VERSION ""

NS_ :

BS_:

BU_: HPCBCM VCU ICU HPCGW IVI MCUM MCUS BMS EVCC DCDC OBC IBS GCU ECM TMS CCM PTC CLOUD GB

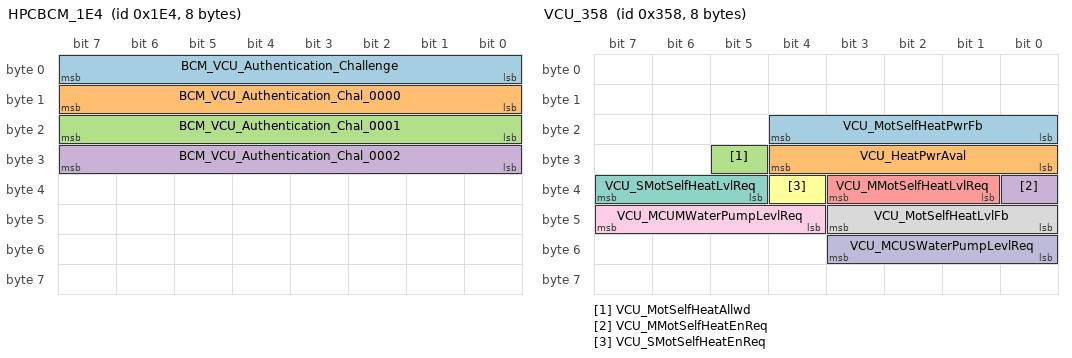
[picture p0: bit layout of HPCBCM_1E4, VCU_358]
BO_ 484 HPCBCM_1E4: 8 HPCBCM
 SG_ BCM_VCU_Authentication_Challenge : 0|8@1+ (1,0) [0|255] "-"  VCU
 SG_ BCM_VCU_Authentication_Chal_0000 : 8|8@1+ (1,0) [0|255] "-"  VCU
 SG_ BCM_VCU_Authentication_Chal_0001 : 16|8@1+ (1,0) [0|255] "-"  VCU
 SG_ BCM_VCU_Authentication_Chal_0002 : 24|8@1+ (1,0) [0|255] "-"  VCU

BO_ 485 VCU_1E5: 32 VCU
 SG_ VCU_BCM_Authentication_MAC_A0 : 0|8@1+ (1,0) [0|255] "-"  HPCBCM
 SG_ VCU_BCM_Authentication_MAC_A1 : 8|8@1+ (1,0) [0|255] "-"  HPCBCM
 SG_ VCU_BCM_Authentication_MAC_A2 : 16|8@1+ (1,0) [0|255] "-"  HPCBCM
 SG_ VCU_BCM_Authentication_MAC_A3 : 24|8@1+ (1,0) [0|255] "-"  HPCBCM
 SG_ VCU_BCM_Authentication_MAC_A4 : 32|8@1+ (1,0) [0|255] "-"  HPCBCM
 SG_ VCU_BCM_Authentication_MAC_A5 : 40|8@1+ (1,0) [0|255] "-"  HPCBCM
 SG_ VCU_BCM_Authentication_MAC_A6 : 48|8@1+ (1,0) [0|255] "-"  HPCBCM
 SG_ VCU_BCM_Authentication_MAC_A7 : 56|8@1+ (1,0) [0|255] "-"  HPCBCM
 SG_ VCU_BCM_Authentication_MAC_A8 : 64|8@1+ (1,0) [0|255] "-"  HPCBCM
 SG_ VCU_BCM_Authentication_MAC_A9 : 72|8@1+ (1,0) [0|255] "-"  HPCBCM
 SG_ VCU_BCM_Authentication_MAC_A10 : 80|8@1+ (1,0) [0|255] "-"  HPCBCM
 SG_ VCU_BCM_Authentication_MAC_A11 : 88|8@1+ (1,0) [0|255] "-"  HPCBCM
 SG_ VCU_BCM_Authentication_MAC_A12 : 96|8@1+ (1,0) [0|255] "-"  HPCBCM
 SG_ VCU_BCM_Authentication_MAC_A13 : 104|8@1+ (1,0) [0|255] "-"  HPCBCM
 SG_ VCU_BCM_Authentication_MAC_A14 : 112|8@1+ (1,0) [0|255] "-"  HPCBCM
 SG_ VCU_BCM_Authentication_MAC_A15 : 120|8@1+ (1,0) [0|255] "-"  HPCBCM
 SG_ VCU_BCM_Authentication_Challenge : 128|8@1+ (1,0) [0|255] "-"  HPCBCM
 SG_ VCU_BCM_Authentication_Chal_0000 : 136|8@1+ (1,0) [0|255] "-"  HPCBCM
 SG_ VCU_BCM_Authentication_Chal_0001 : 144|8@1+ (1,0) [0|255] "-"  HPCBCM
 SG_ VCU_BCM_Authentication_Chal_0002 : 152|8@1+ (1,0) [0|255] "-"  HPCBCM

BO_ 486 HPCBCM_1E6: 16 HPCBCM
 SG_ BCM_VCU_Authentication_MAC_B0 : 0|8@1+ (1,0) [0|255] "-"  VCU
 SG_ BCM_VCU_Authentication_MAC_B1 : 8|8@1+ (1,0) [0|255] "-"  VCU
 SG_ BCM_VCU_Authentication_MAC_B2 : 16|8@1+ (1,0) [0|255] "-"  VCU
 SG_ BCM_VCU_Authentication_MAC_B3 : 24|8@1+ (1,0) [0|255] "-"  VCU
 SG_ BCM_VCU_Authentication_MAC_B4 : 32|8@1+ (1,0) [0|255] "-"  VCU
 SG_ BCM_VCU_Authentication_MAC_B5 : 40|8@1+ (1,0) [0|255] "-"  VCU
 SG_ BCM_VCU_Authentication_MAC_B6 : 48|8@1+ (1,0) [0|255] "-"  VCU
 SG_ BCM_VCU_Authentication_MAC_B7 : 56|8@1+ (1,0) [0|255] "-"  VCU
 SG_ BCM_VCU_Authentication_MAC_B8 : 64|8@1+ (1,0) [0|255] "-"  VCU
 SG_ BCM_VCU_Authentication_MAC_B9 : 72|8@1+ (1,0) [0|255] "-"  VCU
 SG_ BCM_VCU_Authentication_MAC_B10 : 80|8@1+ (1,0) [0|255] "-"  VCU
 SG_ BCM_VCU_Authentication_MAC_B11 : 88|8@1+ (1,0) [0|255] "-"  VCU
 SG_ BCM_VCU_Authentication_MAC_B12 : 96|8@1+ (1,0) [0|255] "-"  VCU
 SG_ BCM_VCU_Authentication_MAC_B13 : 104|8@1+ (1,0) [0|255] "-"  VCU
 SG_ BCM_VCU_Authentication_MAC_B14 : 112|8@1+ (1,0) [0|255] "-"  VCU
 SG_ BCM_VCU_Authentication_MAC_B15 : 120|8@1+ (1,0) [0|255] "-"  VCU

BO_ 223 ICU_DF: 16 ICU
 SG_ ICU_CRC_DF : 0|8@1+ (1,0) [0|255] "-"  VCU
 SG_ ICU_RollingCounter_DF : 8|4@1+ (1,0) [0|15] "-"  VCU
 SG_ ICU_IMU_ACC_x : 16|16@1+ (0.00195313,-64) [-64|64] "m/s2"  VCU
 SG_ ICU_IMU_ACC_y : 32|16@1+ (0.00195313,-64) [-64|64] "m/s2"  VCU
 SG_ ICU_IMU_ACC_z : 48|16@1+ (0.00195313,-64) [-64|64] "m/s2"  VCU
 SG_ ICU_IMU_ACC_Roll_Rate : 64|16@1+ (0.01,-327.68) [-327.7|327.7] "deg/s"  VCU
 SG_ ICU_IMU_ACC_Pitch_Rate : 80|16@1+ (0.01,-327.68) [-327.7|327.7] "deg/s"  VCU
 SG_ ICU_IMU_ACC_Yaw_Rate : 96|16@1+ (0.01,-327.68) [-327.7|327.7] "deg/s"  VCU
 SG_ ICU_IMU_Calibrated : 112|2@1+ (1,0) [0|2] "-"  VCU
 SG_ ICU_IMU_Valid : 114|1@1+ (1,0) [0|1] "-"  VCU

BO_ 315 VCU_13B: 32 VCU
 SG_ VCU_CRC_13B : 0|8@1+ (1,0) [0|255] "-"  HPCGW,HPCBCM,MCUM,MCUS,BMS,DCDC,GCU,ECM,TMS,CCM,PTC
 SG_ VCU_RollingCounter_13B : 8|4@1+ (1,0) [0|15] "-"  HPCGW,HPCBCM,MCUM,MCUS,BMS,DCDC,GCU,ECM,TMS,CCM,PTC
 SG_ VCU_Vehicle_Warning : 16|2@1+ (1,0) [0|3] "-"  CLOUD,GB,HPCBCM,BMS
 SG_ VCU_VehicleSts : 18|1@1+ (1,0) [0|1] "-"  CLOUD,HPCGW,MCUM,MCUS,BMS,DCDC,GCU,ECM,TMS,PTC
 SG_ VCU_GearLevelPosSts : 19|2@1+ (1,0) [0|3] "-"  CLOUD,GB,HPCGW,MCUM,MCUS,ECM,TMS
 SG_ VCU_GearLeverValid : 21|1@1+ (1,0) [0|1] "-"  CLOUD,MCUM,MCUS,ECM
 SG_ VCU_AccPedalValid : 23|1@1+ (1,0) [0|1] "-"  CLOUD,HPCGW,MCUM,MCUS,ECM
 SG_ VCU_ThrottlePosition : 24|8@1+ (0.393,0) [0|100] "%"  CLOUD,GB,HPCGW,MCUM,MCUS,ECM
 SG_ VCU_BMSMainRelayR_Cmd : 32|1@1+ (1,0) [0|1] "-"  CLOUD,BMS
 SG_ VCU_BMSMainRelayF_Cmd : 33|1@1+ (1,0) [0|1] "-"  CLOUD,BMS
 SG_ VCU_BMSEmergencyCmd : 34|1@1+ (1,0) [0|1] "-"  CLOUD,BMS
 SG_ VCU_MCUMActiveReleaseCmd : 35|1@1+ (1,0) [0|1] "-"  CLOUD,MCUM
 SG_ VCU_MCUSActiveReleaseCmd : 36|1@1+ (1,0) [0|1] "-"  CLOUD,MCUS
 SG_ VCU_AlwACChargeInventerSts : 37|1@1+ (1,0) [0|1] "-"  CLOUD,BMS
 SG_ VCU_AlwDCChargeSts : 38|1@1+ (1,0) [0|1] "-"  CLOUD,BMS
 SG_ VCU_ChargePauseReq : 39|1@1+ (1,0) [0|1] "-"  CLOUD,BMS
 SG_ VCU_SuppressJitterMCUSRequest : 40|1@1+ (1,0) [0|1] "-"  CLOUD,MCUS
 SG_ VCU_DCDCEnableCmd : 41|1@1+ (1,0) [0|1] "-"  CLOUD,BMS,DCDC
 SG_ VCU_ACOffReq : 42|2@1+ (1,0) [0|3] "-"  CLOUD,TMS
 SG_ VCU_VehicleDirect : 44|1@1+ (1,0) [0|1] "-"  CLOUD,MCUM,MCUS
 SG_ VCU_BrakeSysFault : 45|1@1+ (1,0) [0|1] "-"  CLOUD,GB,HPCGW
 SG_ VCU_SuppressJitterMCUMRequest : 46|1@1+ (1,0) [0|1] "-"  CLOUD,MCUM
 SG_ VCU_MDrvControlMode : 47|1@1+ (1,0) [0|1] "-"  CLOUD,MCUM
 SG_ VCU_BrakePedalValue : 48|8@1+ (0.393,0) [0|100] "%"  CLOUD,MCUM,MCUS
 SG_ VCU_MCUMMaxDischargePower : 56|9@1+ (1,0) [0|510] "kw"  CLOUD,MCUM
 SG_ VCU_MCUMMaxChargePower : 71|9@1+ (1,0) [0|510] "kw"  CLOUD,MCUM
 SG_ VCU_MDrvRequestTorque : 80|16@1+ (0.1,-500) [-500|500] "N·m"  CLOUD,MCUM
 SG_ VCU_MDrvRequesSpeed : 96|16@1+ (1,-17000) [-17000|30000] "rpm"  CLOUD,MCUM
 SG_ VCU_SDrvRequestTorque : 112|16@1+ (0.1,-500) [-500|500] "N·m"  CLOUD,MCUM,MCUS
 SG_ VCU_SDrvRequesSpeed : 128|16@1+ (1,-17000) [-17000|30000] "rpm"  CLOUD,MCUM,MCUS
 SG_ VCU_SVehicleSts : 144|1@1+ (1,0) [0|1] "-"  CLOUD,MCUM,MCUS
 SG_ VCU_VehicleHighVoltModeF : 145|3@1+ (1,0) [0|7] "-"  CLOUD
 SG_ VCU_SDrvControlMode : 148|1@1+ (1,0) [0|1] "-"  CLOUD,MCUM,MCUS
 SG_ VCU_ON2BRelayReq : 149|2@1+ (1,0) [0|3] "-"  CLOUD,MCUM,MCUS
 SG_ VCU_VehPreHVPwrOffCmd : 151|1@1+ (1,0) [0|1] "-"  CLOUD,MCUM,MCUS,BMS,TMS,CCM,PTC
 SG_ VCU_FuelTankLockReq : 152|2@1+ (1,0) [0|3] "-"  CLOUD,HPCGW
 SG_ VCU_VehicleDirectS : 154|1@1+ (1,0) [0|1] "-"  CLOUD,MCUS
 SG_ VCU_VehicleDirectS_VD : 155|1@1+ (1,0) [0|1] "-"  CLOUD,MCUS
 SG_ VCU_ACPwrLimited : 160|8@1+ (0.1,0) [0|25.5] "kW"  CLOUD,TMS
 SG_ VCU_MCUSMaxDischargePower : 168|9@1+ (1,0) [0|510] "kw"  CLOUD,MCUS
 SG_ VCU_VehicleDirectVD : 177|1@1+ (1,0) [0|1] "-"  CLOUD,MCUM,MCUS
 SG_ VCU_MDrvControlModeVD : 178|1@1+ (1,0) [0|1] "-"  CLOUD,MCUM,MCUS
 SG_ VCU_MDrvRequestTorqueVD : 179|1@1+ (1,0) [0|1] "-"  CLOUD,MCUM,MCUS
 SG_ VCU_MDrvRequesSpeedVD : 180|1@1+ (1,0) [0|1] "-"  CLOUD,MCUM,MCUS
 SG_ VCU_SDrvRequestTorqueVD : 181|1@1+ (1,0) [0|1] "-"  CLOUD,MCUM,MCUS
 SG_ VCU_SDrvRequesSpeedVD : 182|1@1+ (1,0) [0|1] "-"  CLOUD,MCUM,MCUS
 SG_ VCU_SDrvControlModeVD : 183|1@1+ (1,0) [0|1] "-"  CLOUD,MCUM,MCUS
 SG_ VCU_MCUSMaxChargePower : 184|9@1+ (1,0) [0|510] "kw"  CLOUD,MCUS
 SG_ VCU_VehicleHighVoltMode : 193|3@1+ (1,0) [0|7] "-"  CLOUD,ICU
 SG_ VCU_PDUHVIL_Sts : 196|1@1+ (1,0) [0|1] "-"  CLOUD
 SG_ VCU_PDU220VRelay_Req : 197|1@1+ (1,0) [0|1] "-"  CLOUD,HPCGW
 SG_ VCU_Cab220VRelay_Req : 198|1@1+ (1,0) [0|1] "-"  CLOUD,HPCGW
 SG_ VCU_Cabin220VRelay_Req : 199|1@1+ (1,0) [0|1] "-"  CLOUD,HPCGW
 SG_ VCU_Alw_Cab220VInverter_Sts : 200|1@1+ (1,0) [0|1] "-"  CLOUD,BMS
 SG_ VCU_Alw_Cabin220VInverter_Sts : 201|1@1+ (1,0) [0|1] "-"  CLOUD,BMS
 SG_ VCU_MCUMDampgLmtFactor : 202|7@1+ (1,0) [0|100] "%"  CLOUD,MCUM
 SG_ VCU_MCUSDampgLmtFactor : 209|7@1+ (1,0) [0|100] "%"  CLOUD,MCUS
 SG_ VCU_BCM_Authentication_Sts : 216|2@1+ (1,0) [0|3] "-"  CLOUD
 SG_ VCU_AuthenticationKey_WSts : 218|1@1+ (1,0) [0|1] "-"  CLOUD
 SG_ VCU_BrakePedalSts_P : 219|1@1+ (1,0) [0|1] "-"  CLOUD
 SG_ VCU_BrakePedalStsValid_P : 220|1@1+ (1,0) [0|1] "-"  CLOUD
 SG_ VCU_BoostMode_Fail : 221|3@1+ (1,0) [0|7] "-"  CLOUD,MCUM,BMS,TMS
 SG_ VCU_BoostModeSts : 224|2@1+ (1,0) [0|3] "-"  CLOUD,MCUM,BMS,TMS
 SG_ VCU_MCUSMaxPosDampgTrq : 232|6@1+ (1,0) [0|50] "Nm"  CLOUD,MCUS
 SG_ VCU_MCUSMaxNegDampgTrq : 238|6@1+ (1,-50) [-50|0] "Nm"  CLOUD,MCUS
 SG_ VCU_MCUMMaxPosDampgTrq : 244|6@1+ (1,0) [0|50] "Nm"  CLOUD,MCUM
 SG_ VCU_MCUMMaxNegDampgTrq : 250|6@1+ (1,-50) [-50|0] "Nm"  CLOUD,MCUM

BO_ 188 VCU_BC: 16 VCU
 SG_ VCU_VehicleSpdDirect : 16|9@1+ (1,-255) [-255|255] "-"  CLOUD
 SG_ VCU_DeliveryModeSts : 25|1@1+ (1,0) [0|1] "-"  CLOUD,IVI,BMS
 SG_ VCU_VehSpdLimtRemind : 26|1@1+ (1,0) [0|1] "-"  CLOUD
 SG_ VCU_SinglePedalSts : 27|1@1+ (1,0) [0|1] "-"  CLOUD
 SG_ VCU_GearLvrChangeSts : 28|4@1+ (1,0) [0|15] "-"  CLOUD
 SG_ VCU_HighVoltSysSts : 32|4@1+ (1,0) [0|15] "-"  CLOUD
 SG_ VCU_ChrgDischrgFunSts : 36|4@1+ (1,0) [0|15] "-"  CLOUD
 SG_ VCU_CalibrationVersion : 40|4@1+ (1,0) [0|15] "-"  CLOUD
 SG_ VCU_CalibrationNumber : 44|3@1+ (1,0) [0|7] "-"  CLOUD
 SG_ VCU_VehicleNegTrqRspdSts : 47|1@1+ (1,0) [0|1] "-"  CLOUD
 SG_ VCU_SlopeEst : 48|10@1+ (0.5,-100) [-100|100] "%"  CLOUD
 SG_ VCU_SlopeEst_Valid : 58|1@1+ (1,0) [0|1] "-"  CLOUD
 SG_ VCU_WheelTrqType : 60|4@1+ (1,0) [0|15] "-"  CLOUD
 SG_ VCU_DriverAssistProhibitSts : 64|1@1+ (1,0) [0|1] "-"  CLOUD
 SG_ VCU_VacumRlySts : 65|1@1+ (1,0) [0|1] "-"  CLOUD
 SG_ VCU_DriveSHVILSts : 66|1@1+ (1,0) [0|1] "-"  CLOUD
 SG_ VCU_DriveMHVILSts : 67|1@1+ (1,0) [0|1] "-"  CLOUD
 SG_ VCU_DCChgHVILSts : 68|1@1+ (1,0) [0|1] "-"  CLOUD
 SG_ VCU_ACChgHVILSts : 69|1@1+ (1,0) [0|1] "-"  CLOUD
 SG_ VCU_CCMHVILSts : 70|1@1+ (1,0) [0|1] "-"  CLOUD
 SG_ VCU_SystemError : 71|1@1+ (1,0) [0|1] "-"  CLOUD
 SG_ VCU_AccPedalFaultLV : 72|3@1+ (1,0) [0|7] "-"  CLOUD
 SG_ VCU_HVILSysSts : 76|4@1+ (1,0) [0|15] "-"  CLOUD
 SG_ VCU_VacuumDegree : 80|8@1+ (0.393,0) [0|100] "%"  CLOUD
 SG_ VCU_LPedalModeSts : 88|2@1+ (1,0) [0|3] "-"  CLOUD
 SG_ VCU_LVSystemError : 90|1@1+ (1,0) [0|1] "-"  CLOUD
 SG_ VCU_HVSystemError : 91|1@1+ (1,0) [0|1] "-"  CLOUD
 SG_ VCU_OpeartingMode : 92|2@1+ (1,0) [0|3] "-"  CLOUD
 SG_ VCU_EnergyMode : 94|3@1+ (1,0) [0|7] "-"  CLOUD,GB,HPCGW
 SG_ VCU_GearLevelPosFault : 97|1@1+ (1,0) [0|1] "-"  CLOUD
 SG_ VCU_BrakeSwitchSts : 98|2@1+ (1,0) [0|3] "-"  CLOUD
 SG_ VCU_SpdLimModeSts : 100|2@1+ (1,0) [0|3] "-"  CLOUD,IVI
 SG_ VCU_TrqDstrbutnPrio : 102|3@1+ (1,0) [0|7] "-"  CLOUD
 SG_ VCU_TrqDstrbutnTransferSts : 105|3@1+ (1,0) [0|7] "-"  CLOUD
 SG_ VCU_MCUMDiffProtectSts : 108|1@1+ (1,0) [0|1] "-"  CLOUD
 SG_ VCU_MCUSDiffProtectSts : 109|1@1+ (1,0) [0|1] "-"  CLOUD
 SG_ VCU_ADM_MainMode : 110|2@1+ (1,0) [0|3] "-"  CLOUD
 SG_ VCU_ADM_ActualMode : 112|2@1+ (1,0) [0|3] "-"  CLOUD

BO_ 856 VCU_358: 8 VCU
 SG_ VCU_MotSelfHeatPwrFb : 16|5@1+ (1,0) [0|31] "kw"  CLOUD,TMS
 SG_ VCU_HeatPwrAval : 24|5@1+ (1,0) [0|31] "kw"  CLOUD,TMS
 SG_ VCU_MotSelfHeatAllwd : 29|1@1+ (1,0) [0|1] "-"  CLOUD,TMS
 SG_ VCU_MMotSelfHeatEnReq : 32|1@1+ (1,0) [0|1] "-"  CLOUD,MCUM
 SG_ VCU_MMotSelfHeatLvlReq : 33|3@1+ (1,0) [0|7] "-"  CLOUD,MCUM
 SG_ VCU_SMotSelfHeatEnReq : 36|1@1+ (1,0) [0|1] "-"  CLOUD,MCUS
 SG_ VCU_SMotSelfHeatLvlReq : 37|3@1+ (1,0) [0|7] "-"  CLOUD,MCUS
 SG_ VCU_MotSelfHeatLvlFb : 40|4@1+ (1,0) [0|15] "-"  CLOUD,TMS
 SG_ VCU_MCUMWaterPumpLevlReq : 44|4@1+ (10,0) [0|100] "%"  CLOUD,MCUM
 SG_ VCU_MCUSWaterPumpLevlReq : 48|4@1+ (10,0) [0|100] "%"  CLOUD,MCUS

BO_ 1300 VCU_514: 8 VCU
 SG_ VCU_FuelConsumption : 0|8@1+ (4,0) [0|1020] "ul/100ms"  CLOUD,IVI
 SG_ VCU_SVSLamp : 8|1@1+ (1,0) [0|1] "-"  CLOUD,IVI
 SG_ VCU_MilLamp : 9|1@1+ (1,0) [0|1] "-"  CLOUD,IVI,ICU
 SG_ VCU_SinglePedalSts : 10|1@1+ (1,0) [0|1] "-"  CLOUD,ICU
 SG_ VCU_GearLevelPosFault : 11|1@1+ (1,0) [0|1] "-"  CLOUD,ICU
 SG_ VCU_EngineStartFailure : 12|1@1+ (1,0) [0|1] "-"  CLOUD,IVI,ICU,ECM
 SG_ VCU_ParkBeforeFuelup : 13|1@1+ (1,0) [0|1] "-"  CLOUD,IVI,ICU
 SG_ VCU_REsystemFaultSts : 14|1@1+ (1,0) [0|1] "-"  CLOUD,IVI,ICU
 SG_ VCU_EngineRunAllowFlg : 15|1@1+ (1,0) [0|1] "-"  CLOUD,IVI
 SG_ VCU_InverterTip : 16|3@1+ (1,0) [0|7] "-"  CLOUD,IVI,ICU
 SG_ VCU_EMSRepairModeSts : 19|2@1+ (1,0) [0|3] "-"  CLOUD,IVI,ICU
 SG_ VCU_FuelTankFlapSts : 21|1@1+ (1,0) [0|1] "-"  CLOUD,IVI,ICU
 SG_ VCU_REsystemSts : 22|1@1+ (1,0) [0|1] "-"  CLOUD,IVI
 SG_ VCU_PowerModeAllow : 23|2@1+ (1,0) [0|3] "-"  CLOUD,IVI
 SG_ VCU_PowerModeSwitchMsg : 25|1@1+ (1,0) [0|1] "-"  CLOUD,IVI
 SG_ VCU_HighVoltFailed_M : 26|1@1+ (1,0) [0|1] "-"  CLOUD,IVI
 SG_ VCU_HighVoltFailed_S : 27|1@1+ (1,0) [0|1] "-"  CLOUD,IVI
 SG_ VCU_BrakeBeforeGear : 28|1@1+ (1,0) [0|1] "-"  CLOUD,IVI,ICU
 SG_ VCU_ParkBeforeGear : 29|1@1+ (1,0) [0|1] "-"  CLOUD,IVI,ICU
 SG_ VCU_GearBeforDriving : 30|1@1+ (1,0) [0|1] "-"  CLOUD,IVI,ICU
 SG_ VCU_UnlockBeforeDriving : 31|1@1+ (1,0) [0|1] "-"  CLOUD,IVI,ICU
 SG_ VCU_PreventSliding : 32|1@1+ (1,0) [0|1] "-"  CLOUD,IVI,ICU
 SG_ VCU_MMErrorSts : 33|1@1+ (1,0) [0|1] "-"  CLOUD,IVI
 SG_ VCU_ShowCarModeSts : 34|1@1+ (1,0) [0|1] "-"  CLOUD,IVI,ICU
 SG_ VCU_PGearFlashSts : 35|1@1+ (1,0) [0|1] "-"  CLOUD,IVI,ICU
 SG_ VCU_ACConnectSts : 36|1@1+ (1,0) [0|1] "-"  CLOUD,IVI,ICU
 SG_ VCU_DcChgPwrSts : 37|1@1+ (1,0) [0|1] "-"  CLOUD,IVI
 SG_ VCU_DriverAssistProhibitSts : 38|1@1+ (1,0) [0|1] "-"  CLOUD
 SG_ VCU_MilLampRequest : 39|1@1+ (1,0) [0|1] "-"  CLOUD
 SG_ VCU_CcmHvilInSigFreq_FB : 40|8@1+ (1,0) [0|200] "Hz"  CLOUD
 SG_ VCU_CcmHvilInSigDuty_FB : 48|8@1+ (1,0) [0|100] "pct"  CLOUD
 SG_ VCU_FuelDectionModeSts : 56|2@1+ (1,0) [0|3] "-"  CLOUD,IVI,ICU
 SG_ VCU_EnergyCtrlMode : 58|1@1+ (1,0) [0|1] "-"  CLOUD,IVI,ICU
 SG_ VCU_VehSpdLimtRemind : 59|1@1+ (1,0) [0|1] "-"  CLOUD,ICU
 SG_ VCU_TurtleLamp : 60|1@1+ (1,0) [0|1] "-"  CLOUD,ICU
 SG_ VCU_EngLongTimeStartReq : 61|1@1+ (1,0) [0|1] "-"  CLOUD,IVI

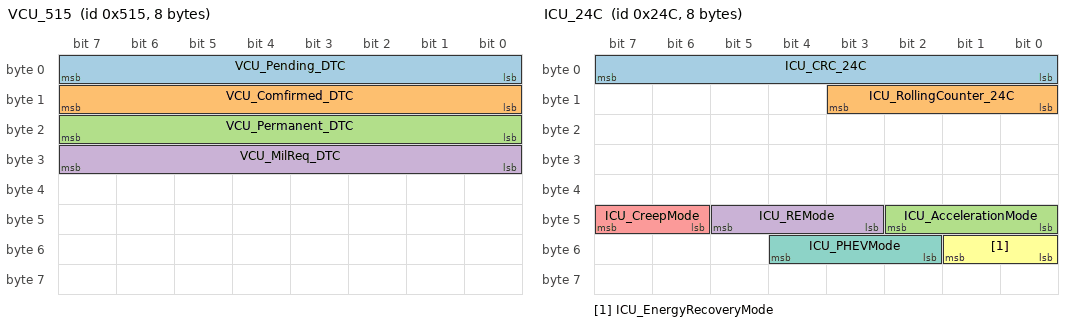
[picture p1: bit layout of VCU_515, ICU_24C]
BO_ 1301 VCU_515: 8 VCU
 SG_ VCU_Pending_DTC : 0|8@1+ (1,0) [0|254] "-"  CLOUD
 SG_ VCU_Comfirmed_DTC : 8|8@1+ (1,0) [0|254] "-"  CLOUD
 SG_ VCU_Permanent_DTC : 16|8@1+ (1,0) [0|254] "-"  CLOUD
 SG_ VCU_MilReq_DTC : 24|8@1+ (1,0) [0|254] "-"  CLOUD

BO_ 588 ICU_24C: 8 ICU
 SG_ ICU_CRC_24C : 0|8@1+ (1,0) [0|255] "-"  VCU,MCUM,MCUS,BMS,GCU,ECM,TMS
 SG_ ICU_RollingCounter_24C : 8|4@1+ (1,0) [0|15] "-"  VCU,MCUM,MCUS,BMS,GCU,ECM,TMS
 SG_ ICU_AccelerationMode : 40|3@1+ (1,0) [0|7] "-"  CLOUD,VCU,MCUM,MCUS,TMS
 SG_ ICU_REMode : 43|3@1+ (1,0) [0|7] "-"  CLOUD,IVI,VCU,BMS
 SG_ ICU_CreepMode : 46|2@1+ (1,0) [0|3] "-"  VCU
 SG_ ICU_EnergyRecoveryMode : 48|2@1+ (1,0) [0|3] "-"  VCU
 SG_ ICU_PHEVMode : 50|3@1+ (1,0) [0|7] "-"  IVI,VCU

BO_ 585 ICU_249: 64 ICU
 SG_ ICU_TotalOilmeterkm : 44|20@1+ (1,0) [0|999999] "km"  VCU
 SG_ ICU_CLTCoilMileage : 64|11@1+ (1,0) [0|2000] "km"  VCU
 SG_ ICU_WLTC_oilMileage : 75|11@1+ (1,0) [0|2000] "km"  VCU
 SG_ ICU_CLTC_ElectticityMileage : 86|11@1+ (1,0) [0|2000] "km"  VCU
 SG_ ICU_WLTC_ElectticityMileage : 97|11@1+ (1,0) [0|2000] "km"  VCU
 SG_ ICU_Switch_CLTCOrWLTC : 128|3@1+ (1,0) [0|7] "-"  VCU
 SG_ ICU_FuelPercent : 135|10@1+ (0.1,0) [0|100] "%"  VCU

BO_ 657 HPCBCM_291: 16 HPCBCM
 SG_ BCM_CRC_291 : 0|8@1+ (1,0) [0|255] "-"  VCU,MCUM,MCUS,BMS,GCU,ECM,IBS,TMS
 SG_ BCM_RollingCounter_291 : 8|4@1+ (1,0) [0|15] "-"  VCU,MCUM,MCUS,BMS,GCU,ECM,IBS,TMS
 SG_ BCM_ShutdownMode : 15|1@1+ (1,0) [0|1] " -"  VCU
 SG_ BCM_KeyPosition_ON2A : 18|1@1+ (1,0) [0|1] "-"  VCU,MCUM,MCUS,BMS,GCU,ECM
 SG_ BCM_CcmHvilSts : 22|1@1+ (1,0) [0|1] "-"  VCU
 SG_ BCM_ON2BRelaySts : 30|1@1+ (1,0) [0|1] "-"  VCU,MCUM,MCUS
 SG_ BCM_ON2CRelaySts : 31|1@1+ (1,0) [0|1] "-"  VCU,MCUM,MCUS
 SG_ BCM_ON2InitiativeSts : 35|1@1+ (1,0) [0|1] "-"  VCU
 SG_ BCM_VehicleRepairMode : 36|1@1+ (1,0) [0|1] "-"  VCU
 SG_ BCM_VehlockCtrl : 37|2@1+ (1,0) [0|3] "-"  VCU
 SG_ BCM_VehLockSts : 39|1@1+ (1,0) [0|1] "-"  VCU,TMS
 SG_ BCM_FuelTankLockReq : 40|2@1+ (1,0) [0|3] "-"  VCU
 SG_ BCM_ACChgLockCtrl : 42|2@1+ (1,0) [0|3] "-"  VCU
 SG_ BCM_ChargeLockCtrl : 44|2@1+ (1,0) [0|3] "-"  VCU
 SG_ BCM_DCChrgPwr_Sts : 46|1@1+ (1,0) [0|1] "-"  VCU
 SG_ BCM_ACChrgPwr_Sts : 47|1@1+ (1,0) [0|1] "-"  VCU
 SG_ BCM_DCChrgPwr_Volt : 48|8@1+ (0.2,0) [0|51] "-"  VCU
 SG_ BCM_ACChrgPwr_Volt : 56|8@1+ (0.2,0) [0|51] "-"  VCU
 SG_ BCM_KeyPosition_ON2B : 64|1@1+ (1,0) [0|1] "-"  VCU,MCUM,MCUS,GCU,TMS
 SG_ BCM_NM_PNC_ON_1ADr_Sts : 67|1@1+ (1,0) [0|1] "-"  VCU,TMS
 SG_ BCM_NM_PNC_ON_3Ch_Sts : 73|1@1+ (1,0) [0|1] "-"  VCU,BMS,TMS
 SG_ BCM_HighVoltageReq : 114|2@1+ (1,0) [0|3] " -"  CLOUD,VCU

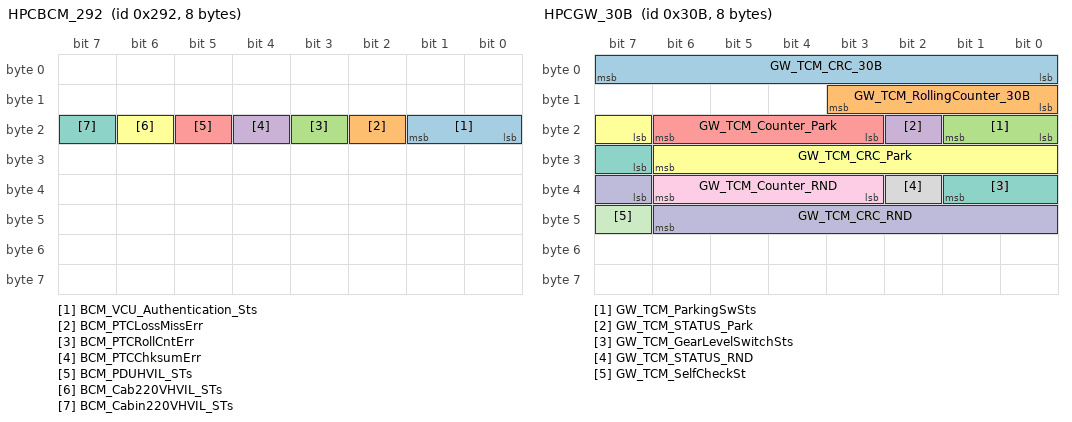
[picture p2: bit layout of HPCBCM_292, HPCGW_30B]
BO_ 658 HPCBCM_292: 8 HPCBCM
 SG_ BCM_VCU_Authentication_Sts : 16|2@1+ (1,0) [0|3] "-"  CLOUD,VCU
 SG_ BCM_PTCLossMissErr : 18|1@1+ (1,0) [0|1] "-"  CLOUD,VCU
 SG_ BCM_PTCRollCntErr : 19|1@1+ (1,0) [0|1] "-"  CLOUD,VCU
 SG_ BCM_PTCChksumErr : 20|1@1+ (1,0) [0|1] "-"  CLOUD,VCU
 SG_ BCM_PDUHVIL_STs : 21|1@1+ (1,0) [0|1] "-"  CLOUD,VCU
 SG_ BCM_Cab220VHVIL_STs : 22|1@1+ (1,0) [0|1] "-"  CLOUD,VCU
 SG_ BCM_Cabin220VHVIL_STs : 23|1@1+ (1,0) [0|1] "-"  CLOUD,VCU

BO_ 945 HPCGW_3B1: 32 HPCGW
 SG_ GW_CRC_3B1 : 0|8@1+ (1,0) [0|255] "-"  VCU,MCUM,MCUS,BMS,ECM
 SG_ GW_RollingCounter_3B1 : 8|4@1+ (1,0) [0|15] "-"  VCU,MCUM,MCUS,BMS,ECM
 SG_ GW_ZCUB_DCChgExitTemp_Pos : 56|8@1+ (1,-40) [-40|210] "℃"  VCU,BMS
 SG_ GW_ZCUB_DCChgExitTemp_Neg : 64|8@1+ (1,-40) [-40|210] "℃"  VCU,BMS
 SG_ GW_ZCUB_ACChgExitTemp_Pos : 72|8@1+ (1,-40) [-40|210] "℃"  VCU,BMS
 SG_ GW_ZCUB_FuelTankSts : 94|1@1+ (1,0) [0|1] "-"  VCU,ECM
 SG_ GW_ZCUB_ACChgExitTemp_Neg : 152|8@1+ (1,-40) [-40|210] "℃"  VCU,BMS
 SG_ GW_ZCUB_FuelTankStsLockSts : 204|2@1+ (1,0) [0|3] "-"  VCU
 SG_ GW_ZCUB_FuelTankLockCtrl : 206|2@1+ (1,0) [0|3] "-"  VCU
 SG_ GW_ZCUB_ACChgLockSts : 208|2@1+ (1,0) [0|3] "-"  VCU,BMS
 SG_ GW_RZCU_Cabin_220Vconnect_Sts : 210|1@1+ (1,0) [0|1] "-"  VCU,BMS
 SG_ GW_ZCUB_Cab_220VRelay_CtrlSts : 211|1@1+ (1,0) [0|1] "-"  VCU
 SG_ GW_ZCUB_Cab_PDU220VRelay_CtrlSts : 212|1@1+ (1,0) [0|1] "-"  VCU
 SG_ GW_ZCUB_Cabin_220VRelay_CtrlSts : 213|1@1+ (1,0) [0|1] "-"  VCU
 SG_ GW_ZCUB_Cab_220Vconnect_Sts : 214|1@1+ (1,0) [0|1] "-"  VCU,BMS
 SG_ GW_TBOXSOC_Altitude : 236|14@1+ (1,-1000) [-1000|10000] "m"  VCU

BO_ 779 HPCGW_30B: 8 HPCGW
 SG_ GW_TCM_CRC_30B : 0|8@1+ (1,0) [0|255] "-"  VCU
 SG_ GW_TCM_RollingCounter_30B : 8|4@1+ (1,0) [0|15] "-"  VCU
 SG_ GW_TCM_ParkingSwSts : 16|2@1+ (1,0) [0|3] "-"  VCU
 SG_ GW_TCM_STATUS_Park : 18|1@1+ (1,0) [0|1] "-"  VCU
 SG_ GW_TCM_Counter_Park : 19|4@1+ (1,0) [0|15] "-"  VCU
 SG_ GW_TCM_CRC_Park : 23|8@1+ (1,0) [0|255] "-"  VCU
 SG_ GW_TCM_GearLevelSwitchSts : 31|3@1+ (1,0) [0|7] "-"  VCU
 SG_ GW_TCM_STATUS_RND : 34|1@1+ (1,0) [0|1] "-"  VCU
 SG_ GW_TCM_Counter_RND : 35|4@1+ (1,0) [0|15] "-"  VCU
 SG_ GW_TCM_CRC_RND : 39|8@1+ (1,0) [0|255] "-"  VCU
 SG_ GW_TCM_SelfCheckSt : 47|1@1+ (1,0) [0|1] "-"  VCU

BO_ 842 IVI_34A: 8 IVI
 SG_ IVI_DeliveryModeReq : 20|2@1+ (1,0) [0|3] "-"  VCU
 SG_ IVI_ShowCarModeReq : 22|2@1+ (1,0) [0|3] "-"  VCU

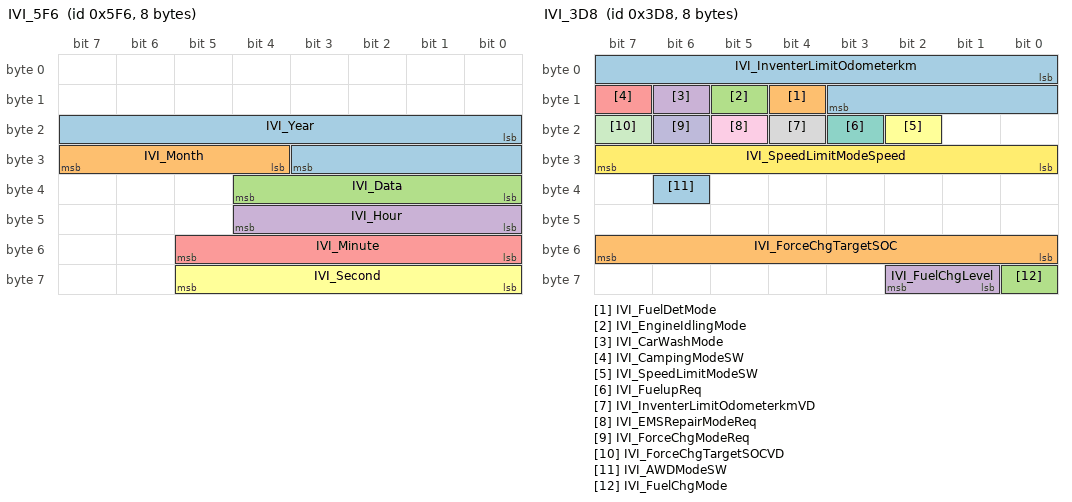
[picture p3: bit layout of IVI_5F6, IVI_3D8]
BO_ 1526 IVI_5F6: 8 IVI
 SG_ IVI_Year : 16|12@1+ (1,0) [0|4094] "-"  VCU,MCUM,MCUS,BMS,GCU,ECM,IBS,TMS
 SG_ IVI_Month : 28|4@1+ (1,0) [0|12] "-"  VCU,MCUM,MCUS,BMS,GCU,ECM,IBS,TMS
 SG_ IVI_Data : 32|5@1+ (1,0) [0|31] "-"  VCU,MCUM,MCUS,BMS,GCU,ECM,IBS,TMS
 SG_ IVI_Hour : 40|5@1+ (1,0) [0|23] "-"  VCU,MCUM,MCUS,BMS,GCU,ECM,IBS,TMS
 SG_ IVI_Minute : 48|6@1+ (1,0) [0|59] "-"  VCU,MCUM,MCUS,BMS,GCU,ECM,IBS,TMS
 SG_ IVI_Second : 56|6@1+ (1,0) [0|59] "-"  VCU,MCUM,MCUS,BMS,GCU,ECM,IBS,TMS

BO_ 984 IVI_3D8: 8 IVI
 SG_ IVI_InventerLimitOdometerkm : 0|12@1+ (1,0) [0|4000] "km"  VCU
 SG_ IVI_FuelDetMode : 12|1@1+ (1,0) [0|1] "-"  VCU
 SG_ IVI_EngineIdlingMode : 13|1@1+ (1,0) [0|1] "-"  VCU
 SG_ IVI_CarWashMode : 14|1@1+ (1,0) [0|1] "-"  VCU
 SG_ IVI_CampingModeSW : 15|1@1+ (1,0) [0|1] "-"  VCU
 SG_ IVI_SpeedLimitModeSW : 18|1@1+ (1,0) [0|1] "-"  VCU
 SG_ IVI_FuelupReq : 19|1@1+ (1,0) [0|1] "-"  VCU
 SG_ IVI_InventerLimitOdometerkmVD : 20|1@1+ (1,0) [0|1] "-"  VCU
 SG_ IVI_EMSRepairModeReq : 21|1@1+ (1,0) [0|1] "-"  VCU
 SG_ IVI_ForceChgModeReq : 22|1@1+ (1,0) [0|1] "-"  VCU
 SG_ IVI_ForceChgTargetSOCVD : 23|1@1+ (1,0) [0|1] "-"  VCU
 SG_ IVI_SpeedLimitModeSpeed : 24|8@1+ (1,0) [1|180] "KM"  VCU
 SG_ IVI_AWDModeSW : 38|1@1+ (1,0) [0|1] "-"  VCU
 SG_ IVI_ForceChgTargetSOC : 48|8@1+ (1,0) [0|100] "%"  VCU
 SG_ IVI_FuelChgMode : 56|1@1+ (1,0) [0|1] "-"  CLOUD,VCU
 SG_ IVI_FuelChgLevel : 57|2@1+ (1,0) [0|3] "-"  CLOUD,VCU

BO_ 202 MCUM_CA: 32 MCUM
 SG_ MCUM_CRC_CA : 0|8@1+ (1,0) [0|255] "-"  HPCGW,ICU,VCU,BMS,TMS
 SG_ MCUM_RollingCounter_CA : 8|4@1+ (1,0) [0|15] "-"  HPCGW,ICU,VCU,BMS,TMS
 SG_ MCUM_WarningLevel : 16|2@1+ (1,0) [0|3] "-"  CLOUD,IVI,ICU,VCU
 SG_ MCUM_SelfCheckSts : 18|2@1+ (1,0) [0|3] "-"  CLOUD,ICU,VCU
 SG_ MCUM_DrvMotorWorkSts : 20|2@1+ (1,0) [0|3] "-"  CLOUD,GB,HPCGW,VCU
 SG_ MCUM_PowerReduceSts : 22|1@1+ (1,0) [0|1] "-"  CLOUD,VCU
 SG_ MCUM_DrvMotorRPM : 24|16@1+ (1,-17000) [-17000|30000] "rpm"  CLOUD,GB,HPCGW,ICU,VCU
 SG_ MCUM_ActualTorqueFB : 40|16@1+ (0.1,-500) [-500|500] "N·m"  CLOUD,GB,HPCGW,VCU
 SG_ MCUM_HWRdcFault : 56|1@1+ (1,0) [0|1] "-"  CLOUD,HPCGW,ICU,VCU
 SG_ MCUM_HighVoltPowerOffReq : 58|1@1+ (1,0) [0|1] "-"  CLOUD,VCU
 SG_ MCUM_HVILSts : 59|1@1+ (1,0) [0|1] "-"  CLOUD,VCU
 SG_ MCUM_DragSts : 60|2@1+ (1,0) [0|3] "-"  CLOUD,VCU
 SG_ MCUM_CtrlMode : 62|1@1+ (1,0) [0|1] "-"  CLOUD,VCU
 SG_ MCUM_MILlampReq : 65|1@1+ (1,0) [0|1] "-"  CLOUD,VCU
 SG_ MCUM_DrvMotorRPMVD : 68|1@1+ (1,0) [0|1] "-"  CLOUD,VCU
 SG_ MCUM_ActualTorqueFBVD : 69|1@1+ (1,0) [0|1] "-"  CLOUD,VCU
 SG_ MCUM_MaxTorqueAllow : 72|16@1+ (0.1,-500) [-500|500] "N·m"  CLOUD,VCU
 SG_ MCUM_MaxSpeedAllow : 88|16@1+ (1,-17000) [-17000|30000] "rpm"  CLOUD,VCU
 SG_ MCUM_ActiveReleaseSts : 108|2@1+ (1,0) [0|3] "-"  CLOUD,VCU
 SG_ MCUM_DCChargRelaySts : 110|1@1+ (1,0) [0|1] "-"  CLOUD,VCU,BMS
 SG_ MCUM_MinTorqueAllow : 112|16@1+ (0.1,-500) [-500|500] "N·m"  CLOUD,VCU
 SG_ MCUM_MainWireVolt : 128|16@1+ (0.1,0) [0|1000] "V"  CLOUD,GB,ICU,VCU,BMS
 SG_ MCUM_MainWireCurr : 168|16@1+ (0.1,-1000) [-1000|1000] "A"  CLOUD,GB,ICU,VCU,BMS
 SG_ MCUM_TMS_MotSelfHeatEnSts : 184|1@1+ (1,0) [0|1] "-"  VCU,TMS
 SG_ MCUM_TMS_MotSelfHeatLvlFb : 185|3@1+ (1,0) [0|7] "-"  VCU,TMS
 SG_ MCUM_RPowerReduceSts : 191|1@1+ (1,0) [0|1] "-"  CLOUD,VCU
 SG_ MCUM_HeatPwrAct : 192|8@1+ (100,0) [0|12800] "W"  TMS
 SG_ MCUM_HeatPwrMax : 200|8@1+ (100,0) [0|12800] "W"  TMS
 SG_ MCUM_HeatPwrAval : 208|5@1+ (1,0) [0|31] "kw"  VCU
 SG_ MCUM_RCtrlMode : 213|1@1+ (1,0) [0|1] "-"  CLOUD,VCU
 SG_ MCUM_RWarningLevel : 214|2@1+ (1,0) [0|3] "-"  CLOUD,VCU
 SG_ MCUM_RSelfCheckSts : 216|2@1+ (1,0) [0|3] "-"  CLOUD,VCU
 SG_ MCUM_RDrvMotorWorkSts : 218|2@1+ (1,0) [0|3] "-"  CLOUD,HPCGW,VCU
 SG_ MCUM_RCtrlModeVD : 220|1@1+ (1,0) [0|1] "-"  CLOUD,VCU
 SG_ MCUM_RHWRdcFault : 221|1@1+ (1,0) [0|1] "-"  CLOUD,HPCGW,VCU
 SG_ MCUM_RDrvMotorRPMVD : 222|1@1+ (1,0) [0|1] "-"  CLOUD,VCU
 SG_ MCUM_RActualTorqueFBVD : 223|1@1+ (1,0) [0|1] "-"  CLOUD,VCU
 SG_ MCUM_RDrvMotorRPM : 224|16@1+ (1,-17000) [-17000|30000] "rpm"  CLOUD,HPCGW,VCU
 SG_ MCUM_RActualTorqueFB : 240|16@1+ (0.1,-500) [-500|500] "N·m"  CLOUD,HPCGW,VCU

BO_ 1489 MCUM_5D1: 64 MCUM
 SG_ MCUM_R_MaxTorqueAllow : 193|16@1+ (0.1,-500) [-500|500] "N·m"  CLOUD,VCU
 SG_ MCUM_R_MaxSpeedAllow : 209|16@1+ (1,-17000) [-17000|30000] "rpm"  CLOUD,VCU
 SG_ MCUM_R_MinTorqueAllow : 225|16@1+ (0.1,-500) [-500|500] "N·m"  CLOUD,VCU

BO_ 219 MCUS_DB: 32 MCUS
 SG_ MCUS_CRC_DB : 0|8@1+ (1,0) [0|255] "-"  HPCGW,ICU,VCU,BMS,TMS
 SG_ MCUS_RollingCounter_DB : 8|4@1+ (1,0) [0|15] "-"  HPCGW,ICU,VCU,BMS,TMS
 SG_ MCUS_WarningLevel : 16|2@1+ (1,0) [0|3] "-"  CLOUD,IVI,ICU,VCU
 SG_ MCUS_SelfCheckSts : 18|2@1+ (1,0) [0|3] "-"  CLOUD,ICU,VCU
 SG_ MCUS_DrvMotorWorkSts : 20|2@1+ (1,0) [0|3] "-"  CLOUD,HPCGW,VCU
 SG_ MCUS_PowerReduceSts : 22|1@1+ (1,0) [0|1] "-"  CLOUD,VCU
 SG_ MCUS_DrvMotorRPM : 24|16@1+ (1,-17000) [-17000|30000] "rpm"  CLOUD,HPCGW,VCU
 SG_ MCUS_ActualTorqueFB : 40|16@1+ (0.1,-500) [-500|500] "N·m"  CLOUD,HPCGW,VCU
 SG_ MCUS_HWRdcFault : 56|1@1+ (1,0) [0|1] "-"  CLOUD,HPCGW,VCU
 SG_ MCUS_HighVoltPowerOffReq : 58|1@1+ (1,0) [0|1] "-"  CLOUD,VCU
 SG_ MCUS_HVILSts : 59|1@1+ (1,0) [0|1] "-"  CLOUD,VCU
 SG_ MCUS_DragSts : 60|2@1+ (1,0) [0|3] "-"  CLOUD,VCU
 SG_ MCUS_CtrlMode : 62|1@1+ (1,0) [0|1] "-"  CLOUD,VCU
 SG_ MCUS_MILlampReq : 65|1@1+ (1,0) [0|1] "-"  CLOUD,VCU
 SG_ MCUS_DrvMotorRPMVD : 68|1@1+ (1,0) [0|1] "-"  CLOUD,VCU
 SG_ MCUS_ActualTorqueFBVD : 69|1@1+ (1,0) [0|1] "-"  CLOUD,VCU
 SG_ MCUS_MaxTorqueAllow : 72|16@1+ (0.1,-500) [-500|500] "N·m"  CLOUD,VCU
 SG_ MCUS_MaxSpeedAllow : 88|16@1+ (1,-17000) [-17000|30000] "rpm"  CLOUD,VCU
 SG_ MCUS_ActiveReleaseSts : 108|2@1+ (1,0) [0|3] "-"  CLOUD,VCU
 SG_ MCUS_MinTorqueAllow : 112|16@1+ (0.1,-500) [-500|500] "N·m"  CLOUD,VCU
 SG_ MCUS_MainWireVolt : 128|16@1+ (0.1,0) [0|1000] "V"  CLOUD,ICU,VCU,BMS
 SG_ MCUS_MainWireCurr : 168|16@1+ (0.1,-1000) [-1000|1000] "A"  CLOUD,ICU,VCU,BMS
 SG_ MCUS_Clutch_Pos : 184|3@1+ (1,0) [0|7] "-"  CLOUD,VCU
 SG_ MCUS_Clutch_Fault : 187|4@1+ (1,0) [0|15] "-"  CLOUD,VCU
 SG_ MCUS_TMS_FrMotSelfHeatEnSts : 191|1@1+ (1,0) [0|1] "-"  CLOUD,VCU,TMS
 SG_ MCUS_TMS_FrMotSelfHeatLvlFb : 192|3@1+ (1,0) [0|7] "-"  CLOUD,VCU,TMS
 SG_ MCUS_HeatPwrAval : 195|5@1+ (1,0) [0|31] "kw"  VCU
 SG_ MCUS_Clutch_1_Pos : 200|3@1+ (1,0) [0|7] "-"  CLOUD,VCU
 SG_ MCUS_Clutch_2_Pos : 203|3@1+ (1,0) [0|7] "-"  CLOUD,VCU
 SG_ MCUS_Clutch_1_WarningLevel : 206|2@1+ (1,0) [0|3] "-"  CLOUD,VCU
 SG_ MCUS_Clutch_2_WarningLevel : 208|2@1+ (1,0) [0|3] "-"  CLOUD,VCU
 SG_ MCUS_Clutch_1_Fault : 210|10@1+ (1,0) [0|1023] "-"  CLOUD,VCU
 SG_ MCUS_Clutch_2_Fault : 220|10@1+ (1,0) [0|1023] "-"  CLOUD,VCU

BO_ 417 BMS_1A1: 32 BMS
 SG_ BMS_CRC_1A1 : 0|8@1+ (1,0) [0|255] "-"  HPCGW,HPCBCM,IVI,ICU,VCU,MCUM,MCUS,DCDC,OBC,GCU,IBS,TMS
 SG_ BMS_RollingCounter_1A1 : 8|4@1+ (1,0) [0|15] "-"  CLOUD,HPCGW,HPCBCM,IVI,ICU,VCU,MCUM,MCUS,DCDC,OBC,GCU,IBS,TMS
 SG_ BMS_Warning_Level : 16|2@1+ (1,0) [0|3] "-"  CLOUD,IVI,ICU,VCU
 SG_ BMS_SelfCheck : 18|2@1+ (1,0) [0|2] "-"  CLOUD,ICU,VCU
 SG_ BMS_BattChargerSts : 20|3@1+ (1,0) [0|7] "-"  CLOUD,GB,HPCGW,HPCBCM,IVI,ICU,VCU,MCUM,MCUS,DCDC,OBC,TMS
 SG_ BMS_RHighVolSts : 24|1@1+ (1,0) [0|1] "-"  CLOUD,ICU,VCU,MCUM,MCUS,GCU,IBS,TMS
 SG_ BMS_RPreChargeRelayFB : 25|1@1+ (1,0) [0|1] "-"  CLOUD,VCU
 SG_ BMS_RPositiveRelayFB : 26|1@1+ (1,0) [0|1] "-"  CLOUD,VCU,MCUM,MCUS
 SG_ BMS_RNegativeRelayFB : 27|1@1+ (1,0) [0|1] "-"  CLOUD,VCU,MCUM,MCUS
 SG_ BMS_RPositiveRelay_F : 28|1@1+ (1,0) [0|1] "-"  CLOUD,VCU
 SG_ BMS_RNegativeRelay_F : 29|1@1+ (1,0) [0|1] "-"  CLOUD,VCU
 SG_ BMS_RPreChargeFinishSts : 30|2@1+ (1,0) [0|3] "-"  CLOUD,VCU
 SG_ BMS_MCUMHVILSts : 40|1@1+ (1,0) [0|1] "-"  CLOUD,VCU
 SG_ BMS_ACPTCHVILSts : 41|1@1+ (1,0) [0|1] "-"  CLOUD,VCU
 SG_ BMS_PTCHVILSts : 42|1@1+ (1,0) [0|1] "-"  CLOUD,VCU
 SG_ BMS_CCMHVILSts : 43|1@1+ (1,0) [0|1] "-"  CLOUD,VCU,CCM
 SG_ BMS_CDUHVILSts : 44|1@1+ (1,0) [0|1] "-"  CLOUD,VCU
 SG_ BMS_DCChgHVILSts : 45|1@1+ (1,0) [0|1] "-"  CLOUD,VCU
 SG_ BMS_MCUSHVILSts : 46|1@1+ (1,0) [0|1] "-"  CLOUD,VCU
 SG_ BMS_HVOffSts : 47|1@1+ (1,0) [0|1] "-"  CLOUD,VCU
 SG_ BMS_SeriousWarning_Level : 48|2@1+ (1,0) [0|3] "-"  CLOUD,VCU
 SG_ BMS_DCChgRelayCloseReq : 50|1@1+ (1,0) [0|1] "-"  CLOUD,VCU,MCUM
 SG_ BMS_DCChgRelayFB : 56|1@1+ (1,0) [0|1] "-"  CLOUD,VCU
 SG_ BMS_ChgStopReason : 57|6@1+ (1,0) [0|63] "-"  CLOUD,ICU,VCU
 SG_ BMS_GCUHVILSts : 65|1@1+ (1,0) [0|1] "-"  CLOUD,VCU
 SG_ BMS_MILlampReq : 66|1@1+ (1,0) [0|1] "-"  CLOUD,VCU
 SG_ BMS_IsoRessistanceSts : 67|1@1+ (1,0) [0|1] "-"  CLOUD,IVI,ICU,VCU
 SG_ BMS_Integrity_Check : 70|1@1+ (1,0) [0|1] "-"  CLOUD,VCU
 SG_ BMS_BattVolt : 72|16@1+ (0.1,0) [0|2000] "V"  CLOUD,IVI,ICU,VCU,MCUM,MCUS,TMS
 SG_ BMS_BattCurr : 88|16@1+ (0.1,-1500) [-1500|5000] "A"  CLOUD,GB,IVI,ICU,VCU,TMS
 SG_ BMS_BatDyn_Dchgpwr : 104|13@1+ (0.1,0) [0|800] "kw"  CLOUD,VCU,MCUM,MCUS
 SG_ BMS_BatDyn_Chgpwr : 120|13@1+ (0.1,0) [0|800] "kw"  CLOUD,VCU
 SG_ BMS_Precharge_CoolingSts : 254|2@1+ (1,0) [0|3] ""  CLOUD,VCU

BO_ 784 BMS_310: 32 BMS
 SG_ BMS_InverterPower : 8|8@1+ (0.1,0) [0|25] "kw"  CLOUD,VCU
 SG_ BMS_MaxChargeVolt : 16|16@1+ (0.1,0) [0|1000] "V"  CLOUD,VCU,OBC
 SG_ BMS_MaxChargeCurr : 32|12@1+ (0.1,0) [0|400] "A"  CLOUD,VCU,OBC
 SG_ BMS_OBCWorkModeCtrl : 44|3@1+ (1,0) [0|7] "-"  CLOUD,VCU,OBC
 SG_ BMS_MaxPower : 47|9@1+ (0.05,0) [0|25] "kw"  CLOUD,VCU,OBC
 SG_ BMS_ChargerACInput : 56|1@1+ (1,0) [0|1] "-"  CLOUD,HPCBCM,ICU,VCU
 SG_ BMS_ChargerDCInput : 57|1@1+ (1,0) [0|1] "-"  CLOUD,HPCGW,HPCBCM,IVI,ICU,VCU
 SG_ BMS_ChargeRequest : 58|1@1+ (1,0) [0|1] "-"  CLOUD,VCU
 SG_ BMS_InverterRequest : 59|1@1+ (1,0) [0|1] "-"  CLOUD,VCU
 SG_ BMS_ChargeQuantity : 70|10@1+ (0.5,0) [0|500] "Ah"  CLOUD,HPCBCM,ICU,VCU
 SG_ BMS_BattMaxTemp : 80|8@1+ (1,-40) [-40|210] "℃"  CLOUD,VCU,ECM,TMS
 SG_ BMS_BattMinTemp : 88|8@1+ (1,-40) [-40|210] "℃"  CLOUD,VCU,ECM,TMS
 SG_ BMS_BattSOC_Display : 144|10@1+ (0.1,0) [0|100] "%"  CLOUD,GB,HPCGW,HPCBCM,IVI,ICU,VCU,MCUM,MCUS,GCU,ECM,TMS
 SG_ BMS_Req_Cab220VInverter_Sts : 174|1@1+ (1,0) [0|1] "-"  CLOUD,VCU
 SG_ BMS_Req_Cabin220VInverter_Sts : 175|1@1+ (1,0) [0|1] "-"  CLOUD,VCU
 SG_ BMS_RemainEnergy : 176|16@1+ (10,0) [0|655300] "Wh"  CLOUD,ICU,VCU
 SG_ BMS_StateOfEngeryMax : 192|16@1+ (10,0) [0|655300] "Wh"  CLOUD,ICU,VCU
 SG_ BMS_ThermalManageRequest : 240|3@1+ (1,0) [0|7] "-"  CLOUD,VCU,TMS
 SG_ BMS_PreHeatingState : 244|2@1+ (1,0) [0|3] "-"  CLOUD,ICU,VCU

BO_ 1457 BMS_5B1: 64 BMS
 SG_ BMS_SOC_Real : 320|10@1+ (0.1,0) [0|100] "%"  CLOUD,VCU
 SG_ BMS_MODE_t : 368|4@1+ (1,0) [0|15] "-"  CLOUD,VCU,TMS
 SG_ BMS_VoltLoDeratLevel_NA : 466|2@1+ (1,0) [0|3] "-"  CLOUD,VCU
 SG_ BMS_VoltHiDeratLevel_NA : 468|2@1+ (1,0) [0|3] "-"  CLOUD,VCU

BO_ 1461 BMS_5B5: 64 BMS
 SG_ BMS_WkupVolt_DC12V : 64|8@1+ (0.2,0) [0|50] "V"  CLOUD,VCU
 SG_ BMS_WkupVolt_AC12V : 72|8@1+ (0.2,0) [0|50] "V"  CLOUD,VCU
 SG_ BMS_SOC_target : 192|10@1+ (0.1,0) [0|100] "%"  CLOUD,VCU
 SG_ BMS_CorrectSOEPer : 202|10@1+ (0.1,0) [0|100] "%"  CLOUD,VCU
 SG_ BMS_SOCModifyFlag : 212|1@1+ (1,0) [0|1] "-"  CLOUD,VCU
 SG_ BMS_BMU_SoftwareVersion : 232|24@1+ (1,0) [0|16000000] "-"  CLOUD,VCU

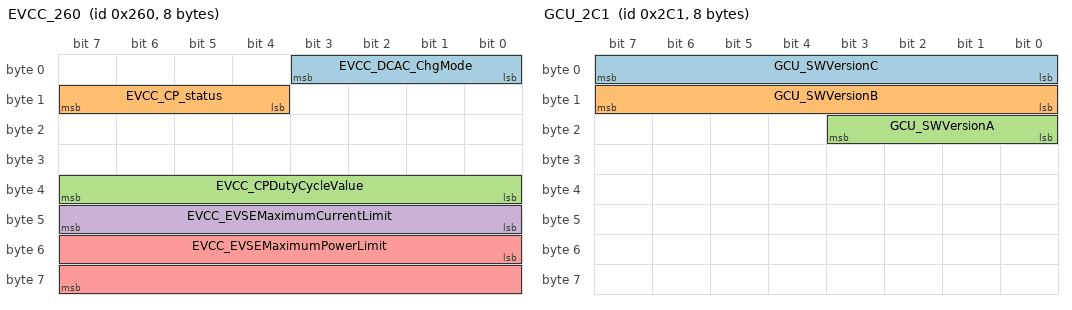
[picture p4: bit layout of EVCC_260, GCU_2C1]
BO_ 608 EVCC_260: 8 EVCC
 SG_ EVCC_DCAC_ChgMode : 0|4@1+ (1,0) [0|14] "-"  VCU,BMS
 SG_ EVCC_CP_status : 12|4@1+ (1,0) [0|14] "-"  VCU,BMS
 SG_ EVCC_CPDutyCycleValue : 32|8@1+ (1,0) [0|100] "%"  VCU,BMS
 SG_ EVCC_EVSEMaximumCurrentLimit : 40|8@1+ (5,0) [0|1000] "A"  VCU,BMS
 SG_ EVCC_EVSEMaximumPowerLimit : 48|16@1+ (10,0) [0|650000] "W"  VCU,BMS

BO_ 804 DCDC_324: 16 DCDC
 SG_ DCDC_CRC_324 : 0|8@1+ (1,0) [0|255] "-"  CLOUD,HPCGW,ICU,VCU,MCUM,MCUS,BMS,IBS,TMS
 SG_ DCDC_RollingCounter_324 : 8|4@1+ (1,0) [0|15] "-"  CLOUD,HPCGW,ICU,VCU,MCUM,MCUS,BMS,IBS,TMS
 SG_ DCDC_WorkSts : 16|3@1+ (1,0) [0|3] "-"  CLOUD,GB,HPCGW,IVI,ICU,VCU,BMS,IBS,TMS
 SG_ DCDC_Under_Output_Voltage : 19|1@1+ (1,0) [0|1] "-"  CLOUD,VCU,IBS
 SG_ DCDC_Over_Output_Voltage : 20|1@1+ (1,0) [0|1] "-"  CLOUD,VCU,IBS
 SG_ DCDC_Under_Input_Voltage : 21|1@1+ (1,0) [0|1] "-"  CLOUD,VCU,IBS
 SG_ DCDC_Over_Input_Voltage : 22|1@1+ (1,0) [0|1] "-"  CLOUD,VCU,IBS
 SG_ DCDC_Over_Input_Current : 23|1@1+ (1,0) [0|1] "-"  CLOUD,VCU,IBS
 SG_ DCDC_Real_Output_Current : 24|12@1+ (0.1,0) [0|250] "A"  CLOUD,ICU,VCU,IBS,TMS
 SG_ DCDC_Real_Output_Voltage : 36|12@1+ (0.1,0) [0|50] "V"  CLOUD,ICU,VCU,IBS,TMS
 SG_ DCDC_Real_Input_Current : 48|8@1+ (0.1,0) [0|10] "A"  CLOUD,VCU,BMS,IBS
 SG_ DCDC_Real_Input_Voltage : 56|13@1+ (0.2,0) [0|1000] "V"  CLOUD,VCU,MCUM,MCUS,BMS,IBS
 SG_ DCDC_Derating : 69|1@1+ (1,0) [0|1] "-"  CLOUD,VCU,IBS
 SG_ DCDC_Hardware_Fault_Flag : 71|1@1+ (1,0) [0|1] "-"  CLOUD,VCU,IBS
 SG_ CDU_ACChg_HIVSts : 83|1@1+ (1,0) [0|1] "-"  CLOUD,VCU,IBS
 SG_ CDU_OBC_OverTemp : 90|1@1+ (1,0) [0|1] "-"  CLOUD,VCU,IBS
 SG_ CDU_SelfCheckSt : 112|1@1+ (1,0) [0|1] "-"  CLOUD,VCU,IBS
 SG_ CDU_HV_HIVSts : 113|1@1+ (1,0) [0|1] "-"  CLOUD,VCU,IBS

BO_ 790 OBC_316: 32 OBC
 SG_ OBC_CRC_316 : 0|8@1+ (1,0) [0|255] "-"  CLOUD,HPCGW,IVI,ICU,VCU,BMS
 SG_ OBC_RollingCounter_316 : 8|4@1+ (1,0) [0|15] "0"  CLOUD,HPCGW,IVI,ICU,VCU,BMS
 SG_ OBC_WorkSts : 16|3@1+ (1,0) [0|7] "-"  CLOUD,IVI,ICU,VCU,BMS
 SG_ OBC_StartSts : 19|1@1+ (1,0) [0|1] "-"  CLOUD,VCU,BMS
 SG_ OBC_DCSts : 20|1@1+ (1,0) [0|1] "-"  CLOUD,VCU,BMS
 SG_ OBC_ACChargeOutputSts : 23|1@1+ (1,0) [0|1] "-"  VCU,BMS
 SG_ OBC_DCVolt : 24|14@1+ (0.1,0) [0|1000] "V"  CLOUD,VCU,BMS
 SG_ OBC_HardwareSts : 39|1@1+ (1,0) [0|1] "-"  CLOUD,VCU,BMS
 SG_ OBC_DCCurr : 40|11@1+ (0.1,-100) [-100|100] "A"  CLOUD,VCU,BMS
 SG_ OBC_ACVolt : 51|13@1+ (0.1,0) [0|800] "V"  CLOUD,VCU,BMS
 SG_ OBC_ACCurr : 64|11@1+ (0.1,-100) [-100|100] "A"  CLOUD,VCU,BMS
 SG_ OBC_CCConnectSts : 77|2@1+ (1,0) [0|3] "-"  CLOUD,HPCGW,ICU,VCU,BMS
 SG_ OBC_CPDutyCycleFault : 79|1@1+ (1,0) [0|1] "-"  CLOUD,VCU,BMS
 SG_ OBC_CPDutyCycleValue : 80|8@1+ (1,0) [0|100] "%"  CLOUD,VCU,BMS
 SG_ OBC_ACMaxPower : 88|10@1+ (0.05,-25) [-25|25] "kw"  CLOUD,VCU,BMS
 SG_ OBC_ACPowerState : 158|2@1+ (1,0) [0|3] "-"  CLOUD,VCU,BMS

BO_ 549 IBS_225: 32 IBS
 SG_ IBS_CRC_225 : 0|8@1+ (1,0) [0|255] "-"  HPCBCM,VCU,DCDC
 SG_ IBS_RollingCounter_225 : 8|4@1+ (1,0) [0|15] "-"  HPCBCM,VCU,DCDC
 SG_ IBS_Warning_Level : 46|2@1+ (1,0) [0|3] "-"  CLOUD,VCU

BO_ 189 GCU_BD: 32 GCU
 SG_ GCU_CRC_BD : 0|8@1+ (1,0) [0|255] "-"  VCU,BMS,ECM,TMS
 SG_ GCU_RollingCounter_BD : 8|4@1+ (1,0) [0|15] "-"  VCU,BMS,ECM,TMS
 SG_ GCU_MainWireCurr : 16|16@1+ (0.1,-1000) [-1000|1000] "A"  CLOUD,VCU,BMS
 SG_ GCU_MainWireVolt : 32|13@1+ (0.1,0) [0|819] "V"  CLOUD,VCU,BMS
 SG_ GCU_SystemWarning : 45|1@1+ (1,0) [0|1] "-"  VCU
 SG_ GCU_MILlampReq : 46|1@1+ (1,0) [0|1] "-"  CLOUD,VCU
 SG_ GCU_MoterTemp : 48|8@1+ (1,-40) [-40|210] "℃"  CLOUD,VCU
 SG_ GCU_Temp : 56|8@1+ (1,-40) [-40|210] "℃"  CLOUD,VCU
 SG_ GCU_SelfCheck : 64|2@1+ (1,0) [0|3] "-"  CLOUD,VCU
 SG_ GCU_Warning_Level : 66|2@1+ (1,0) [0|3] "-"  VCU
 SG_ GCU_HVILSts : 68|1@1+ (1,0) [0|1] "-"  CLOUD,VCU
 SG_ GCU__PowerReduceSts : 69|1@1+ (1,0) [0|1] "-"  CLOUD,VCU
 SG_ GCU_ActualMotorRPM_VD : 70|1@1+ (1,0) [0|1] "-"  VCU,ECM
 SG_ GCU_ActualMotorTorque_VD : 71|1@1+ (1,0) [0|1] "-"  VCU,ECM
 SG_ GCU_ActualMotorTorque : 72|12@1+ (0.1,-200) [-200|200] "N·m"  CLOUD,VCU,ECM
 SG_ GCU_MaxTorque : 84|12@1+ (0.1,-200) [-200|200] "N·m"  CLOUD,VCU
 SG_ GCU_EngineFuelInhibitReq : 96|1@1+ (1,0) [0|1] "-"  CLOUD,VCU
 SG_ GCU_ActiveReleaseFB : 110|2@1+ (1,0) [0|3] "-"  VCU
 SG_ GCU_MAXPower : 112|8@1+ (1,0) [0|250] "kw"  VCU
 SG_ GCU_TransientPower : 120|12@1+ (0.1,0) [0|250] "kw"  CLOUD,VCU
 SG_ GCU_HVOffReq : 132|1@1+ (1,0) [0|1] "-"  VCU
 SG_ GCU_ControlMode : 133|3@1+ (1,0) [0|7] "-"  CLOUD,VCU
 SG_ GCU_Operating_Mode : 140|4@1+ (1,0) [0|14] "-"  CLOUD,VCU
 SG_ GCU_ActualMotorRPM : 144|16@1+ (1,-17000) [-17000|30000] "rpm"  CLOUD,VCU,ECM
 SG_ GCU_EngineCylinderDeactivationSt : 160|2@1+ (1,0) [0|3] "-"  CLOUD,VCU

BO_ 705 GCU_2C1: 8 GCU
 SG_ GCU_SWVersionC : 0|8@1+ (1,0) [0|254] "-"  VCU
 SG_ GCU_SWVersionB : 8|8@1+ (1,0) [0|254] "-"  VCU
 SG_ GCU_SWVersionA : 16|4@1+ (1,0) [0|15] "-"  VCU

BO_ 190 ECM_BE: 32 ECM
 SG_ ECM_CRC_BE : 0|8@1+ (1,0) [0|255] "-"  HPCGW,ICU,VCU,MCUM,MCUS,BMS
 SG_ ECM_RollingCounter_BE : 8|4@1+ (1,0) [0|15] "-"  HPCGW,ICU,VCU,MCUM,MCUS,BMS
 SG_ ECM_EngineSts : 16|3@1+ (1,0) [0|7] "-"  CLOUD,ICU,VCU,MCUM,BMS
 SG_ ECM_FaultLevel : 19|2@1+ (1,0) [0|3] "-"  CLOUD,IVI,VCU
 SG_ ECM_ActualEngineTorqueValid : 21|1@1+ (1,0) [0|1] "-"  CLOUD,VCU
 SG_ ECM_EngineTorqueLoss : 22|10@1+ (0.5,-100) [-100|411] "N·m"  CLOUD,VCU
 SG_ ECM_ActualEngineTorque : 32|12@1+ (0.5,-500) [-500|1547] "N·m"  CLOUD,VCU
 SG_ ECM_EngineTorqueMax : 44|12@1+ (0.5,-500) [-500|1547] "N·m"  CLOUD,VCU
 SG_ ECM_EngineTorqueMin : 56|12@1+ (0.5,-500) [-500|1547] "N·m"  CLOUD,VCU
 SG_ ECM_EngineSpeed : 68|13@1+ (1,0) [0|8191] "rpm"  CLOUD,GB,HPCGW,VCU,MCUM,MCUS,BMS,GCU,TMS
 SG_ ECM_EngineSpeedValid : 81|1@1+ (1,0) [0|1] "-"  CLOUD,VCU,MCUM,MCUS,BMS,GCU
 SG_ ECM_EngineStopAllow : 82|1@1+ (1,0) [0|1] "-"  CLOUD,VCU
 SG_ ECM_EngineOilPressureLow : 83|1@1+ (1,0) [0|1] "-"  CLOUD,IVI,ICU,VCU
 SG_ ECM_EngineFuleCutoffSts : 84|1@1+ (1,0) [0|1] "-"  CLOUD,VCU
 SG_ ECM_EngineStartedCompleted : 85|1@1+ (1,0) [0|1] "-"  CLOUD,ICU,VCU,GCU
 SG_ ECM_CatalystWarmUpSts : 86|1@1+ (1,0) [0|1] "-"  CLOUD,VCU
 SG_ ECM_CatalystWarmUpReq : 87|1@1+ (1,0) [0|1] "-"  CLOUD,VCU,GCU
 SG_ ECM_IdleTargetSpeed : 88|12@1+ (1,0) [0|4094] "rpm"  CLOUD,VCU
 SG_ ECM_IdleActive : 100|1@1+ (1,0) [0|1] "-"  CLOUD,VCU
 SG_ ECM_EngineStartReq : 101|3@1+ (1,0) [0|7] "-"  CLOUD,VCU
 SG_ ECM_EngineStopInhibit : 104|10@1+ (1,0) [0|1023] "-"  CLOUD,VCU
 SG_ ECM_GPFRegenlamp : 114|2@1+ (1,0) [0|3] "-"  CLOUD,IVI,ICU,VCU
 SG_ ECM_EngineCoolantTemp : 136|8@1+ (1,-40) [-40|215] "℃"  CLOUD,HPCGW,IVI,ICU,VCU,MCUM,MCUS,BMS,GCU,TMS
 SG_ ECM_EngineCoolantTempValid : 144|1@1+ (1,0) [0|1] "-"  CLOUD,HPCGW,IVI,ICU,VCU,MCUM,MCUS,BMS,GCU,TMS
 SG_ ECM_FVVSts : 145|2@1+ (1,0) [0|3] "-"  CLOUD,ICU,VCU
 SG_ ECM_learningReq : 147|1@1+ (1,0) [0|1] "-"  CLOUD,VCU
 SG_ ECM_EngineIdleStateRequest : 148|1@1+ (1,0) [0|1] "-"  CLOUD,VCU
 SG_ ECM_EngineDFCOConditionRequest : 149|1@1+ (1,0) [0|1] "-"  CLOUD,VCU
 SG_ ECM_GPFRegenReq : 150|1@1+ (1,0) [0|1] "-"  CLOUD,VCU
 SG_ ECM_SVSLampRequest : 151|1@1+ (1,0) [0|1] "-"  CLOUD,IVI,ICU,VCU
 SG_ ECM_TankPressure : 152|10@1+ (0.1,-20) [-20|40] "kpa"  CLOUD,VCU
 SG_ ECM_TankPressureValid : 162|1@1+ (1,0) [0|1] "-"  CLOUD,VCU
 SG_ ECM_MilLampRequest : 163|2@1+ (1,0) [0|3] "-"  CLOUD,IVI,ICU,VCU
 SG_ ECM_ToothlearningSucValid : 165|2@1+ (1,0) [0|3] "-"  CLOUD,VCU,GCU
 SG_ ECM_FuelCloseLoopSts : 167|1@1+ (1,0) [0|1] "-"  CLOUD,VCU,GCU,TMS
 SG_ ECM_RestrictorOpenValue : 168|7@1+ (1,0) [0|100] "%"  CLOUD,HPCGW,VCU,MCUM,MCUS,BMS,GCU,TMS
 SG_ ECM_FuelLevelSensorValid : 175|1@1+ (1,0) [0|1] "-"  CLOUD,VCU
 SG_ ECM_FuelLevel : 176|10@1+ (0.1,0) [0|100] "%"  CLOUD,ICU,VCU,GCU
 SG_ ECM_SelfCheckSt : 186|1@1+ (1,0) [0|1] "-"  CLOUD,VCU
 SG_ ECM_PCVPipeDiagReq : 187|1@1+ (1,0) [0|1] "-"  CLOUD,VCU
 SG_ ECM_CalculatedLoad : 190|10@1+ (0.1,0) [0|100] "%"  CLOUD,HPCGW,VCU,MCUM,MCUS,BMS,GCU,TMS
 SG_ ECM_ClearingSparkcarbonedRequest : 203|2@1+ (1,0) [0|3] "-"  VCU
 SG_ ECM_AirPressure : 208|8@1+ (0.0078,0) [0|2] "bar"  CLOUD,VCU
 SG_ ECM_FanSts : 216|8@1+ (1,0) [0|100] "%"  CLOUD,VCU,TMS

BO_ 327 ECM_147: 32 ECM
 SG_ ECM_FuelConsumption : 232|8@1+ (4,0) [0|1020] "ul/100ms"  CLOUD,HPCBCM,ICU,VCU

BO_ 328 ECM_148: 16 ECM
 SG_ ECM_SWVersionC : 0|8@1+ (1,0) [0|254] "-"  CLOUD,VCU
 SG_ ECM_SWVersionB : 8|8@1+ (1,0) [0|254] "-"  CLOUD,VCU
 SG_ ECM_SWVersionA : 16|4@1+ (1,0) [0|15] "-"  CLOUD,VCU
 SG_ ECM_Total_fuel_consumed : 64|32@1+ (0.01,0) [0|16777216] "L"  CLOUD,ICU,VCU

BO_ 1516 ECM_5EC: 32 ECM
 SG_ ECM_EngineWorktime : 32|16@1+ (1,0) [0|65535] "s"  CLOUD,VCU

BO_ 187 VCU_BB: 32 VCU
 SG_ VCU_CRC_BB : 0|8@1+ (1,0) [0|255] "-"  MCUM,MCUS,BMS,GCU,ECM,TMS
 SG_ VCU_RollingCounter_BB : 8|4@1+ (1,0) [0|15] "-"  MCUM,MCUS,BMS,GCU,ECM,TMS
 SG_ VCU_GCURequestTorque : 16|12@1+ (0.1,-200) [-200|200] "N/m"  CLOUD,GCU
 SG_ VCU_PowerReducetSts : 28|1@1+ (1,0) [0|1] "-"  CLOUD,GCU
 SG_ VCU_GCUAassistFB : 29|1@1+ (1,0) [0|1] "-"  CLOUD,GCU
 SG_ VCU_GCUActiveReleaseCmd : 30|1@1+ (1,0) [0|1] "-"  CLOUD,GCU
 SG_ VCU_PowerOverSts : 31|1@1+ (1,0) [0|1] "-"  CLOUD,GCU
 SG_ VCU_GCURequesSpeed : 32|14@1+ (1,-8000) [-8000|8000] "rpm"  CLOUD,GCU
 SG_ VCU_GCUControlMode : 46|1@1+ (1,0) [0|1] "-"  CLOUD,GCU
 SG_ VCU_RoughRoadDetectionFlag : 47|1@1+ (1,0) [0|1] "-"  CLOUD,GCU
 SG_ VCU_MotChargePower : 48|8@1+ (0.5,0) [0|127] "kw"  CLOUD,GCU
 SG_ VCU_APS1Position : 56|8@1+ (0.393,0) [0|100] "%"  CLOUD,HPCGW,ECM
 SG_ VCU_EngineStartReq : 64|1@1+ (1,0) [0|1] "-"  CLOUD,GCU,ECM
 SG_ VCU_EngineFuelInhibitReq : 65|1@1+ (1,0) [0|1] "-"  CLOUD,ECM
 SG_ VCU_EngineOffRequest : 66|1@1+ (1,0) [0|1] "-"  CLOUD,GCU,ECM
 SG_ VCU_STorqueReqValid : 67|1@1+ (1,0) [0|1] "-"  CLOUD,GCU,ECM
 SG_ VCU_STorqueReq : 68|12@1+ (0.5,-500) [-500|1547] "N·m"  CLOUD,GCU,ECM
 SG_ VCU_FTorqueSwFb : 80|1@1+ (1,0) [0|1] "-"  CLOUD,ECM
 SG_ VCU_FVVOpenReq : 81|1@1+ (1,0) [0|1] "-"  CLOUD,ECM
 SG_ VCU_WarmUpCycleIndicator : 82|1@1+ (1,0) [0|1] "-"  CLOUD,HPCGW,MCUM,BMS,GCU,ECM,TMS
 SG_ VCU_EngineResetSts : 83|1@1+ (1,0) [0|1] "-"  CLOUD
 SG_ VCU_EngineSts : 84|4@1+ (1,0) [0|15] "-"  CLOUD,GB,GCU,ECM
 SG_ VCU_FTorqueReq : 88|12@1+ (0.5,-500) [-500|1547] "N·m"  CLOUD,ECM
 SG_ VCU_FTorqueReqValid : 100|1@1+ (1,0) [0|1] "-"  CLOUD,ECM
 SG_ VCU_EngineIdleReq : 101|1@1+ (1,0) [0|1] "-"  CLOUD,ECM
 SG_ VCU_REsystemSts : 102|1@1+ (1,0) [0|1] "-"  CLOUD,GCU,ECM
 SG_ VCU_REsystemFaultSts : 103|1@1+ (1,0) [0|1] "-"  CLOUD,GCU,ECM
 SG_ VCU_APS2Position : 104|8@1+ (0.393,0) [0|100] "%"  CLOUD,HPCGW,ECM
 SG_ VCU_EngineRunAllowFlg : 112|1@1+ (1,0) [0|1] "-"  CLOUD,ECM
 SG_ VCU_EngineIdleSpeed : 113|2@1+ (1,0) [0|2] "-"  CLOUD,ECM
 SG_ VCU_EngineFuleCutoffReq : 115|1@1+ (1,0) [0|1] "-"  CLOUD,GCU,ECM
 SG_ VCU_MCUSClutchPosition : 116|2@1+ (1,0) [0|3] "-"  CLOUD,MCUS
 SG_ VCU_MGCUWorkMode : 118|2@1+ (1,0) [0|3] "-"  CLOUD,MCUS
 SG_ VCU_REChgTarget : 120|8@1+ (1,0) [0|100] "%"  CLOUD
 SG_ VCU_MotStartStopPowerUP : 128|8@1+ (0.5,0) [0|125] "kw"  CLOUD,GCU
 SG_ VCU_MotStartStopPowerLOW : 136|8@1+ (0.5,0) [0|125] "kw"  CLOUD,GCU
 SG_ VCU_GCURequesSpeed_MGCU : 144|16@1+ (1,-17000) [-17000|30000] "rpm"  GCU
 SG_ VCU_DynamicChgPwr : 160|5@1+ (1,-10) [-10|10] "-"  CLOUD
 SG_ VCU_ForceChgPwr : 165|5@1+ (1,-10) [-10|10] "-"  CLOUD
 SG_ VCU_REStartType : 170|6@1+ (1,0) [0|31] "-"  CLOUD
 SG_ VCU_Clutch1Position : 176|2@1+ (1,0) [0|3] "-"  CLOUD,MCUS
 SG_ VCU_Clutch2Position : 178|2@1+ (1,0) [0|3] "-"  CLOUD,MCUS
 SG_ VCU_Clutch_1_RequesSpeed : 180|16@1+ (1,-17000) [-17000|30000] "rpm"  CLOUD,MCUS
 SG_ VCU_Clutch_2_RequesSpeed : 196|16@1+ (1,-17000) [-17000|30000] "rpm"  CLOUD,MCUS
 SG_ VCU_EVSingleAllow_PHEV : 212|1@1+ (1,0) [0|1] "-"  CLOUD
 SG_ VCU_EVDualAllow_PHEV : 213|1@1+ (1,0) [0|1] "-"  CLOUD
 SG_ VCU_REAllow_PHEV : 214|1@1+ (1,0) [0|1] "-"  CLOUD
 SG_ VCU_HEVAllow_PHEV : 215|1@1+ (1,0) [0|1] "-"  CLOUD
 SG_ VCU_WorkMode_PHEV : 216|3@1+ (1,0) [0|7] "-"  CLOUD,MCUS
 SG_ VCU_WorkModeReq_PHEV : 219|3@1+ (1,0) [0|7] "-"  CLOUD
 SG_ VCU_Clutch_1_RequesSpeedValid : 222|1@1+ (1,0) [0|1] "-"  CLOUD,MCUS
 SG_ VCU_Clutch_2_RequesSpeedValid : 223|1@1+ (1,0) [0|1] "-"  CLOUD,MCUS
 SG_ VCU_FuelChgModeSts : 224|2@1+ (1,0) [0|3] "-"  CLOUD,IVI
 SG_ VCU_FuelChgModeMsg : 226|2@1+ (1,0) [0|3] "-"  CLOUD,IVI
 SG_ VCU_EngPreStartFlg : 228|1@1+ (1,0) [0|1] "-"  CLOUD,ECM

BO_ 222 VCU_DE: 32 VCU
 SG_ VCU_BrkPedOpen : 0|1@1+ (1,0) [0|1] "-"  CLOUD
 SG_ VCU_BrkPedClose : 1|1@1+ (1,0) [0|1] "-"  CLOUD
 SG_ VCU_ColumnShiftP : 2|1@1+ (1,0) [0|1] "-"  CLOUD
 SG_ VCU_VehiCrashSts : 3|1@1+ (1,0) [0|1] "-"  CLOUD
 SG_ VCU_SleepSatisfiedSts : 4|1@1+ (1,0) [0|1] "-"  CLOUD
 SG_ VCU_VehiHvCmd : 5|1@1+ (1,0) [0|1] "-"  CLOUD
 SG_ VCU_GearQuitAps : 6|1@1+ (1,0) [0|1] "-"  CLOUD
 SG_ VCU_REOverChgPwrFlag : 7|1@1+ (1,0) [0|1] "-"  CLOUD
 SG_ VCU_VehiAccnFilt : 8|8@1+ (0.05,-5) [-5|7.8] "-"  CLOUD
 SG_ VCU_HvOffSts : 16|4@1+ (1,0) [0|15] "-"  CLOUD
 SG_ VCU_ElecPwrBalanceReq : 20|1@1+ (1,0) [0|1] "-"  CLOUD
 SG_ VCU_CDU_RecvTr : 21|1@1+ (1,0) [0|1] "-"  CLOUD
 SG_ VCU_BMS_RecvTr : 22|1@1+ (1,0) [0|1] "-"  CLOUD
 SG_ VCU_IVI_RecvTr : 23|1@1+ (1,0) [0|1] "-"  CLOUD
 SG_ VCU_WheelMaxDrvTrq : 24|10@1+ (20,-10000) [-10000|10000] "-"  CLOUD
 SG_ VCU_WheelMaxRecTrq : 34|10@1+ (20,-10000) [-10000|10000] "-"  CLOUD
 SG_ VCU_GCU_RecvTr : 44|1@1+ (1,0) [0|1] "-"  CLOUD
 SG_ VCU_TCM_RecvTr : 45|1@1+ (1,0) [0|1] "-"  CLOUD
 SG_ VCU_PTC_RecvTr : 46|1@1+ (1,0) [0|1] "-"  CLOUD
 SG_ VCU_LossFctorFlgFL : 47|1@1+ (1,0) [0|1] "-"  CLOUD
 SG_ VCU_LowBattVolt : 48|7@1+ (0.25,0) [0|31.8] "-"  CLOUD
 SG_ VCU_HighPerforDisable : 55|1@1+ (1,0) [0|1] "-"  CLOUD
 SG_ VCU_AccPedHSigVolt : 56|7@1+ (0.05,0) [0|6] "-"  CLOUD
 SG_ VCU_LossFctorFlgFR : 63|1@1+ (1,0) [0|1] "-"  CLOUD
 SG_ VCU_AccPedLSigVolt : 64|7@1+ (0.05,0) [0|6] "-"  CLOUD
 SG_ VCU_LossFctorFlgRL : 71|1@1+ (1,0) [0|1] "-"  CLOUD
 SG_ VCU_AccPedHPwrVolt : 72|7@1+ (0.1,0) [0|12] "-"  CLOUD
 SG_ VCU_LossFctorFlgRR : 79|1@1+ (1,0) [0|1] "-"  CLOUD
 SG_ VCU_AccPedLPwrVolt : 80|7@1+ (0.1,0) [0|12] "-"  CLOUD
 SG_ VCU_PreReqChgPwr : 88|8@1+ (1,0) [0|250] "-"  CLOUD
 SG_ VCU_VehPwrChageLimit : 96|8@1+ (1,0) [0|250] "-"  CLOUD
 SG_ VCU_FastPwrRequest : 104|8@1+ (1,0) [0|250] "-"  CLOUD
 SG_ VCU_On2KL15_Volt : 112|8@1+ (100,0) [0|20000] "-"  CLOUD
 SG_ VCU_ClutchWrkModDebug : 120|5@1+ (1,0) [0|31] "-"  CLOUD
 SG_ VCU_WheelPwrOvrLimitflgRE : 125|2@1+ (1,0) [0|3] "-"  CLOUD
 SG_ VCU_HighPerforSwtFlg : 127|1@1+ (1,0) [0|1] "-"  CLOUD
 SG_ VCU_VehiPowrConsumption : 128|13@1+ (0.01,-20) [-20|50] "-"  CLOUD
 SG_ VCU_MDrvFilterTrqRange : 141|3@1+ (1,0) [0|7] "-"  CLOUD
 SG_ VCU_MRDrvControlMode : 155|1@1+ (1,0) [0|1] "-"  CLOUD
 SG_ VCU_MRDrvControlModeVD : 156|1@1+ (1,0) [0|1] "-"  CLOUD
 SG_ VCU_VehicleDirectMR : 157|1@1+ (1,0) [0|1] "-"  CLOUD
 SG_ VCU_VehicleDirectMRVD : 158|1@1+ (1,0) [0|1] "-"  CLOUD
 SG_ VCU_MRDrvRequestTorque : 160|16@1+ (0.1,-500) [-500|500] "N·m"  CLOUD
 SG_ VCU_MRDrvRequesSpeed : 176|16@1+ (1,-17000) [-17000|17000] "rpm"  CLOUD
 SG_ VCU_MCUMRMaxDischargePower : 192|9@1+ (1,0) [0|510] "kw"  CLOUD
 SG_ VCU_MCUMRMaxPosDampgTrq : 201|6@1+ (1,0) [0|50] "Nm"  CLOUD
 SG_ VCU_MRDrvRequestTorqueVD : 207|1@1+ (1,0) [0|1] "-"  CLOUD
 SG_ VCU_MCUMRMaxChargePower : 208|9@1+ (1,0) [0|510] "kw"  CLOUD
 SG_ VCU_MCUMRMaxNegDampgTrq : 217|6@1+ (1,-50) [-50|0] "Nm"  CLOUD
 SG_ VCU_MRDrvRequesSpeedVD : 223|1@1+ (1,0) [0|1] "-"  CLOUD
 SG_ VCU_MCUMRDampgLmtFactor : 224|7@1+ (1,0) [0|100] "%"  CLOUD
 SG_ VCU_SuppressJitterMCUMRRequest : 231|1@1+ (1,0) [0|1] "-"  CLOUD

BO_ 857 VCU_359: 16 VCU
 SG_ VCU_EolCfg_ESC : 0|1@1+ (1,0) [0|1] "-"  CLOUD
 SG_ VCU_EolCfg_EPB : 1|1@1+ (1,0) [0|1] "-"  CLOUD
 SG_ VCU_EolCfg_AEB : 2|1@1+ (1,0) [0|1] "-"  CLOUD
 SG_ VCU_EolCfg_InverterFunc : 3|1@1+ (1,0) [0|1] "-"  CLOUD
 SG_ VCU_EolCfg_APS : 4|1@1+ (1,0) [0|1] "-"  CLOUD
 SG_ VCU_EolCfg_VehiModels : 5|3@1+ (1,0) [0|7] "-"  CLOUD
 SG_ VCU_EolCfg_SpdLmtVal : 8|4@1+ (1,0) [0|15] "-"  CLOUD
 SG_ VCU_EolCfg_WheelType : 12|4@1+ (1,0) [0|15] "-"  CLOUD
 SG_ VCU_EolCfg_Curise : 16|2@1+ (1,0) [0|3] "-"  CLOUD
 SG_ VCU_REStartReq : 18|1@1+ (1,0) [0|1] "-"  CLOUD
 SG_ VCU_REStopReq : 19|1@1+ (1,0) [0|1] "-"  CLOUD
 SG_ VCU_EolCfg_VehiType : 20|1@1+ (1,0) [0|1] "-"  CLOUD
 SG_ VCU_EolCfg_MotPwr : 21|3@1+ (1,0) [0|7] "-"  CLOUD
 SG_ VCU_Vehicle_NVHPwrLimitVal : 24|8@1+ (1,0) [0|250] "-"  CLOUD
 SG_ VCU_EolCfg_MotDrvStructure : 32|2@1+ (1,0) [0|3] "-"  CLOUD
 SG_ VCU_WLTCModeFlag : 34|1@1+ (1,0) [0|1] "-"  CLOUD
 SG_ VCU_EolCfg_RudderDir : 35|1@1+ (1,0) [0|1] "-"  CLOUD
 SG_ VCU_EolCfg_DCChgRelayPos : 36|2@1+ (1,0) [0|3] "-"  CLOUD
 SG_ VCU_EolCfg_FPTCIL : 38|1@1+ (1,0) [0|1] "-"  CLOUD
 SG_ VCU_PWakeupSt : 39|1@1+ (1,0) [0|1] "-"  CLOUD
 SG_ VCU_SpdLimitReason : 40|3@1+ (1,0) [0|7] "-"  CLOUD
 SG_ BSW_VertifySts : 43|2@1+ (1,0) [0|3] "-"  CLOUD
 SG_ VCU_AbResetlnitFinish : 45|1@1+ (1,0) [0|1] "-"  CLOUD
 SG_ VCU_AbResetFlag : 46|1@1+ (1,0) [0|1] "-"  CLOUD
 SG_ VCU_AbStartupFlag : 47|1@1+ (1,0) [0|1] "-"  CLOUD
 SG_ VCU_InterAllowEngStart : 57|1@1+ (1,0) [0|1] "-"  CLOUD
 SG_ VCU_EngineOff_Flag : 58|1@1+ (1,0) [0|1] "-"  CLOUD
 SG_ VCU_EngineStopAllow : 59|1@1+ (1,0) [0|1] "-"  CLOUD
 SG_ VCU_EmergencyStopReq : 60|1@1+ (1,0) [0|1] "-"  CLOUD
 SG_ VCU_EngineAllowStop : 61|1@1+ (1,0) [0|1] "-"  CLOUD
 SG_ VCU_REVehiWheelTrqReq : 64|8@1+ (1,0) [0|255] "-"  CLOUD
 SG_ VCU_REHighPerformVehiPwr : 72|8@1+ (0.5,0) [0|127] "-"  CLOUD
 SG_ VCU_REPwrDampingFactor : 80|7@1+ (1,0) [0|100] "-"  CLOUD
 SG_ VCU_REDrvTarPwrFit : 87|9@1+ (0.2,0) [0|100] "-"  CLOUD
 SG_ VCU_AdditionalPwrVal : 96|8@1+ (1,0) [0|250] "-"  CLOUD
 SG_ VCU_VehichRealPwDown : 104|8@1+ (1,0) [0|255] "-"  CLOUD
 SG_ VCU_IMMOStsResult : 112|4@1+ (1,0) [0|15] "-"  CLOUD
 SG_ VCU_IMMOStateMachine : 116|3@1+ (1,0) [0|7] "-"  CLOUD
 SG_ VCU_ShowCarModeNvmResult : 119|1@1+ (1,0) [0|1] "-"  CLOUD
 SG_ VCU_DeliveryModeNvmData : 120|1@1+ (1,0) [0|1] "-"  CLOUD
 SG_ VCU_AccPedFaultLvNvmResult : 121|1@1+ (1,0) [0|1] "-"  CLOUD
 SG_ VCU_VehicleConfigNvmResult : 122|1@1+ (1,0) [0|1] "-"  CLOUD
 SG_ VCU_EngRunTimeNvmResult : 123|1@1+ (1,0) [0|1] "-"  CLOUD
 SG_ VCU_IMMOKeyWriteCnt : 124|3@1+ (1,0) [0|7] "-"  CLOUD

BO_ 867 TMS_363: 16 TMS
 SG_ TMS_RollingCounter_363 : 8|4@1+ (1,0) [0|15] "-"  VCU
 SG_ TMS_AC_Command : 22|1@1+ (1,0) [0|1] "-"  CLOUD,VCU,CCM
 SG_ TMS_PTCHeatingReq : 23|1@1+ (1,0) [0|1] "-"  CLOUD,IVI,VCU,PTC
 SG_ TMS_PTCPowerSet : 32|8@1+ (50,0) [0|10000] "W"  CLOUD,VCU,PTC
 SG_ TMS_OutsideTempVD : 55|1@1+ (1,0) [0|1] "-"  CLOUD,HPCGW,ICU,VCU,BMS,ECM
 SG_ TMS_OutsideTemp_Corrected : 64|8@1+ (0.5,-40) [-40|87] "℃"  CLOUD,HPCGW,IVI,ICU,VCU,BMS,ECM

BO_ 1534 TMS_5FE: 8 TMS
 SG_ TMS_MilLampReq : 22|2@1+ (1,0) [0|3] "-"  CLOUD,VCU

BO_ 1535 TMS_5FF: 16 TMS
 SG_ TMS_VCU_MotSelfHeatEnReq : 60|1@1+ (1,0) [0|1] "-"  CLOUD,VCU
 SG_ TMS_VCU_MotSelfHeatLvlReq : 73|4@1+ (1,0) [0|15] "-"  CLOUD,VCU

BO_ 866 TMS_362: 32 TMS
 SG_ TMS_RAPTC_ModOprtgStsFrt : 144|2@1+ (1,0) [0|3] "-"  CLOUD,VCU
 SG_ TMS_RAPTC_MsrdPwrFrt : 152|10@1+ (50,0) [0|10000] "W"  CLOUD,VCU
 SG_ TMS_RAPTC_ModOpEnblCmd : 162|1@1+ (1,0) [0|1] "-"  CLOUD,VCU

BO_ 874 CCM_36A: 16 CCM
 SG_ CCM_RollingCounter_36A : 8|4@1+ (1,0) [0|15] "-"  VCU,TMS
 SG_ CCM_BaseState : 34|3@1+ (1,0) [0|7] "-"  CLOUD,VCU,TMS
 SG_ CCM_Power : 56|8@1+ (0.05,0) [0|12] "kW"  CLOUD,ICU,VCU,BMS,TMS
 SG_ CCM_APTC_BscSts : 102|1@1+ (1,0) [0|1] "-"  CLOUD,VCU,TMS
 SG_ CCM_APTC_Power : 112|8@1+ (50,0) [0|10000] "w"  VCU,TMS

BO_ 871 PTC_367: 16 PTC
 SG_ PTC_RollingCounter_367 : 8|4@1+ (1,0) [0|15] "-"  VCU,TMS
 SG_ PTC_BscSts : 16|1@1+ (1,0) [0|1] "-"  CLOUD,VCU,ECM,TMS
 SG_ PTC_Fault : 17|1@1+ (1,0) [0|1] "-"  VCU,TMS
 SG_ PTC_Power : 32|8@1+ (50,0) [0|10000] "w"  CLOUD,ICU,VCU,BMS,ECM,TMS
 SG_ PTC_HV_interlock_faultSt : 75|1@1+ (1,0) [0|1] "-"  VCU,TMS

BO_ 1536 VCU_600: 32 VCU
 SG_ VCU_McuPwr12V_OV : 0|1@1+ (1,0) [0|1] "-"  CLOUD
 SG_ VCU_McuPwr12V_UV : 1|1@1+ (1,0) [0|1] "-"  CLOUD
 SG_ VCU_DcChgPwr_OV : 2|1@1+ (1,0) [0|1] "-"  CLOUD
 SG_ VCU_DcChgPwr_UV : 3|1@1+ (1,0) [0|1] "-"  CLOUD
 SG_ VCU_AcChgPwr_OV : 4|1@1+ (1,0) [0|1] "-"  CLOUD
 SG_ VCU_AcChgPwr_UV : 5|1@1+ (1,0) [0|1] "-"  CLOUD
 SG_ VCU_DCDC_FAULT : 6|1@1+ (1,0) [0|1] "-"  CLOUD,GB,HPCGW
 SG_ VCU_BrakeSigFault : 7|1@1+ (1,0) [0|1] "-"  CLOUD
 SG_ VCU_AccPedHPwr_UV : 8|1@1+ (1,0) [0|1] "-"  CLOUD
 SG_ VCU_AccPedHPwr_OV : 9|1@1+ (1,0) [0|1] "-"  CLOUD
 SG_ VCU_AccPedLPwr_UV : 10|1@1+ (1,0) [0|1] "-"  CLOUD
 SG_ VCU_AccPedLPwr_OV : 11|1@1+ (1,0) [0|1] "-"  CLOUD
 SG_ VCU_AccPedHSig_STB : 12|1@1+ (1,0) [0|1] "-"  CLOUD
 SG_ VCU_AccPedHSig_OV : 13|1@1+ (1,0) [0|1] "-"  CLOUD
 SG_ VCU_AccPedHSig_UV : 14|1@1+ (1,0) [0|1] "-"  CLOUD
 SG_ VCU_AccPedHSig_STGorCO : 15|1@1+ (1,0) [0|1] "-"  CLOUD
 SG_ VCU_AccPedLSig_STB : 16|1@1+ (1,0) [0|1] "-"  CLOUD
 SG_ VCU_AccPedLSig_OV : 17|1@1+ (1,0) [0|1] "-"  CLOUD
 SG_ VCU_AccPedLSig_UV : 18|1@1+ (1,0) [0|1] "-"  CLOUD
 SG_ VCU_AccPedLSig_STGorCO : 19|1@1+ (1,0) [0|1] "-"  CLOUD
 SG_ VCU_AccPedSigSyncFault : 20|1@1+ (1,0) [0|1] "-"  CLOUD
 SG_ VCU_CcmOutHvil_STBorCO : 21|1@1+ (1,0) [0|1] "-"  CLOUD
 SG_ VCU_CcmOutHvil_STG : 22|1@1+ (1,0) [0|1] "-"  CLOUD
 SG_ VCU_CcmOutHvil_SigInvalid : 23|1@1+ (1,0) [0|1] "-"  CLOUD
 SG_ VCU_HVIL_FAULT : 24|1@1+ (1,0) [0|1] "-"  CLOUD
 SG_ VCU_ACHVIL_FAULT : 25|1@1+ (1,0) [0|1] "-"  CLOUD
 SG_ VCU_DCHVIL_FAULT : 26|1@1+ (1,0) [0|1] "-"  CLOUD
 SG_ VCU_HVIL_STS_ALARM : 27|1@1+ (1,0) [0|1] "-"  CLOUD,GB,HPCGW
 SG_ VCU_MD_HV_Start_Failure_HVIL : 28|1@1+ (1,0) [0|1] "-"  CLOUD
 SG_ VCU_MD_HV_Start_Failure_MCUFault : 29|1@1+ (1,0) [0|1] "-"  CLOUD
 SG_ VCU_MD_HV_Start_Failure_BMSFault : 30|1@1+ (1,0) [0|1] "-"  CLOUD
 SG_ VCU_MD_HV_Start_Failure_OtherFau : 31|1@1+ (1,0) [0|1] "-"  CLOUD
 SG_ VCU_DcChagerTempP_OT : 32|1@1+ (1,0) [0|1] "-"  CLOUD
 SG_ VCU_DcChagerTempN_OT : 33|1@1+ (1,0) [0|1] "-"  CLOUD
 SG_ VCU_AcChagerTempP_OT : 34|1@1+ (1,0) [0|1] "-"  CLOUD
 SG_ VCU_EngineStartFailure : 35|1@1+ (1,0) [0|1] "-"  CLOUD
 SG_ VCU_EnergyRecoveryProhibit : 36|1@1+ (1,0) [0|1] "-"  CLOUD
 SG_ VIU_GW_MissMsg : 37|1@1+ (1,0) [0|1] "-"  CLOUD
 SG_ VIU_GW_RollCntErr : 38|1@1+ (1,0) [0|1] "-"  CLOUD
 SG_ VIU_GW_ChksumErr : 39|1@1+ (1,0) [0|1] "-"  CLOUD
 SG_ VCU_AcChagerTempN_OT : 40|1@1+ (1,0) [0|1] "-"  CLOUD
 SG_ VCU_MCUM_SissMsgHigh : 41|1@1+ (1,0) [0|1] "-"  CLOUD
 SG_ VCU_AuthenticationKey_Not_Write : 42|1@1+ (1,0) [0|1] "-"  CLOUD
 SG_ VCU_BCM_Authentication_Fail_or_T : 43|1@1+ (1,0) [0|1] "-"  CLOUD
 SG_ VCU_BrakeSysFault : 44|1@1+ (1,0) [0|1] "-"  CLOUD
 SG_ VCU_PGearLeverFault : 45|1@1+ (1,0) [0|1] "-"  CLOUD
 SG_ VCU_PGearLeverCounterError : 46|1@1+ (1,0) [0|1] "-"  CLOUD
 SG_ VCU_PGearLeverChecksumError : 47|1@1+ (1,0) [0|1] "-"  CLOUD
 SG_ VCU_GearChangeLeverFault : 48|1@1+ (1,0) [0|1] "-"  CLOUD
 SG_ VCU_GearChangeLeverError : 49|1@1+ (1,0) [0|1] "-"  CLOUD
 SG_ VCU_GearChangeLeverChecksumError : 50|1@1+ (1,0) [0|1] "-"  CLOUD
 SG_ VCU_CalibrationDataCrc_ERR : 51|1@1+ (1,0) [0|1] "-"  CLOUD
 SG_ VCU_CalibrationAppCrc_ERR : 52|1@1+ (1,0) [0|1] "-"  CLOUD
 SG_ VCU_CalibrationRead_ERR : 53|1@1+ (1,0) [0|1] "-"  CLOUD
 SG_ VCU_MCUM_MissMsgHigh : 54|1@1+ (1,0) [0|1] "-"  CLOUD
 SG_ VCU_CalibrationVerifyErr : 55|1@1+ (1,0) [0|1] "-"  CLOUD
 SG_ VCU_McuSeriousFaultyFor4WD : 56|1@1+ (1,0) [0|1] "-"  CLOUD
 SG_ VCU_McuFaultyFor4WDType1 : 57|1@1+ (1,0) [0|1] "-"  CLOUD
 SG_ VCU_McuFaultyFor4WDType2 : 58|1@1+ (1,0) [0|1] "-"  CLOUD
 SG_ VCU_CrashFaulty : 59|1@1+ (1,0) [0|1] "-"  CLOUD
 SG_ VCU_MCUS_PrivateCANMissMsg : 60|1@1+ (1,0) [0|1] "-"  CLOUD
 SG_ VCU_MCUS_PrivateCANRollCntErr : 61|1@1+ (1,0) [0|1] "-"  CLOUD
 SG_ VCU_MCUS_PrivateCANChksumErr : 62|1@1+ (1,0) [0|1] "-"  CLOUD
 SG_ VCU_DCDC12VLowFault : 63|1@1+ (1,0) [0|1] "-"  CLOUD
 SG_ VCU_ECMRequestMIL : 64|1@1+ (1,0) [0|1] "-"  CLOUD
 SG_ VCU_GCURequestMIL : 65|1@1+ (1,0) [0|1] "-"  CLOUD
 SG_ VCU_MCURequestMIL : 66|1@1+ (1,0) [0|1] "-"  CLOUD
 SG_ VCU_BMSRequestMIL : 67|1@1+ (1,0) [0|1] "-"  CLOUD
 SG_ VCU_IBCRequestMIL : 68|1@1+ (1,0) [0|1] "-"  CLOUD
 SG_ VCU_TMSRequestMIL : 69|1@1+ (1,0) [0|1] "-"  CLOUD
 SG_ VCU_VCURequestMIL : 70|1@1+ (1,0) [0|1] "-"  CLOUD
 SG_ VCU_CCANFD_Busoff : 71|1@1+ (1,0) [0|1] "-"  CLOUD
 SG_ VCU_PCANFD_Busoff : 72|1@1+ (1,0) [0|1] "-"  CLOUD
 SG_ VCU_MCUS_MissMsg : 73|1@1+ (1,0) [0|1] "-"  CLOUD
 SG_ VCU_MCUS_RollCntErr : 74|1@1+ (1,0) [0|1] "-"  CLOUD
 SG_ VCU_MCUS_ChksumErr : 75|1@1+ (1,0) [0|1] "-"  CLOUD
 SG_ VCU_MCUM_MissMsg : 76|1@1+ (1,0) [0|1] "-"  CLOUD
 SG_ VCU_MCUM_RollCntErr : 77|1@1+ (1,0) [0|1] "-"  CLOUD
 SG_ VCU_MCUM_ChksumErr : 78|1@1+ (1,0) [0|1] "-"  CLOUD
 SG_ VCU_BMS_MissMsg : 79|1@1+ (1,0) [0|1] "-"  CLOUD
 SG_ VCU_BMS_RollCntErr : 80|1@1+ (1,0) [0|1] "-"  CLOUD
 SG_ VCU_BMS_ChksumErr : 81|1@1+ (1,0) [0|1] "-"  CLOUD
 SG_ VCU_DCDC_MissMsg : 82|1@1+ (1,0) [0|1] "-"  CLOUD
 SG_ VCU_DCDC_RollCntErr : 83|1@1+ (1,0) [0|1] "-"  CLOUD
 SG_ VCU_DCDC_ChksumErr : 84|1@1+ (1,0) [0|1] "-"  CLOUD
 SG_ VCU_OBC_MissMsg : 85|1@1+ (1,0) [0|1] "-"  CLOUD
 SG_ VCU_OBC_RollCntErr : 86|1@1+ (1,0) [0|1] "-"  CLOUD
 SG_ VCU_OBC_ChksumErr : 87|1@1+ (1,0) [0|1] "-"  CLOUD
 SG_ VCU_ACU_MissMsg : 88|1@1+ (1,0) [0|1] "-"  CLOUD
 SG_ VCU_ACU_RollCntErr : 89|1@1+ (1,0) [0|1] "-"  CLOUD
 SG_ VCU_ACU_ChksumErr : 90|1@1+ (1,0) [0|1] "-"  CLOUD
 SG_ VCU_IBC_MissMsg : 91|1@1+ (1,0) [0|1] "-"  CLOUD
 SG_ VCU_IBC_RollCntErr : 92|1@1+ (1,0) [0|1] "-"  CLOUD
 SG_ VCU_IBC_ChksumErr : 93|1@1+ (1,0) [0|1] "-"  CLOUD
 SG_ VCU_EPS_MissMsg : 94|1@1+ (1,0) [0|1] "-"  CLOUD
 SG_ VCU_EPS_RollCntErr : 95|1@1+ (1,0) [0|1] "-"  CLOUD
 SG_ VCU_EPS_ChksumErr : 96|1@1+ (1,0) [0|1] "-"  CLOUD
 SG_ VCU_BCM_MissMsg : 97|1@1+ (1,0) [0|1] "-"  CLOUD
 SG_ VCU_BCM_RollCntErr : 98|1@1+ (1,0) [0|1] "-"  CLOUD
 SG_ VCU_BCM_ChksumErr : 99|1@1+ (1,0) [0|1] "-"  CLOUD
 SG_ VCU_ICU_MissMsg : 100|1@1+ (1,0) [0|1] "-"  CLOUD
 SG_ VCU_ICU_RollCntErr : 101|1@1+ (1,0) [0|1] "-"  CLOUD
 SG_ VCU_ICU_ChksumErr : 102|1@1+ (1,0) [0|1] "-"  CLOUD
 SG_ VCU_IVI_MissMsg : 103|1@1+ (1,0) [0|1] "-"  CLOUD
 SG_ VCU_IVI_RollCntErr : 104|1@1+ (1,0) [0|1] "-"  CLOUD
 SG_ VCU_IVI_ChksumErr : 105|1@1+ (1,0) [0|1] "-"  CLOUD
 SG_ VCU_ECM_MissMsg : 106|1@1+ (1,0) [0|1] "-"  CLOUD
 SG_ VCU_ECM_ChksumErr : 107|1@1+ (1,0) [0|1] "-"  CLOUD
 SG_ VCU_ECM_RollCntErr : 108|1@1+ (1,0) [0|1] "-"  CLOUD
 SG_ VCU_GCU_MissMsg : 109|1@1+ (1,0) [0|1] "-"  CLOUD
 SG_ VCU_GCU_ChksumErr : 110|1@1+ (1,0) [0|1] "-"  CLOUD
 SG_ VCU_GCU_RollCntErr : 111|1@1+ (1,0) [0|1] "-"  CLOUD
 SG_ VCU_ACC_MissMsg : 112|1@1+ (1,0) [0|1] "-"  CLOUD
 SG_ VCU_ACC_RollCntErr : 113|1@1+ (1,0) [0|1] "-"  CLOUD
 SG_ VCU_ACC_ChksumErr : 114|1@1+ (1,0) [0|1] "-"  CLOUD
 SG_ VCU_APS_MissMsg : 115|1@1+ (1,0) [0|1] "-"  CLOUD
 SG_ VCU_APS_RollCntErr : 116|1@1+ (1,0) [0|1] "-"  CLOUD
 SG_ VCU_APS_ChksumErr : 117|1@1+ (1,0) [0|1] "-"  CLOUD
 SG_ VCU_ParkingSignal_Fault : 118|1@1+ (1,0) [0|1] "-"  CLOUD
 SG_ VCU_FSC_Loss_Communication : 119|1@1+ (1,0) [0|1] "-"  CLOUD
 SG_ VCU_FSC_Counter_Error : 120|1@1+ (1,0) [0|1] "-"  CLOUD
 SG_ VCU_FSC_Checksum_Error : 121|1@1+ (1,0) [0|1] "-"  CLOUD
 SG_ VCU_LMC_MissMSg : 122|1@1+ (1,0) [0|1] "-"  CLOUD
 SG_ VCU_LMC_ChksumErr : 123|1@1+ (1,0) [0|1] "-"  CLOUD
 SG_ VCU_LMC_RollCntErr : 124|1@1+ (1,0) [0|1] "-"  CLOUD
 SG_ GW_TCM_MissMsg : 125|1@1+ (1,0) [0|1] "-"  CLOUD
 SG_ GW_TCM_RollCntErr : 126|1@1+ (1,0) [0|1] "-"  CLOUD
 SG_ GW_TCM_ChksumErr : 127|1@1+ (1,0) [0|1] "-"  CLOUD
 SG_ VCU_IBS_LossComm : 128|1@1+ (1,0) [0|1] "-"  CLOUD
 SG_ VCU_IBS_CounterErr : 129|1@1+ (1,0) [0|1] "-"  CLOUD
 SG_ VCU_IBS_ChecksumErr : 130|1@1+ (1,0) [0|1] "-"  CLOUD
 SG_ Dtc_IBS_FAULTHigh : 131|1@1+ (1,0) [0|1] "-"  CLOUD
 SG_ VCU_CCM_LossComm : 132|1@1+ (1,0) [0|1] "-"  CLOUD
 SG_ VCU_CCM_CounterErr : 133|1@1+ (1,0) [0|1] "-"  CLOUD
 SG_ VCU_CCM_ChecksumErr : 134|1@1+ (1,0) [0|1] "-"  CLOUD
 SG_ VCU_PTC_LossComm : 135|1@1+ (1,0) [0|1] "-"  CLOUD
 SG_ VCU_PTC_CounterErr : 136|1@1+ (1,0) [0|1] "-"  CLOUD
 SG_ VCU_PTC_ChecksumErr : 137|1@1+ (1,0) [0|1] "-"  CLOUD
 SG_ VCU_TMS_LossComm : 138|1@1+ (1,0) [0|1] "-"  CLOUD
 SG_ VCU_TMS_CounterErr : 139|1@1+ (1,0) [0|1] "-"  CLOUD
 SG_ VCU_TMS_ChecksumErr : 140|1@1+ (1,0) [0|1] "-"  CLOUD
 SG_ VCU_IMU_LossComm : 141|1@1+ (1,0) [0|1] "-"  CLOUD
 SG_ VCU_IMU_CounterErr : 142|1@1+ (1,0) [0|1] "-"  CLOUD
 SG_ VCU_IMU_ChecksumErr : 143|1@1+ (1,0) [0|1] "-"  CLOUD
 SG_ VCU_Prvt_CAN_BUS_OFF : 144|1@1+ (1,0) [0|1] "-"  CLOUD
 SG_ VCU_IMU_Cali_CounterErr : 145|1@1+ (1,0) [0|1] "-"  CLOUD
 SG_ VCU_ASR_Fault : 146|1@1+ (1,0) [0|1] "-"  CLOUD
 SG_ VCU_DTC_Fault : 147|1@1+ (1,0) [0|1] "-"  CLOUD
 SG_ VCU_VDC_Fault : 148|1@1+ (1,0) [0|1] "-"  CLOUD
 SG_ VCU_ACU_Trigger_Fault : 149|1@1+ (1,0) [0|1] "-"  CLOUD
 SG_ VCU_DMC_Front_Motor_Input_Signal : 150|1@1+ (1,0) [0|1] "-"  CLOUD
 SG_ VCU_DMC_Rear_Motor_Input_Signal_ : 151|1@1+ (1,0) [0|1] "-"  CLOUD

CM_ SG_ 484 BCM_VCU_Authentication_Challenge "BCM与VCU认证随机数A0";
CM_ SG_ 484 BCM_VCU_Authentication_Chal_0000 "BCM与VCU认证随机数A1";
CM_ SG_ 484 BCM_VCU_Authentication_Chal_0001 "BCM与VCU认证随机数A2";
CM_ SG_ 484 BCM_VCU_Authentication_Chal_0002 "BCM与VCU认证随机数A3";
CM_ SG_ 485 VCU_BCM_Authentication_MAC_A0 "VCU与BCM认证MAC值A0";
CM_ SG_ 485 VCU_BCM_Authentication_MAC_A1 "VCU与BCM认证MAC值A1";
CM_ SG_ 485 VCU_BCM_Authentication_MAC_A2 "VCU与BCM认证MAC值A2";
CM_ SG_ 485 VCU_BCM_Authentication_MAC_A3 "VCU与BCM认证MAC值A3";
CM_ SG_ 485 VCU_BCM_Authentication_MAC_A4 "VCU与BCM认证MAC值A4";
CM_ SG_ 485 VCU_BCM_Authentication_MAC_A5 "VCU与BCM认证MAC值A5";
CM_ SG_ 485 VCU_BCM_Authentication_MAC_A6 "VCU与BCM认证MAC值A6";
CM_ SG_ 485 VCU_BCM_Authentication_MAC_A7 "VCU与BCM认证MAC值A7";
CM_ SG_ 485 VCU_BCM_Authentication_MAC_A8 "VCU与BCM认证MAC值A8";
CM_ SG_ 485 VCU_BCM_Authentication_MAC_A9 "VCU与BCM认证MAC值A9";
CM_ SG_ 485 VCU_BCM_Authentication_MAC_A10 "VCU与BCM认证MAC值A10";
CM_ SG_ 485 VCU_BCM_Authentication_MAC_A11 "VCU与BCM认证MAC值A11";
CM_ SG_ 485 VCU_BCM_Authentication_MAC_A12 "VCU与BCM认证MAC值A12";
CM_ SG_ 485 VCU_BCM_Authentication_MAC_A13 "VCU与BCM认证MAC值A13";
CM_ SG_ 485 VCU_BCM_Authentication_MAC_A14 "VCU与BCM认证MAC值A14";
CM_ SG_ 485 VCU_BCM_Authentication_MAC_A15 "VCU与BCM认证MAC值A15";
CM_ SG_ 485 VCU_BCM_Authentication_Challenge "VCU与BCM认证随机数B0";
CM_ SG_ 485 VCU_BCM_Authentication_Chal_0000 "VCU与BCM认证随机数B1";
CM_ SG_ 485 VCU_BCM_Authentication_Chal_0001 "VCU与BCM认证随机数B2";
CM_ SG_ 485 VCU_BCM_Authentication_Chal_0002 "VCU与BCM认证随机数B3";
CM_ SG_ 486 BCM_VCU_Authentication_MAC_B0 "BCM与VCU认证MAC值B0";
CM_ SG_ 486 BCM_VCU_Authentication_MAC_B1 "BCM与VCU认证MAC值B1";
CM_ SG_ 486 BCM_VCU_Authentication_MAC_B2 "BCM与VCU认证MAC值B2";
CM_ SG_ 486 BCM_VCU_Authentication_MAC_B3 "BCM与VCU认证MAC值B3";
CM_ SG_ 486 BCM_VCU_Authentication_MAC_B4 "BCM与VCU认证MAC值B4";
CM_ SG_ 486 BCM_VCU_Authentication_MAC_B5 "BCM与VCU认证MAC值B5";
CM_ SG_ 486 BCM_VCU_Authentication_MAC_B6 "BCM与VCU认证MAC值B6";
CM_ SG_ 486 BCM_VCU_Authentication_MAC_B7 "BCM与VCU认证MAC值B7";
CM_ SG_ 486 BCM_VCU_Authentication_MAC_B8 "BCM与VCU认证MAC值B8";
CM_ SG_ 486 BCM_VCU_Authentication_MAC_B9 "BCM与VCU认证MAC值B9";
CM_ SG_ 486 BCM_VCU_Authentication_MAC_B10 "BCM与VCU认证MAC值B10";
CM_ SG_ 486 BCM_VCU_Authentication_MAC_B11 "BCM与VCU认证MAC值B11";
CM_ SG_ 486 BCM_VCU_Authentication_MAC_B12 "BCM与VCU认证MAC值B12";
CM_ SG_ 486 BCM_VCU_Authentication_MAC_B13 "BCM与VCU认证MAC值B13";
CM_ SG_ 486 BCM_VCU_Authentication_MAC_B14 "BCM与VCU认证MAC值B14";
CM_ SG_ 486 BCM_VCU_Authentication_MAC_B15 "BCM与VCU认证MAC值B15";
CM_ SG_ 223 ICU_CRC_DF "校验位";
CM_ SG_ 223 ICU_RollingCounter_DF "生命信号";
CM_ SG_ 223 ICU_IMU_ACC_x "惯性传感器在X方向上的加速度";
CM_ SG_ 223 ICU_IMU_ACC_y "惯性传感器在y方向上的加速度";
CM_ SG_ 223 ICU_IMU_ACC_z "惯性传感器在z方向上的加速度";
CM_ SG_ 223 ICU_IMU_ACC_Roll_Rate "惯性传感器绕x方向上的角速度";
CM_ SG_ 223 ICU_IMU_ACC_Pitch_Rate "惯性传感器绕y方向上的角速度";
CM_ SG_ 223 ICU_IMU_ACC_Yaw_Rate "惯性传感器绕z方向上的角速度";
CM_ SG_ 223 ICU_IMU_Calibrated "6D 惯性传感器标定信息";
CM_ SG_ 223 ICU_IMU_Valid "惯性传感器信号有效性";
CM_ SG_ 315 VCU_CRC_13B "校验位";
CM_ SG_ 315 VCU_RollingCounter_13B "生命信号";
CM_ SG_ 315 VCU_Vehicle_Warning "整车故障报警";
CM_ SG_ 315 VCU_VehicleSts "整车状态";
CM_ SG_ 315 VCU_GearLevelPosSts "档位信号";
CM_ SG_ 315 VCU_GearLeverValid "档位信号有效性";
CM_ SG_ 315 VCU_AccPedalValid "加速踏板有效性";
CM_ SG_ 315 VCU_ThrottlePosition "加速踏板位置信号";
CM_ SG_ 315 VCU_BMSMainRelayR_Cmd "后向BMS主继电器命令";
CM_ SG_ 315 VCU_BMSMainRelayF_Cmd "前向BMS主继电器命令";
CM_ SG_ 315 VCU_BMSEmergencyCmd "BMS紧急命令";
CM_ SG_ 315 VCU_MCUMActiveReleaseCmd "MCUM主动泄放命令";
CM_ SG_ 315 VCU_MCUSActiveReleaseCmd "MCUS主动泄放命令";
CM_ SG_ 315 VCU_AlwACChargeInventerSts "慢充/逆变允许";
CM_ SG_ 315 VCU_AlwDCChargeSts "快充允许";
CM_ SG_ 315 VCU_ChargePauseReq "充电暂停请求";
CM_ SG_ 315 VCU_SuppressJitterMCUSRequest "关闭辅电机抑制抖动";
CM_ SG_ 315 VCU_DCDCEnableCmd "DCDC使能信号";
CM_ SG_ 315 VCU_ACOffReq "空调关闭特殊请求";
CM_ SG_ 315 VCU_VehicleDirect "车辆方向";
CM_ SG_ 315 VCU_BrakeSysFault "制动系统故障状态";
CM_ SG_ 315 VCU_SuppressJitterMCUMRequest "关闭主电机抑制抖动";
CM_ SG_ 315 VCU_MDrvControlMode "主电机转速扭矩控制选择位";
CM_ SG_ 315 VCU_BrakePedalValue "刹车踏板位置信号";
CM_ SG_ 315 VCU_MCUMMaxDischargePower "主电机最大允许放电功率";
CM_ SG_ 315 VCU_MCUMMaxChargePower "主电机最大允许充电功率";
CM_ SG_ 315 VCU_MDrvRequestTorque "主电机扭矩控制值";
CM_ SG_ 315 VCU_MDrvRequesSpeed "主电机转速控制";
CM_ SG_ 315 VCU_SDrvRequestTorque "辅电机扭矩控制值";
CM_ SG_ 315 VCU_SDrvRequesSpeed "辅电机转速控制";
CM_ SG_ 315 VCU_SVehicleSts "辅电机驱动回路状态";
CM_ SG_ 315 VCU_VehicleHighVoltModeF "VCU高压模式前";
CM_ SG_ 315 VCU_SDrvControlMode "辅电机转速扭矩控制选择位";
CM_ SG_ 315 VCU_ON2BRelayReq "ON2B继电器请求";
CM_ SG_ 315 VCU_VehPreHVPwrOffCmd "整车高压预下电指令";
CM_ SG_ 315 VCU_FuelTankLockReq "加油口盖解闭锁请求";
CM_ SG_ 315 VCU_VehicleDirectS "辅轴车辆方向";
CM_ SG_ 315 VCU_VehicleDirectS_VD "辅轴车辆方向有效性";
CM_ SG_ 315 VCU_ACPwrLimited "空调可用功率";
CM_ SG_ 315 VCU_MCUSMaxDischargePower "辅电机最大允许放电功率";
CM_ SG_ 315 VCU_VehicleDirectVD "车辆方向有效性";
CM_ SG_ 315 VCU_MDrvControlModeVD "主电机转速扭矩控制选择位有效性";
CM_ SG_ 315 VCU_MDrvRequestTorqueVD "主电机扭矩控制值有效性";
CM_ SG_ 315 VCU_MDrvRequesSpeedVD "主电机转速控制有效性";
CM_ SG_ 315 VCU_SDrvRequestTorqueVD "辅电机扭矩控制值有效性";
CM_ SG_ 315 VCU_SDrvRequesSpeedVD "辅电机转速控制有效性";
CM_ SG_ 315 VCU_SDrvControlModeVD "辅电机转速扭矩控制选择位有效性";
CM_ SG_ 315 VCU_MCUSMaxChargePower "辅电机最大允许充电功率";
CM_ SG_ 315 VCU_VehicleHighVoltMode "VCU高压模式";
CM_ SG_ 315 VCU_PDUHVIL_Sts "PDU高压互锁状态";
CM_ SG_ 315 VCU_PDU220VRelay_Req "PDU220V继电器请求";
CM_ SG_ 315 VCU_Cab220VRelay_Req "室内220V继电器请求";
CM_ SG_ 315 VCU_Cabin220VRelay_Req "发动机舱220V继电器请求";
CM_ SG_ 315 VCU_Alw_Cab220VInverter_Sts "室内220V逆变允许";
CM_ SG_ 315 VCU_Alw_Cabin220VInverter_Sts "发动机舱220V逆变允许";
CM_ SG_ 315 VCU_MCUMDampgLmtFactor "主驱抑抖限制系数";
CM_ SG_ 315 VCU_MCUSDampgLmtFactor "辅驱抑抖限制系数";
CM_ SG_ 315 VCU_BCM_Authentication_Sts "VCU_与BCM认证状态";
CM_ SG_ 315 VCU_AuthenticationKey_WSts "VCU认证密钥写入状态";
CM_ SG_ 315 VCU_BrakePedalSts_P "刹车开关状态_P";
CM_ SG_ 315 VCU_BrakePedalStsValid_P "刹车开关状态有效性_P";
CM_ SG_ 315 VCU_BoostMode_Fail "弹射模式开启失败";
CM_ SG_ 315 VCU_BoostModeSts "弹射模式状态";
CM_ SG_ 315 VCU_MCUSMaxPosDampgTrq "辅驱最大允许抑抖补偿正扭";
CM_ SG_ 315 VCU_MCUSMaxNegDampgTrq "辅驱最大允许抑抖补偿负扭";
CM_ SG_ 315 VCU_MCUMMaxPosDampgTrq "主驱最大允许抑抖补偿正扭";
CM_ SG_ 315 VCU_MCUMMaxNegDampgTrq "主驱最大允许抑抖补偿负扭";
CM_ SG_ 188 VCU_VehicleSpdDirect "计算方向后的整车车速";
CM_ SG_ 188 VCU_DeliveryModeSts "交付模式开启状态";
CM_ SG_ 188 VCU_VehSpdLimtRemind "解除限速提醒";
CM_ SG_ 188 VCU_SinglePedalSts "单踏板模式功能状态";
CM_ SG_ 188 VCU_GearLvrChangeSts "换挡功能状态";
CM_ SG_ 188 VCU_HighVoltSysSts "高压系统状态";
CM_ SG_ 188 VCU_ChrgDischrgFunSts "充电/逆变功能状态";
CM_ SG_ 188 VCU_CalibrationVersion "VCU标定文件版本号";
CM_ SG_ 188 VCU_CalibrationNumber "VCU标定文件序号";
CM_ SG_ 188 VCU_VehicleNegTrqRspdSts "整车负扭响应状态";
CM_ SG_ 188 VCU_SlopeEst "道路坡道估算值";
CM_ SG_ 188 VCU_SlopeEst_Valid "道路坡道估算值有效性";
CM_ SG_ 188 VCU_WheelTrqType "扭矩类型";
CM_ SG_ 188 VCU_DriverAssistProhibitSts "驾驶辅助功能禁用状态";
CM_ SG_ 188 VCU_VacumRlySts "真空泵继电器状态";
CM_ SG_ 188 VCU_DriveSHVILSts "辅驱动HVIL状态";
CM_ SG_ 188 VCU_DriveMHVILSts "主驱动HVIL状态";
CM_ SG_ 188 VCU_DCChgHVILSts "快充HVIL状态";
CM_ SG_ 188 VCU_ACChgHVILSts "慢充HVIL状态";
CM_ SG_ 188 VCU_CCMHVILSts "CCM高压互锁状态";
CM_ SG_ 188 VCU_SystemError "系统故障";
CM_ SG_ 188 VCU_AccPedalFaultLV "加速踏板故障等级";
CM_ SG_ 188 VCU_HVILSysSts "高压互锁系统状态";
CM_ SG_ 188 VCU_VacuumDegree "真空度值";
CM_ SG_ 188 VCU_LPedalModeSts "单踏板模式状态";
CM_ SG_ 188 VCU_LVSystemError "低压系统故障";
CM_ SG_ 188 VCU_HVSystemError "高压系统故障";
CM_ SG_ 188 VCU_OpeartingMode "VCU运行模式";
CM_ SG_ 188 VCU_EnergyMode "整车能源模式";
CM_ SG_ 188 VCU_GearLevelPosFault "TCM档位故障";
CM_ SG_ 188 VCU_BrakeSwitchSts "刹车开关硬线信号";
CM_ SG_ 188 VCU_SpdLimModeSts "限速模式状态反馈";
CM_ SG_ 188 VCU_TrqDstrbutnPrio "VCU扭矩分配优先级";
CM_ SG_ 188 VCU_TrqDstrbutnTransferSts "VCU扭矩分配转移状态";
CM_ SG_ 188 VCU_MCUMDiffProtectSts "主驱差速保护功能状态";
CM_ SG_ 188 VCU_MCUSDiffProtectSts "辅驱差速保护功能状态";
CM_ SG_ 188 VCU_ADM_MainMode "自适应驾驶模式主模式";
CM_ SG_ 188 VCU_ADM_ActualMode "自适应驾驶模式实际模式";
CM_ SG_ 856 VCU_MotSelfHeatPwrFb "实际加热电功率";
CM_ SG_ 856 VCU_HeatPwrAval "可用加热电功率";
CM_ SG_ 856 VCU_MotSelfHeatAllwd "加热允许状态";
CM_ SG_ 856 VCU_MMotSelfHeatEnReq "主电机加热使能";
CM_ SG_ 856 VCU_MMotSelfHeatLvlReq "主电机加热等级";
CM_ SG_ 856 VCU_SMotSelfHeatEnReq "辅电机加热使能";
CM_ SG_ 856 VCU_SMotSelfHeatLvlReq "辅电机加热等级";
CM_ SG_ 856 VCU_MotSelfHeatLvlFb "实际加热等级";
CM_ SG_ 856 VCU_MCUMWaterPumpLevlReq "主电机水泵开度请求";
CM_ SG_ 856 VCU_MCUSWaterPumpLevlReq "辅电机水泵开度请求";
CM_ SG_ 1300 VCU_FuelConsumption "油耗";
CM_ SG_ 1300 VCU_SVSLamp "SVS Lamp";
CM_ SG_ 1300 VCU_MilLamp "MIL lamp";
CM_ SG_ 1300 VCU_SinglePedalSts "单踏板模式功能状态";
CM_ SG_ 1300 VCU_GearLevelPosFault "档位故障";
CM_ SG_ 1300 VCU_EngineStartFailure "发动机启动失败提示";
CM_ SG_ 1300 VCU_ParkBeforeFuelup "驻车加油提示";
CM_ SG_ 1300 VCU_REsystemFaultSts "增程系统故障状态";
CM_ SG_ 1300 VCU_EngineRunAllowFlg "允许发动机运行标志";
CM_ SG_ 1300 VCU_InverterTip "逆变放电提示";
CM_ SG_ 1300 VCU_EMSRepairModeSts "发动机保养模式状态";
CM_ SG_ 1300 VCU_FuelTankFlapSts "加油口盖未关闭显示";
CM_ SG_ 1300 VCU_REsystemSts "增程系统状态";
CM_ SG_ 1300 VCU_PowerModeAllow "动力优先模式允许";
CM_ SG_ 1300 VCU_PowerModeSwitchMsg "动力优先模式切换提示";
CM_ SG_ 1300 VCU_HighVoltFailed_M "主驱高压启动失败";
CM_ SG_ 1300 VCU_HighVoltFailed_S "辅驱高压启动失败";
CM_ SG_ 1300 VCU_BrakeBeforeGear "请踩刹车再挂挡";
CM_ SG_ 1300 VCU_ParkBeforeGear "请停车后再挂挡";
CM_ SG_ 1300 VCU_GearBeforDriving "请先挂挡再行车";
CM_ SG_ 1300 VCU_UnlockBeforeDriving "请先解开驻车再行车";
CM_ SG_ 1300 VCU_PreventSliding "请防止车辆滑动";
CM_ SG_ 1300 VCU_MMErrorSts "辅驱回路故障";
CM_ SG_ 1300 VCU_ShowCarModeSts "展车模式状态";
CM_ SG_ 1300 VCU_PGearFlashSts "P档闪烁状态";
CM_ SG_ 1300 VCU_ACConnectSts "慢充枪连接状态";
CM_ SG_ 1300 VCU_DcChgPwrSts "快充枪连接状态";
CM_ SG_ 1300 VCU_DriverAssistProhibitSts "驾驶辅助功能禁用状态";
CM_ SG_ 1300 VCU_MilLampRequest "整车控制器MIL灯点亮请求";
CM_ SG_ 1300 VCU_CcmHvilInSigFreq_FB "压缩机高压互锁pwm频率";
CM_ SG_ 1300 VCU_CcmHvilInSigDuty_FB "压缩机高压互锁pwm占空比";
CM_ SG_ 1300 VCU_FuelDectionModeSts "燃油检测模式状态";
CM_ SG_ 1300 VCU_EnergyCtrlMode "整车能量控制模式";
CM_ SG_ 1300 VCU_VehSpdLimtRemind "解除限速提醒";
CM_ SG_ 1300 VCU_TurtleLamp "乌龟灯点亮请求";
CM_ SG_ 1300 VCU_EngLongTimeStartReq "增程器定时启动需求";
CM_ SG_ 1301 VCU_Pending_DTC "VCU未决故障";
CM_ SG_ 1301 VCU_Comfirmed_DTC "VCU确认故障";
CM_ SG_ 1301 VCU_Permanent_DTC "VCU永久故障";
CM_ SG_ 1301 VCU_MilReq_DTC "VCU MIL灯点亮故障";
CM_ SG_ 588 ICU_CRC_24C "校验位";
CM_ SG_ 588 ICU_RollingCounter_24C "生命信号";
CM_ SG_ 588 ICU_AccelerationMode "加速模式";
CM_ SG_ 588 ICU_REMode "增程模式";
CM_ SG_ 588 ICU_CreepMode "蠕行模式";
CM_ SG_ 588 ICU_EnergyRecoveryMode "能量回收模式";
CM_ SG_ 588 ICU_PHEVMode "混动模式";
CM_ SG_ 585 ICU_TotalOilmeterkm "燃油总里程";
CM_ SG_ 585 ICU_CLTCoilMileage "CLTC油续航里程";
CM_ SG_ 585 ICU_WLTC_oilMileage "WLTC油续航里程";
CM_ SG_ 585 ICU_CLTC_ElectticityMileage "CLTC电续航里程";
CM_ SG_ 585 ICU_WLTC_ElectticityMileage "WLTC电续航里程";
CM_ SG_ 585 ICU_Switch_CLTCOrWLTC "CLTC/WLTC开关切换";
CM_ SG_ 585 ICU_FuelPercent "燃油百分比";
CM_ SG_ 657 BCM_CRC_291 "校验位";
CM_ SG_ 657 BCM_RollingCounter_291 "生命信号";
CM_ SG_ 657 BCM_ShutdownMode "物理开关断电模式";
CM_ SG_ 657 BCM_KeyPosition_ON2A "ON2A电源";
CM_ SG_ 657 BCM_CcmHvilSts "CCM高压互锁状态";
CM_ SG_ 657 BCM_ON2BRelaySts "ON2B继电器状态";
CM_ SG_ 657 BCM_ON2CRelaySts "ON2C继电器状态";
CM_ SG_ 657 BCM_ON2InitiativeSts "ON2主动上电状态";
CM_ SG_ 657 BCM_VehicleRepairMode "整车维修模式";
CM_ SG_ 657 BCM_VehlockCtrl "整车解闭锁控制";
CM_ SG_ 657 BCM_VehLockSts "整车解闭锁状态";
CM_ SG_ 657 BCM_FuelTankLockReq "加油口盖解闭锁请求";
CM_ SG_ 657 BCM_ACChgLockCtrl "慢充电插头锁控制";
CM_ SG_ 657 BCM_ChargeLockCtrl "充电口盖锁解闭锁控制";
CM_ SG_ 657 BCM_DCChrgPwr_Sts "快充唤醒源状态";
CM_ SG_ 657 BCM_ACChrgPwr_Sts "慢充唤醒源状态";
CM_ SG_ 657 BCM_DCChrgPwr_Volt "快充唤醒源电压值";
CM_ SG_ 657 BCM_ACChrgPwr_Volt "慢充唤醒源电压值";
CM_ SG_ 657 BCM_KeyPosition_ON2B "ON2B电源";
CM_ SG_ 657 BCM_NM_PNC_ON_1ADr_Sts "NM_PNC_ON_1ADr状态";
CM_ SG_ 657 BCM_NM_PNC_ON_3Ch_Sts "NM_PNC_ON_3Ch状态";
CM_ SG_ 657 BCM_HighVoltageReq "上高压请求";
CM_ SG_ 658 BCM_VCU_Authentication_Sts "BCM_与VCU认证状态";
CM_ SG_ 658 BCM_PTCLossMissErr "PTC通讯丢失故障";
CM_ SG_ 658 BCM_PTCRollCntErr "PTC生命信号故障";
CM_ SG_ 658 BCM_PTCChksumErr "PTC校验信号故障";
CM_ SG_ 658 BCM_PDUHVIL_STs "PDU高压互锁状态";
CM_ SG_ 658 BCM_Cab220VHVIL_STs "室内220V高压互锁状态";
CM_ SG_ 658 BCM_Cabin220VHVIL_STs "机舱220V高压互锁状态";
CM_ SG_ 945 GW_CRC_3B1 "校验位";
CM_ SG_ 945 GW_RollingCounter_3B1 "生命信号";
CM_ SG_ 945 GW_ZCUB_DCChgExitTemp_Pos "快速充电口+温度";
CM_ SG_ 945 GW_ZCUB_DCChgExitTemp_Neg "快速充电口-温度";
CM_ SG_ 945 GW_ZCUB_ACChgExitTemp_Pos "慢速充电口+温度";
CM_ SG_ 945 GW_ZCUB_FuelTankSts "加油口盖状态";
CM_ SG_ 945 GW_ZCUB_ACChgExitTemp_Neg "慢速充电口-温度";
CM_ SG_ 945 GW_ZCUB_FuelTankStsLockSts "加油口盖锁状态";
CM_ SG_ 945 GW_ZCUB_FuelTankLockCtrl "加油口盖锁控制状态";
CM_ SG_ 945 GW_ZCUB_ACChgLockSts "慢充电插头锁状态";
CM_ SG_ 945 GW_RZCU_Cabin_220Vconnect_Sts "发动机舱220V插座连接状态";
CM_ SG_ 945 GW_ZCUB_Cab_220VRelay_CtrlSts "室内220V继电器控制状态";
CM_ SG_ 945 GW_ZCUB_Cab_PDU220VRelay_CtrlSts "PDU继电器控制状态";
CM_ SG_ 945 GW_ZCUB_Cabin_220VRelay_CtrlSts "发动机舱220V继电器控制状态";
CM_ SG_ 945 GW_ZCUB_Cab_220Vconnect_Sts "室内220V插座连接状态";
CM_ SG_ 945 GW_TBOXSOC_Altitude "海拔高度";
CM_ SG_ 779 GW_TCM_CRC_30B "校验位";
CM_ SG_ 779 GW_TCM_RollingCounter_30B "生命信号";
CM_ SG_ 779 GW_TCM_ParkingSwSts "P档开关信号";
CM_ SG_ 779 GW_TCM_STATUS_Park "P档开关品质因子";
CM_ SG_ 779 GW_TCM_Counter_Park "P档开关生命信号";
CM_ SG_ 779 GW_TCM_CRC_Park "P档开关校验位";
CM_ SG_ 779 GW_TCM_GearLevelSwitchSts "档位开关信号";
CM_ SG_ 779 GW_TCM_STATUS_RND "档位开关品质因子";
CM_ SG_ 779 GW_TCM_Counter_RND "档位开关生命信号";
CM_ SG_ 779 GW_TCM_CRC_RND "档位开关校验位";
CM_ SG_ 779 GW_TCM_SelfCheckSt "TCM自检状态";
CM_ SG_ 842 IVI_DeliveryModeReq "交付模式激活请求";
CM_ SG_ 842 IVI_ShowCarModeReq "展车模式请求";
CM_ SG_ 1526 IVI_Year "年";
CM_ SG_ 1526 IVI_Month "月";
CM_ SG_ 1526 IVI_Data "日";
CM_ SG_ 1526 IVI_Hour "时";
CM_ SG_ 1526 IVI_Minute "分";
CM_ SG_ 1526 IVI_Second "秒";
CM_ SG_ 984 IVI_InventerLimitOdometerkm "逆变放电预留里程";
CM_ SG_ 984 IVI_FuelDetMode "燃油检测模式请求";
CM_ SG_ 984 IVI_EngineIdlingMode "发动机怠速模式请求";
CM_ SG_ 984 IVI_CarWashMode "洗车模式";
CM_ SG_ 984 IVI_CampingModeSW "露营模式开关";
CM_ SG_ 984 IVI_SpeedLimitModeSW "限速模式开关";
CM_ SG_ 984 IVI_FuelupReq "加油请求";
CM_ SG_ 984 IVI_InventerLimitOdometerkmVD "逆变放电预留里程有效性";
CM_ SG_ 984 IVI_EMSRepairModeReq "发动机保养模式请求";
CM_ SG_ 984 IVI_ForceChgModeReq "强制发电模式请求";
CM_ SG_ 984 IVI_ForceChgTargetSOCVD "强制发电目标电量有效性";
CM_ SG_ 984 IVI_SpeedLimitModeSpeed "限速模式速度";
CM_ SG_ 984 IVI_AWDModeSW "四驱模式开关";
CM_ SG_ 984 IVI_ForceChgTargetSOC "强制发电目标电量";
CM_ SG_ 984 IVI_FuelChgMode "燃油补电模式请求";
CM_ SG_ 984 IVI_FuelChgLevel "燃油补电功率等级";
CM_ SG_ 202 MCUM_CRC_CA "校验位";
CM_ SG_ 202 MCUM_RollingCounter_CA "生命信号";
CM_ SG_ 202 MCUM_WarningLevel "主电机控制器故障等级";
CM_ SG_ 202 MCUM_SelfCheckSts "主电机控制器自检状态";
CM_ SG_ 202 MCUM_DrvMotorWorkSts "主驱动电机工作状态";
CM_ SG_ 202 MCUM_PowerReduceSts "主电机降功率状态";
CM_ SG_ 202 MCUM_DrvMotorRPM "主电机转速";
CM_ SG_ 202 MCUM_ActualTorqueFB "主电机实际扭矩反馈";
CM_ SG_ 202 MCUM_HWRdcFault "主电机旋变故障";
CM_ SG_ 202 MCUM_HighVoltPowerOffReq "主电机下高压请求";
CM_ SG_ 202 MCUM_HVILSts "主电机高压互锁状态";
CM_ SG_ 202 MCUM_DragSts "主电机拖曳状态";
CM_ SG_ 202 MCUM_CtrlMode "主电机工作模式";
CM_ SG_ 202 MCUM_MILlampReq "主电机MIL灯点亮请求";
CM_ SG_ 202 MCUM_DrvMotorRPMVD "主电机转速有效性";
CM_ SG_ 202 MCUM_ActualTorqueFBVD "主电机实际扭矩反馈有效性";
CM_ SG_ 202 MCUM_MaxTorqueAllow "主电机最大允许扭矩";
CM_ SG_ 202 MCUM_MaxSpeedAllow "主电机最大允许转速";
CM_ SG_ 202 MCUM_ActiveReleaseSts "主电机主动泄放状态";
CM_ SG_ 202 MCUM_DCChargRelaySts "快充继电器状态反馈";
CM_ SG_ 202 MCUM_MinTorqueAllow "主电机最小允许扭矩";
CM_ SG_ 202 MCUM_MainWireVolt "主电机动力母线电压值";
CM_ SG_ 202 MCUM_MainWireCurr "主电机动力母线电流值";
CM_ SG_ 202 MCUM_TMS_MotSelfHeatEnSts "主电机电驱自发热使能开关状态";
CM_ SG_ 202 MCUM_TMS_MotSelfHeatLvlFb "主电机电驱自发热开启档位";
CM_ SG_ 202 MCUM_RPowerReduceSts "主右电机降功率状态";
CM_ SG_ 202 MCUM_HeatPwrAct "主电机电驱系统加热功率";
CM_ SG_ 202 MCUM_HeatPwrMax "主电机电驱系统最大允许加热功率";
CM_ SG_ 202 MCUM_HeatPwrAval "主电机可用发热功率";
CM_ SG_ 202 MCUM_RCtrlMode "主右电机工作模式";
CM_ SG_ 202 MCUM_RWarningLevel "主右电机控制器故障等级";
CM_ SG_ 202 MCUM_RSelfCheckSts "主右电机控制器自检状态";
CM_ SG_ 202 MCUM_RDrvMotorWorkSts "主右驱动电机工作状态";
CM_ SG_ 202 MCUM_RCtrlModeVD "主右电机工作模式有效性";
CM_ SG_ 202 MCUM_RHWRdcFault "主右电机旋变故障";
CM_ SG_ 202 MCUM_RDrvMotorRPMVD "主右电机转速有效性";
CM_ SG_ 202 MCUM_RActualTorqueFBVD "主右电机实际扭矩反馈有效性";
CM_ SG_ 202 MCUM_RDrvMotorRPM "主右电机转速";
CM_ SG_ 202 MCUM_RActualTorqueFB "主右电机实际扭矩反馈";
CM_ SG_ 1489 MCUM_R_MaxTorqueAllow "主右电机最大允许扭矩";
CM_ SG_ 1489 MCUM_R_MaxSpeedAllow "主右电机最大允许转速";
CM_ SG_ 1489 MCUM_R_MinTorqueAllow "主右电机最小允许扭矩";
CM_ SG_ 219 MCUS_CRC_DB "校验位";
CM_ SG_ 219 MCUS_RollingCounter_DB "生命信号";
CM_ SG_ 219 MCUS_WarningLevel "辅电机控制器故障等级";
CM_ SG_ 219 MCUS_SelfCheckSts "辅电机控制器自检状态";
CM_ SG_ 219 MCUS_DrvMotorWorkSts "辅驱动电机工作状态";
CM_ SG_ 219 MCUS_PowerReduceSts "辅电机降功率状态";
CM_ SG_ 219 MCUS_DrvMotorRPM "辅电机转速";
CM_ SG_ 219 MCUS_ActualTorqueFB "辅电机实际扭矩反馈";
CM_ SG_ 219 MCUS_HWRdcFault "辅电机旋变故障";
CM_ SG_ 219 MCUS_HighVoltPowerOffReq "辅电机下高压请求";
CM_ SG_ 219 MCUS_HVILSts "辅电机高压互锁状态";
CM_ SG_ 219 MCUS_DragSts "辅电机拖曳状态";
CM_ SG_ 219 MCUS_CtrlMode "辅电机工作模式";
CM_ SG_ 219 MCUS_MILlampReq "辅电机MIL灯点亮请求";
CM_ SG_ 219 MCUS_DrvMotorRPMVD "辅电机转速有效性";
CM_ SG_ 219 MCUS_ActualTorqueFBVD "辅电机实际扭矩反馈有效性";
CM_ SG_ 219 MCUS_MaxTorqueAllow "辅电机最大允许扭矩";
CM_ SG_ 219 MCUS_MaxSpeedAllow "辅电机最大允许转速";
CM_ SG_ 219 MCUS_ActiveReleaseSts "辅电机主动泄放状态";
CM_ SG_ 219 MCUS_MinTorqueAllow "辅电机最小允许扭矩";
CM_ SG_ 219 MCUS_MainWireVolt "辅电机动力母线电压值";
CM_ SG_ 219 MCUS_MainWireCurr "辅电机动力母线电流值";
CM_ SG_ 219 MCUS_Clutch_Pos "狗齿离合器状态";
CM_ SG_ 219 MCUS_Clutch_Fault "狗齿离合器故障";
CM_ SG_ 219 MCUS_TMS_FrMotSelfHeatEnSts "辅电机电驱自发热使能开关状态";
CM_ SG_ 219 MCUS_TMS_FrMotSelfHeatLvlFb "辅电机电驱自发热开启档位";
CM_ SG_ 219 MCUS_HeatPwrAval "辅电机可用发热功率";
CM_ SG_ 219 MCUS_Clutch_1_Pos "离合器1状态";
CM_ SG_ 219 MCUS_Clutch_2_Pos "离合器2状态";
CM_ SG_ 219 MCUS_Clutch_1_WarningLevel "离合器1故障等级";
CM_ SG_ 219 MCUS_Clutch_2_WarningLevel "离合器2故障等级";
CM_ SG_ 219 MCUS_Clutch_1_Fault "离合器1故障";
CM_ SG_ 219 MCUS_Clutch_2_Fault "离合器2故障";
CM_ SG_ 417 BMS_CRC_1A1 "校验位";
CM_ SG_ 417 BMS_RollingCounter_1A1 "生命信号";
CM_ SG_ 417 BMS_Warning_Level "BMS故障报警";
CM_ SG_ 417 BMS_SelfCheck "BMS自检状态";
CM_ SG_ 417 BMS_BattChargerSts "电池充电状态";
CM_ SG_ 417 BMS_RHighVolSts "后向高压状态";
CM_ SG_ 417 BMS_RPreChargeRelayFB "后向控制预充继电器状态反馈";
CM_ SG_ 417 BMS_RPositiveRelayFB "后向控制主正继电器状态反馈";
CM_ SG_ 417 BMS_RNegativeRelayFB "后向控制主负继电器状态反馈";
CM_ SG_ 417 BMS_RPositiveRelay_F "后向主正继电器状态错误";
CM_ SG_ 417 BMS_RNegativeRelay_F "后向主负继电器状态错误";
CM_ SG_ 417 BMS_RPreChargeFinishSts "后向预充状态";
CM_ SG_ 417 BMS_MCUMHVILSts "MCUM高压互锁状态";
CM_ SG_ 417 BMS_ACPTCHVILSts "AC-PTC高压互锁状态";
CM_ SG_ 417 BMS_PTCHVILSts "PTC高压互锁状态";
CM_ SG_ 417 BMS_CCMHVILSts "CCM高压互锁状态";
CM_ SG_ 417 BMS_CDUHVILSts "CDU高压互锁状态";
CM_ SG_ 417 BMS_DCChgHVILSts "DCChg高压互锁状态";
CM_ SG_ 417 BMS_MCUSHVILSts "MCUS高压互锁状态";
CM_ SG_ 417 BMS_HVOffSts "BMS主动下高压请求";
CM_ SG_ 417 BMS_SeriousWarning_Level "严重故障等级";
CM_ SG_ 417 BMS_DCChgRelayCloseReq "快充继电器闭合请求";
CM_ SG_ 417 BMS_DCChgRelayFB "快充继电器状态";
CM_ SG_ 417 BMS_ChgStopReason "充电停止原因";
CM_ SG_ 417 BMS_GCUHVILSts "GCU高压互锁状态";
CM_ SG_ 417 BMS_MILlampReq "电池MIL灯点亮请求";
CM_ SG_ 417 BMS_IsoRessistanceSts "动力电池绝缘状态";
CM_ SG_ 417 BMS_Integrity_Check "电池系统安全检测";
CM_ SG_ 417 BMS_BattVolt "动力电池总电压";
CM_ SG_ 417 BMS_BattCurr "动力电池总电流";
CM_ SG_ 417 BMS_BatDyn_Dchgpwr "当前允许放电功率";
CM_ SG_ 417 BMS_BatDyn_Chgpwr "当前允许回馈功率";
CM_ SG_ 417 BMS_Precharge_CoolingSts "预充电阻冷却状态";
CM_ SG_ 784 BMS_InverterPower "对内/对外放电功率";
CM_ SG_ 784 BMS_MaxChargeVolt "最大允许充电电压";
CM_ SG_ 784 BMS_MaxChargeCurr "最大允许充电电流";
CM_ SG_ 784 BMS_OBCWorkModeCtrl "OBC工作模式控制";
CM_ SG_ 784 BMS_MaxPower "充电模式允许放电功率";
CM_ SG_ 784 BMS_ChargerACInput "交流输入状态";
CM_ SG_ 784 BMS_ChargerDCInput "直流输入状态";
CM_ SG_ 784 BMS_ChargeRequest "BMS请求充电";
CM_ SG_ 784 BMS_InverterRequest "BMS请求逆变";
CM_ SG_ 784 BMS_ChargeQuantity "本次充电量";
CM_ SG_ 784 BMS_BattMaxTemp "电池包最高温度";
CM_ SG_ 784 BMS_BattMinTemp "电池包最低温度";
CM_ SG_ 784 BMS_BattSOC_Display "SOC值";
CM_ SG_ 784 BMS_Req_Cab220VInverter_Sts "室内放电插座请求开启信号";
CM_ SG_ 784 BMS_Req_Cabin220VInverter_Sts "机舱放电插座请求开启信号";
CM_ SG_ 784 BMS_RemainEnergy "剩余能量";
CM_ SG_ 784 BMS_StateOfEngeryMax "剩余能量最大值";
CM_ SG_ 784 BMS_ThermalManageRequest "BMS热管理请求";
CM_ SG_ 784 BMS_PreHeatingState "预加热状态";
CM_ SG_ 1457 BMS_SOC_Real "PACK真实SOC";
CM_ SG_ 1457 BMS_MODE_t "BMS工作模式";
CM_ SG_ 1457 BMS_VoltLoDeratLevel_NA "预欠压降功率等级";
CM_ SG_ 1457 BMS_VoltHiDeratLevel_NA "预过压降功率等级";
CM_ SG_ 1461 BMS_WkupVolt_DC12V "快充DC12输入电压";
CM_ SG_ 1461 BMS_WkupVolt_AC12V "慢充AC12输入电压";
CM_ SG_ 1461 BMS_SOC_target "目标SOC值";
CM_ SG_ 1461 BMS_CorrectSOEPer "SOE修正百分比";
CM_ SG_ 1461 BMS_SOCModifyFlag "SOC修正标志";
CM_ SG_ 1461 BMS_BMU_SoftwareVersion "BMU软件版本";
CM_ SG_ 608 EVCC_DCAC_ChgMode "充电模式";
CM_ SG_ 608 EVCC_CP_status "CP状态";
CM_ SG_ 608 EVCC_CPDutyCycleValue "CP占空比";
CM_ SG_ 608 EVCC_EVSEMaximumCurrentLimit "充电桩最大电流限制";
CM_ SG_ 608 EVCC_EVSEMaximumPowerLimit "充电桩最大功率限制";
CM_ SG_ 804 DCDC_CRC_324 "校验位";
CM_ SG_ 804 DCDC_RollingCounter_324 "生命信号";
CM_ SG_ 804 DCDC_WorkSts "DCDC工作状态";
CM_ SG_ 804 DCDC_Under_Output_Voltage "DCDC输出欠压";
CM_ SG_ 804 DCDC_Over_Output_Voltage "DCDC输出过压";
CM_ SG_ 804 DCDC_Under_Input_Voltage "DCDC输入欠压";
CM_ SG_ 804 DCDC_Over_Input_Voltage "DCDC输入过压";
CM_ SG_ 804 DCDC_Over_Input_Current "DCDC输入过流";
CM_ SG_ 804 DCDC_Real_Output_Current "DCDC实时输出电流";
CM_ SG_ 804 DCDC_Real_Output_Voltage "DCDC实时输出电压";
CM_ SG_ 804 DCDC_Real_Input_Current "DCDC实时输入电流";
CM_ SG_ 804 DCDC_Real_Input_Voltage "DCDC实时输入电压";
CM_ SG_ 804 DCDC_Derating "DCDC限功率";
CM_ SG_ 804 DCDC_Hardware_Fault_Flag "DCDC硬件故障";
CM_ SG_ 804 CDU_ACChg_HIVSts "AC高压互锁状态";
CM_ SG_ 804 CDU_OBC_OverTemp "OBC过温";
CM_ SG_ 804 CDU_SelfCheckSt "CDU自检状态";
CM_ SG_ 804 CDU_HV_HIVSts "HV高压互锁状态";
CM_ SG_ 790 OBC_CRC_316 "校验位";
CM_ SG_ 790 OBC_RollingCounter_316 "生命信号";
CM_ SG_ 790 OBC_WorkSts "充电机工作状态";
CM_ SG_ 790 OBC_StartSts "充电机启动状态";
CM_ SG_ 790 OBC_DCSts "充电机输出状态";
CM_ SG_ 790 OBC_ACChargeOutputSts "慢充唤醒输出状态";
CM_ SG_ 790 OBC_DCVolt "充电机直流电压";
CM_ SG_ 790 OBC_HardwareSts "充电机硬件故障";
CM_ SG_ 790 OBC_DCCurr "充电机直流电流";
CM_ SG_ 790 OBC_ACVolt "L1相电压上报";
CM_ SG_ 790 OBC_ACCurr "L1相电流上报";
CM_ SG_ 790 OBC_CCConnectSts "CC连接状态";
CM_ SG_ 790 OBC_CPDutyCycleFault "CP占空比异常";
CM_ SG_ 790 OBC_CPDutyCycleValue "CP占空比数值";
CM_ SG_ 790 OBC_ACMaxPower "AC侧最大允许功率";
CM_ SG_ 790 OBC_ACPowerState "输入电压状态";
CM_ SG_ 549 IBS_CRC_225 "校验位";
CM_ SG_ 549 IBS_RollingCounter_225 "生命信号";
CM_ SG_ 549 IBS_Warning_Level "IBS故障报警";
CM_ SG_ 189 GCU_CRC_BD "校验位";
CM_ SG_ 189 GCU_RollingCounter_BD "生命信号";
CM_ SG_ 189 GCU_MainWireCurr "电机母线电流";
CM_ SG_ 189 GCU_MainWireVolt "电机母线电压";
CM_ SG_ 189 GCU_SystemWarning "电机系统故障";
CM_ SG_ 189 GCU_MILlampReq "电机MIL灯点亮请求";
CM_ SG_ 189 GCU_MoterTemp "电机温度";
CM_ SG_ 189 GCU_Temp "电机控制器温度";
CM_ SG_ 189 GCU_SelfCheck "电机自检状态";
CM_ SG_ 189 GCU_Warning_Level "电机故障等级";
CM_ SG_ 189 GCU_HVILSts "电机互锁状态";
CM_ SG_ 189 GCU__PowerReduceSts "电机降功率状态";
CM_ SG_ 189 GCU_ActualMotorRPM_VD "电机转速有效性";
CM_ SG_ 189 GCU_ActualMotorTorque_VD "电机实际扭矩有效性";
CM_ SG_ 189 GCU_ActualMotorTorque "电机实际扭矩";
CM_ SG_ 189 GCU_MaxTorque "电机可用最大扭矩";
CM_ SG_ 189 GCU_EngineFuelInhibitReq "喷油抑制请求标志位";
CM_ SG_ 189 GCU_ActiveReleaseFB "GCU主动泄放标志";
CM_ SG_ 189 GCU_MAXPower "电机最大可用功率";
CM_ SG_ 189 GCU_TransientPower "电机瞬时功率";
CM_ SG_ 189 GCU_HVOffReq "电机下高压请求";
CM_ SG_ 189 GCU_ControlMode "电机工作模式";
CM_ SG_ 189 GCU_Operating_Mode "电机工作状态";
CM_ SG_ 189 GCU_ActualMotorRPM "电机转速";
CM_ SG_ 189 GCU_EngineCylinderDeactivationSt "发动机停缸状态";
CM_ SG_ 705 GCU_SWVersionC "软件版本号(小版本)";
CM_ SG_ 705 GCU_SWVersionB "软件版本号(重要功能)";
CM_ SG_ 705 GCU_SWVersionA "软件版本号(大版本)";
CM_ SG_ 190 ECM_CRC_BE "校验位";
CM_ SG_ 190 ECM_RollingCounter_BE "生命信号";
CM_ SG_ 190 ECM_EngineSts "发动机运行状态";
CM_ SG_ 190 ECM_FaultLevel "发动机故障等级";
CM_ SG_ 190 ECM_ActualEngineTorqueValid "发动机扭矩有效性";
CM_ SG_ 190 ECM_EngineTorqueLoss "发动机损失扭矩";
CM_ SG_ 190 ECM_ActualEngineTorque "发动机实际扭矩";
CM_ SG_ 190 ECM_EngineTorqueMax "发动机最大扭矩";
CM_ SG_ 190 ECM_EngineTorqueMin "发动机最小扭矩";
CM_ SG_ 190 ECM_EngineSpeed "发动机转速";
CM_ SG_ 190 ECM_EngineSpeedValid "发动机转速有效性";
CM_ SG_ 190 ECM_EngineStopAllow "发动机允许停机";
CM_ SG_ 190 ECM_EngineOilPressureLow "机油压力低";
CM_ SG_ 190 ECM_EngineFuleCutoffSts "断油状态";
CM_ SG_ 190 ECM_EngineStartedCompleted "发动机启动标志";
CM_ SG_ 190 ECM_CatalystWarmUpSts "催化器加热状态";
CM_ SG_ 190 ECM_CatalystWarmUpReq "催化器加热请求";
CM_ SG_ 190 ECM_IdleTargetSpeed "目标怠速转速";
CM_ SG_ 190 ECM_IdleActive "怠速状态";
CM_ SG_ 190 ECM_EngineStartReq "发动机启动请求";
CM_ SG_ 190 ECM_EngineStopInhibit "发动机禁止停机信息";
CM_ SG_ 190 ECM_GPFRegenlamp "GPF回收指示灯";
CM_ SG_ 190 ECM_EngineCoolantTemp "发动机冷却液温度";
CM_ SG_ 190 ECM_EngineCoolantTempValid "冷却液温度有效性";
CM_ SG_ 190 ECM_FVVSts "FVV阀状态";
CM_ SG_ 190 ECM_learningReq "下线学习请求";
CM_ SG_ 190 ECM_EngineIdleStateRequest "EVDP诊断请求";
CM_ SG_ 190 ECM_EngineDFCOConditionRequest "诊断请求2";
CM_ SG_ 190 ECM_GPFRegenReq "GPF再生请求";
CM_ SG_ 190 ECM_SVSLampRequest "SVS lamp";
CM_ SG_ 190 ECM_TankPressure "油箱压力";
CM_ SG_ 190 ECM_TankPressureValid "油箱压力有效性";
CM_ SG_ 190 ECM_MilLampRequest "MIL Lamp";
CM_ SG_ 190 ECM_ToothlearningSucValid "齿讯学习成功标记位";
CM_ SG_ 190 ECM_FuelCloseLoopSts "发动机燃油闭环状态";
CM_ SG_ 190 ECM_RestrictorOpenValue "节气门开度";
CM_ SG_ 190 ECM_FuelLevelSensorValid "油量传感器有效性";
CM_ SG_ 190 ECM_FuelLevel "燃油剩余百分比";
CM_ SG_ 190 ECM_SelfCheckSt "ECM自检状态";
CM_ SG_ 190 ECM_PCVPipeDiagReq "PCV管路脱落诊断请求";
CM_ SG_ 190 ECM_CalculatedLoad "计算负荷";
CM_ SG_ 190 ECM_ClearingSparkcarbonedRequest "发动机火花塞清碳需求";
CM_ SG_ 190 ECM_AirPressure "大气压力";
CM_ SG_ 190 ECM_FanSts "冷却风扇等级";
CM_ SG_ 327 ECM_FuelConsumption "瞬时油耗";
CM_ SG_ 328 ECM_SWVersionC "软件版本号(小版本)";
CM_ SG_ 328 ECM_SWVersionB "软件版本号(重要功能)";
CM_ SG_ 328 ECM_SWVersionA "软件版本号(大版本)";
CM_ SG_ 328 ECM_Total_fuel_consumed "增程器累计总油耗";
CM_ SG_ 1516 ECM_EngineWorktime "发动机工作时间";
CM_ SG_ 187 VCU_CRC_BB "校验位";
CM_ SG_ 187 VCU_RollingCounter_BB "生命信号";
CM_ SG_ 187 VCU_GCURequestTorque "电机目标扭矩";
CM_ SG_ 187 VCU_PowerReducetSts "充电降功率状态";
CM_ SG_ 187 VCU_GCUAassistFB "电机助力允许标志";
CM_ SG_ 187 VCU_GCUActiveReleaseCmd "主动泄放指令";
CM_ SG_ 187 VCU_PowerOverSts "整车超功率标记位";
CM_ SG_ 187 VCU_GCURequesSpeed "电机目标转速";
CM_ SG_ 187 VCU_GCUControlMode "电机扭矩/转速选择";
CM_ SG_ 187 VCU_RoughRoadDetectionFlag "颠簸路切换四驱标志";
CM_ SG_ 187 VCU_MotChargePower "发电机充电功率";
CM_ SG_ 187 VCU_APS1Position "APS1油门信号电压百分比";
CM_ SG_ 187 VCU_EngineStartReq "发动机启动请求";
CM_ SG_ 187 VCU_EngineFuelInhibitReq "喷油抑制请求";
CM_ SG_ 187 VCU_EngineOffRequest "发动机停机请求";
CM_ SG_ 187 VCU_STorqueReqValid "发动机目标慢扭有效性";
CM_ SG_ 187 VCU_STorqueReq "发动机目标慢扭";
CM_ SG_ 187 VCU_FTorqueSwFb "快扭切换标识";
CM_ SG_ 187 VCU_FVVOpenReq "FVV阀开启请求";
CM_ SG_ 187 VCU_WarmUpCycleIndicator "发动机暖机循环";
CM_ SG_ 187 VCU_EngineResetSts "发动机重启标记";
CM_ SG_ 187 VCU_EngineSts "发动机工作状态";
CM_ SG_ 187 VCU_FTorqueReq "发动机目标快扭";
CM_ SG_ 187 VCU_FTorqueReqValid "发动机目标快扭有效性";
CM_ SG_ 187 VCU_EngineIdleReq "发动机怠速请求";
CM_ SG_ 187 VCU_REsystemSts "增程系统状态";
CM_ SG_ 187 VCU_REsystemFaultSts "增程系统故障状态";
CM_ SG_ 187 VCU_APS2Position "APS2油门信号电压百分比";
CM_ SG_ 187 VCU_EngineRunAllowFlg "允许发动机运行标志";
CM_ SG_ 187 VCU_EngineIdleSpeed "发动机怠速转速标志位";
CM_ SG_ 187 VCU_EngineFuleCutoffReq "碰撞断油请求";
CM_ SG_ 187 VCU_MCUSClutchPosition "离合器位置指令";
CM_ SG_ 187 VCU_MGCUWorkMode "工作模式状态";
CM_ SG_ 187 VCU_REChgTarget "增程目标发电量";
CM_ SG_ 187 VCU_MotStartStopPowerUP "发电机启停功率上限";
CM_ SG_ 187 VCU_MotStartStopPowerLOW "发电机启停功率下限";
CM_ SG_ 187 VCU_GCURequesSpeed_MGCU "电机目标转速_MGCU";
CM_ SG_ 187 VCU_DynamicChgPwr "动态发电补偿功率";
CM_ SG_ 187 VCU_ForceChgPwr "强制发电补偿功率";
CM_ SG_ 187 VCU_REStartType "增程启动类型";
CM_ SG_ 187 VCU_Clutch1Position "离合器1位置指令";
CM_ SG_ 187 VCU_Clutch2Position "离合器2位置指令";
CM_ SG_ 187 VCU_Clutch_1_RequesSpeed "离合器1目标转速";
CM_ SG_ 187 VCU_Clutch_2_RequesSpeed "离合器2目标转速";
CM_ SG_ 187 VCU_EVSingleAllow_PHEV "混动纯电单电机模式允许";
CM_ SG_ 187 VCU_EVDualAllow_PHEV "混动纯电双电机模式允许";
CM_ SG_ 187 VCU_REAllow_PHEV "混动增程模式允许";
CM_ SG_ 187 VCU_HEVAllow_PHEV "混动并联模式允许";
CM_ SG_ 187 VCU_WorkMode_PHEV "混动工作模式";
CM_ SG_ 187 VCU_WorkModeReq_PHEV "混动工作模式请求";
CM_ SG_ 187 VCU_Clutch_1_RequesSpeedValid "离合器1目标转速有效性";
CM_ SG_ 187 VCU_Clutch_2_RequesSpeedValid "离合器2目标转速有效性";
CM_ SG_ 187 VCU_FuelChgModeSts "燃油补电模式状态";
CM_ SG_ 187 VCU_FuelChgModeMsg "燃油补电模式提示信息";
CM_ SG_ 187 VCU_EngPreStartFlg "发动机预启动标志位";
CM_ SG_ 222 VCU_BrkPedOpen "制动踏板常开信号状态";
CM_ SG_ 222 VCU_BrkPedClose "制动踏板常闭信号状态";
CM_ SG_ 222 VCU_ColumnShiftP "P档硬线信号状态";
CM_ SG_ 222 VCU_VehiCrashSts "碰撞状态";
CM_ SG_ 222 VCU_SleepSatisfiedSts "休眠允许状态(VCU)";
CM_ SG_ 222 VCU_VehiHvCmd "高压启动命令";
CM_ SG_ 222 VCU_GearQuitAps "操作挡杆退出APS指令";
CM_ SG_ 222 VCU_REOverChgPwrFlag "增程超功率标志位";
CM_ SG_ 222 VCU_VehiAccnFilt "驱动加速度(内部计算)";
CM_ SG_ 222 VCU_HvOffSts "高压下电状态";
CM_ SG_ 222 VCU_ElecPwrBalanceReq "电平衡积分满足标志位";
CM_ SG_ 222 VCU_CDU_RecvTr "DCDC报文接收标志位";
CM_ SG_ 222 VCU_BMS_RecvTr "BMS报文接收标志位";
CM_ SG_ 222 VCU_IVI_RecvTr "IVI报文接收标志位";
CM_ SG_ 222 VCU_WheelMaxDrvTrq "最大轮端驱动扭矩限制值";
CM_ SG_ 222 VCU_WheelMaxRecTrq "最大轮端回收扭矩限制值";
CM_ SG_ 222 VCU_GCU_RecvTr "GCU报文接收标志位";
CM_ SG_ 222 VCU_TCM_RecvTr "TCM报文接收标志位";
CM_ SG_ 222 VCU_PTC_RecvTr "PTC报文接收标志位";
CM_ SG_ 222 VCU_LossFctorFlgFL "左前车辆打滑状态判断标志位";
CM_ SG_ 222 VCU_LowBattVolt "电源电压值";
CM_ SG_ 222 VCU_HighPerforDisable "动力优先退出状态";
CM_ SG_ 222 VCU_AccPedHSigVolt "加速踏板信号(高)电压值";
CM_ SG_ 222 VCU_LossFctorFlgFR "右前车辆打滑状态判断标志位";
CM_ SG_ 222 VCU_AccPedLSigVolt "加速踏板信号(低)电压值";
CM_ SG_ 222 VCU_LossFctorFlgRL "左后车辆打滑状态判断标志位";
CM_ SG_ 222 VCU_AccPedHPwrVolt "加速踏板电源(高)电压值";
CM_ SG_ 222 VCU_LossFctorFlgRR "右后车辆打滑状态判断标志位";
CM_ SG_ 222 VCU_AccPedLPwrVolt "加速踏板电源(低)电压值";
CM_ SG_ 222 VCU_PreReqChgPwr "整车回收功率";
CM_ SG_ 222 VCU_VehPwrChageLimit "整车充电功率限制";
CM_ SG_ 222 VCU_FastPwrRequest "BMS快速降扭请求扭矩";
CM_ SG_ 222 VCU_On2KL15_Volt "ON2A硬线电压";
CM_ SG_ 222 VCU_ClutchWrkModDebug "离合器内部工作模式";
CM_ SG_ 222 VCU_WheelPwrOvrLimitflgRE "增程配置超功率标志位";
CM_ SG_ 222 VCU_HighPerforSwtFlg "动力优先退出功率切换标志";
CM_ SG_ 222 VCU_VehiPowrConsumption "电平衡积分";
CM_ SG_ 222 VCU_MDrvFilterTrqRange "主电机过零扭矩状态";
CM_ SG_ 222 VCU_MRDrvControlMode "主（右）电机转速扭矩控制选择位";
CM_ SG_ 222 VCU_MRDrvControlModeVD "主（右）电机转速扭矩控制选择位有效性";
CM_ SG_ 222 VCU_VehicleDirectMR "车辆方向主轴右电机";
CM_ SG_ 222 VCU_VehicleDirectMRVD "车辆方向有效性主轴右电机";
CM_ SG_ 222 VCU_MRDrvRequestTorque "主（右）电机扭矩控制值";
CM_ SG_ 222 VCU_MRDrvRequesSpeed "主（右）电机转速控制";
CM_ SG_ 222 VCU_MCUMRMaxDischargePower "主（右）电机最大允许放电功率";
CM_ SG_ 222 VCU_MCUMRMaxPosDampgTrq "主驱（右）最大允许抑抖补偿正扭";
CM_ SG_ 222 VCU_MRDrvRequestTorqueVD "主（右）电机扭矩控制值有效性";
CM_ SG_ 222 VCU_MCUMRMaxChargePower "主（右）电机最大允许充电功率";
CM_ SG_ 222 VCU_MCUMRMaxNegDampgTrq "主驱（右）最大允许抑抖补偿负扭";
CM_ SG_ 222 VCU_MRDrvRequesSpeedVD "主（右）电机转速控制有效性";
CM_ SG_ 222 VCU_MCUMRDampgLmtFactor "主（右）驱抑抖限制系数";
CM_ SG_ 222 VCU_SuppressJitterMCUMRRequest "关闭主（右）电机抑制抖动";
CM_ SG_ 857 VCU_EolCfg_ESC "下线配置(ESC)";
CM_ SG_ 857 VCU_EolCfg_EPB "下线配置(EPB)";
CM_ SG_ 857 VCU_EolCfg_AEB "下线配置(AEB)";
CM_ SG_ 857 VCU_EolCfg_InverterFunc "下线配置(逆变放电)";
CM_ SG_ 857 VCU_EolCfg_APS "下线配置(APS)";
CM_ SG_ 857 VCU_EolCfg_VehiModels "下线配置(车辆型号)";
CM_ SG_ 857 VCU_EolCfg_SpdLmtVal "下线配置(限速设置)";
CM_ SG_ 857 VCU_EolCfg_WheelType "下线配置(轮胎类型)";
CM_ SG_ 857 VCU_EolCfg_Curise "下线配置(巡航)";
CM_ SG_ 857 VCU_REStartReq "启动请求";
CM_ SG_ 857 VCU_REStopReq "停机请求";
CM_ SG_ 857 VCU_EolCfg_VehiType "下线配置(车辆类型)";
CM_ SG_ 857 VCU_EolCfg_MotPwr "下线配置(电机类型)";
CM_ SG_ 857 VCU_Vehicle_NVHPwrLimitVal "NVH限制值";
CM_ SG_ 857 VCU_EolCfg_MotDrvStructure "下线配置(驱动结构)";
CM_ SG_ 857 VCU_WLTCModeFlag "WLTC不满足标志位";
CM_ SG_ 857 VCU_EolCfg_RudderDir "左右舵配置";
CM_ SG_ 857 VCU_EolCfg_DCChgRelayPos "快充继电器位置";
CM_ SG_ 857 VCU_EolCfg_FPTCIL "前PTC互锁检测";
CM_ SG_ 857 VCU_PWakeupSt "P档唤醒状态";
CM_ SG_ 857 VCU_SpdLimitReason "VCU限速原因";
CM_ SG_ 857 BSW_VertifySts "BSW密钥校验状态";
CM_ SG_ 857 VCU_AbResetlnitFinish "异常复位完成标志位";
CM_ SG_ 857 VCU_AbResetFlag "异常复位标志位";
CM_ SG_ 857 VCU_AbStartupFlag "异常复位存在标志位";
CM_ SG_ 857 VCU_InterAllowEngStart "VCU运行发动机启动";
CM_ SG_ 857 VCU_EngineOff_Flag "增程停机标志位";
CM_ SG_ 857 VCU_EngineStopAllow "增程允许停机";
CM_ SG_ 857 VCU_EmergencyStopReq "碰撞停机请求";
CM_ SG_ 857 VCU_EngineAllowStop "发动机停机允许";
CM_ SG_ 857 VCU_REVehiWheelTrqReq "增程整车需求扭矩";
CM_ SG_ 857 VCU_REHighPerformVehiPwr "动力优先目标需求功率";
CM_ SG_ 857 VCU_REPwrDampingFactor "增程叠加功率衰减系数";
CM_ SG_ 857 VCU_REDrvTarPwrFit "增程叠加功率";
CM_ SG_ 857 VCU_AdditionalPwrVal "整车附件功率";
CM_ SG_ 857 VCU_VehichRealPwDown "增程功率及停机功率";
CM_ SG_ 857 VCU_IMMOStsResult "防盗功能主状态机结果";
CM_ SG_ 857 VCU_IMMOStateMachine "防盗功能主状态机状态值";
CM_ SG_ 857 VCU_ShowCarModeNvmResult "体验模式NVM回读失败标志位";
CM_ SG_ 857 VCU_DeliveryModeNvmData "交付模式NVM回读失败标志位";
CM_ SG_ 857 VCU_AccPedFaultLvNvmResult "加速踏板故障等级NVM回读失败标志位";
CM_ SG_ 857 VCU_VehicleConfigNvmResult "下线配置NVM回读失败标志位";
CM_ SG_ 857 VCU_EngRunTimeNvmResult "发动机启动时间NVM回读失败标志位";
CM_ SG_ 857 VCU_IMMOKeyWriteCnt "秘钥注入次数";
CM_ SG_ 867 TMS_RollingCounter_363 "生命信号";
CM_ SG_ 867 TMS_AC_Command "压缩机开启指令";
CM_ SG_ 867 TMS_PTCHeatingReq "PTC_AC加热开启请求";
CM_ SG_ 867 TMS_PTCPowerSet "PTC功率设定";
CM_ SG_ 867 TMS_OutsideTempVD "室外温度有效性";
CM_ SG_ 867 TMS_OutsideTemp_Corrected "室外温度校正值";
CM_ SG_ 1534 TMS_MilLampReq "MIL灯点亮请求";
CM_ SG_ 1535 TMS_VCU_MotSelfHeatEnReq "整车电驱自发热使能开关";
CM_ SG_ 1535 TMS_VCU_MotSelfHeatLvlReq "整车电驱自发热档位需求";
CM_ SG_ 866 TMS_RAPTC_ModOprtgStsFrt "后APTC工作状态";
CM_ SG_ 866 TMS_RAPTC_MsrdPwrFrt "后APTC功率";
CM_ SG_ 866 TMS_RAPTC_ModOpEnblCmd "后APTC开启使能";
CM_ SG_ 874 CCM_RollingCounter_36A "生命信号";
CM_ SG_ 874 CCM_BaseState "基本状态位";
CM_ SG_ 874 CCM_Power "压缩机功率";
CM_ SG_ 874 CCM_APTC_BscSts "APTC状态";
CM_ SG_ 874 CCM_APTC_Power "APTC功率";
CM_ SG_ 871 PTC_RollingCounter_367 "生命信号";
CM_ SG_ 871 PTC_BscSts "PTC状态";
CM_ SG_ 871 PTC_Fault "PTC故障（所有错误）";
CM_ SG_ 871 PTC_Power "PTC功率";
CM_ SG_ 871 PTC_HV_interlock_faultSt "PTC高压互锁故障状态";
CM_ SG_ 1536 VCU_McuPwr12V_OV "MCU12V电源电压过压";
CM_ SG_ 1536 VCU_McuPwr12V_UV "MCU12V电源电压欠压";
CM_ SG_ 1536 VCU_DcChgPwr_OV "快充唤醒源电压过压";
CM_ SG_ 1536 VCU_DcChgPwr_UV "快充唤醒源电压欠压";
CM_ SG_ 1536 VCU_AcChgPwr_OV "慢充唤醒源电压过压";
CM_ SG_ 1536 VCU_AcChgPwr_UV "慢充唤醒源电压欠压";
CM_ SG_ 1536 VCU_DCDC_FAULT "DCDC状态报警";
CM_ SG_ 1536 VCU_BrakeSigFault "制动踏板故障";
CM_ SG_ 1536 VCU_AccPedHPwr_UV "加速踏板高电源电压低于阈值";
CM_ SG_ 1536 VCU_AccPedHPwr_OV "加速踏板高电源电压高于阈值";
CM_ SG_ 1536 VCU_AccPedLPwr_UV "加速踏板低电源电压低于阈值";
CM_ SG_ 1536 VCU_AccPedLPwr_OV "加速踏板低电源电压高于阈值";
CM_ SG_ 1536 VCU_AccPedHSig_STB "加速踏板高信号短路到电源";
CM_ SG_ 1536 VCU_AccPedHSig_OV "加速踏板高信号电压高于阈值";
CM_ SG_ 1536 VCU_AccPedHSig_UV "加速踏板高信号电压低于阈值";
CM_ SG_ 1536 VCU_AccPedHSig_STGorCO "加速踏板高信号短路到地或开路";
CM_ SG_ 1536 VCU_AccPedLSig_STB "加速踏板低信号短路到电源";
CM_ SG_ 1536 VCU_AccPedLSig_OV "加速踏板低信号电压高于阈值";
CM_ SG_ 1536 VCU_AccPedLSig_UV "加速踏板低信号电压低于阈值";
CM_ SG_ 1536 VCU_AccPedLSig_STGorCO "加速踏板低信号短路到地或开路";
CM_ SG_ 1536 VCU_AccPedSigSyncFault "加速踏板高低信号同步错误";
CM_ SG_ 1536 VCU_CcmOutHvil_STBorCO "CCM外端高压电缆检测信号短路到电源或开路";
CM_ SG_ 1536 VCU_CcmOutHvil_STG "CCM外端高压电缆检测信号短路到地";
CM_ SG_ 1536 VCU_CcmOutHvil_SigInvalid "CCM外端高压电缆检测信号异常";
CM_ SG_ 1536 VCU_HVIL_FAULT "行车高压互锁故障";
CM_ SG_ 1536 VCU_ACHVIL_FAULT "慢充高压互锁故障";
CM_ SG_ 1536 VCU_DCHVIL_FAULT "快充高压互锁故障";
CM_ SG_ 1536 VCU_HVIL_STS_ALARM "高压互锁状态报警";
CM_ SG_ 1536 VCU_MD_HV_Start_Failure_HVIL "主驱高压启动失败-高压互锁";
CM_ SG_ 1536 VCU_MD_HV_Start_Failure_MCUFault "主驱高压启动失败-MCU故障";
CM_ SG_ 1536 VCU_MD_HV_Start_Failure_BMSFault "主驱高压启动失败-BMS故障";
CM_ SG_ 1536 VCU_MD_HV_Start_Failure_OtherFau "主驱高压启动失败-其他故障";
CM_ SG_ 1536 VCU_DcChagerTempP_OT "快充充电口正极温度过温";
CM_ SG_ 1536 VCU_DcChagerTempN_OT "快充充电口负极温度过温";
CM_ SG_ 1536 VCU_AcChagerTempP_OT "慢充充电口正极温度过温";
CM_ SG_ 1536 VCU_EngineStartFailure "发动机启动失败";
CM_ SG_ 1536 VCU_EnergyRecoveryProhibit "ESC故障导致能量回收禁用";
CM_ SG_ 1536 VIU_GW_MissMsg "VCU_GW通信丢失";
CM_ SG_ 1536 VIU_GW_RollCntErr "VCU_GW生命信号错误";
CM_ SG_ 1536 VIU_GW_ChksumErr "VCU_GW校验信号错误";
CM_ SG_ 1536 VCU_AcChagerTempN_OT "慢充充电口负极温度过温";
CM_ SG_ 1536 VCU_MCUM_SissMsgHigh "MCUS通信严重丢失";
CM_ SG_ 1536 VCU_AuthenticationKey_Not_Write "VCU_IMMO密钥未写入";
CM_ SG_ 1536 VCU_BCM_Authentication_Fail_or_T "VCU_与BCM认证失败或超时";
CM_ SG_ 1536 VCU_BrakeSysFault "制动系统故障";
CM_ SG_ 1536 VCU_PGearLeverFault "P档开关故障";
CM_ SG_ 1536 VCU_PGearLeverCounterError "P档生命信号错误";
CM_ SG_ 1536 VCU_PGearLeverChecksumError "P档开关校验错误";
CM_ SG_ 1536 VCU_GearChangeLeverFault "档位开关故障";
CM_ SG_ 1536 VCU_GearChangeLeverError "档位开关生命信号错误";
CM_ SG_ 1536 VCU_GearChangeLeverChecksumError "档位开关校验错误";
CM_ SG_ 1536 VCU_CalibrationDataCrc_ERR "标定数据CRC校验失败";
CM_ SG_ 1536 VCU_CalibrationAppCrc_ERR "标定数据与APP不匹配";
CM_ SG_ 1536 VCU_CalibrationRead_ERR "标定数据读取失败";
CM_ SG_ 1536 VCU_MCUM_MissMsgHigh "MCUM通信严重丢失";
CM_ SG_ 1536 VCU_CalibrationVerifyErr "标定量版本校验错误";
CM_ SG_ 1536 VCU_McuSeriousFaultyFor4WD "驱动电机严重故障";
CM_ SG_ 1536 VCU_McuFaultyFor4WDType1 "驱动电机故障1";
CM_ SG_ 1536 VCU_McuFaultyFor4WDType2 "驱动电机故障2";
CM_ SG_ 1536 VCU_CrashFaulty "碰撞故障";
CM_ SG_ 1536 VCU_MCUS_PrivateCANMissMsg "VCU_MCUS私CAN通讯丢失";
CM_ SG_ 1536 VCU_MCUS_PrivateCANRollCntErr "VCU_MCUS私CAN生命信号错误";
CM_ SG_ 1536 VCU_MCUS_PrivateCANChksumErr "VCU_MCUS私CAN校验信号错误";
CM_ SG_ 1536 VCU_DCDC12VLowFault "蓄电池电压低故障";
CM_ SG_ 1536 VCU_ECMRequestMIL "ECM请求MIL灯";
CM_ SG_ 1536 VCU_GCURequestMIL "GCU请求MIL灯";
CM_ SG_ 1536 VCU_MCURequestMIL "MCU请求MIL灯";
CM_ SG_ 1536 VCU_BMSRequestMIL "BMS请求MIL灯";
CM_ SG_ 1536 VCU_IBCRequestMIL "IBC请求MIL灯";
CM_ SG_ 1536 VCU_TMSRequestMIL "TMS请求MIL灯";
CM_ SG_ 1536 VCU_VCURequestMIL "VCU请求MIL灯";
CM_ SG_ 1536 VCU_CCANFD_Busoff "C_CANFD总线关闭（底盘）";
CM_ SG_ 1536 VCU_PCANFD_Busoff "P_CANFD总线关闭（动力）";
CM_ SG_ 1536 VCU_MCUS_MissMsg "VCU_MCUS通信丢失";
CM_ SG_ 1536 VCU_MCUS_RollCntErr "VCU_MCUS生命信号错误";
CM_ SG_ 1536 VCU_MCUS_ChksumErr "VCU_MCUS校验信号错误";
CM_ SG_ 1536 VCU_MCUM_MissMsg "VCU_MCUM通信丢失";
CM_ SG_ 1536 VCU_MCUM_RollCntErr "VCU_MCUM生命信号错误";
CM_ SG_ 1536 VCU_MCUM_ChksumErr "VCU_MCUM校验信号错误";
CM_ SG_ 1536 VCU_BMS_MissMsg "VCU_BMS通信丢失";
CM_ SG_ 1536 VCU_BMS_RollCntErr "VCU_BMS生命信号错误";
CM_ SG_ 1536 VCU_BMS_ChksumErr "VCU_BMS校验信号错误";
CM_ SG_ 1536 VCU_DCDC_MissMsg "VCU_DCDC通信丢失";
CM_ SG_ 1536 VCU_DCDC_RollCntErr "VCU_DCDC生命信号错误";
CM_ SG_ 1536 VCU_DCDC_ChksumErr "VCU_DCDC校验信号错误";
CM_ SG_ 1536 VCU_OBC_MissMsg "VCU_OBC通信丢失";
CM_ SG_ 1536 VCU_OBC_RollCntErr "VCU_OBC生命信号错误";
CM_ SG_ 1536 VCU_OBC_ChksumErr "VCU_OBC校验信号错误";
CM_ SG_ 1536 VCU_ACU_MissMsg "VCU_ACU通信丢失";
CM_ SG_ 1536 VCU_ACU_RollCntErr "VCU_ACU生命信号错误";
CM_ SG_ 1536 VCU_ACU_ChksumErr "VCU_ACU校验信号错误";
CM_ SG_ 1536 VCU_IBC_MissMsg "VCU_IBC通信丢失";
CM_ SG_ 1536 VCU_IBC_RollCntErr "VCU_IBC生命信号错误";
CM_ SG_ 1536 VCU_IBC_ChksumErr "VCU_IBC校验信号错误";
CM_ SG_ 1536 VCU_EPS_MissMsg "VCU_EPS通信丢失";
CM_ SG_ 1536 VCU_EPS_RollCntErr "VCU_EPS生命信号错误";
CM_ SG_ 1536 VCU_EPS_ChksumErr "VCU_EPS校验信号错误";
CM_ SG_ 1536 VCU_BCM_MissMsg "VCU_BCM通信丢失";
CM_ SG_ 1536 VCU_BCM_RollCntErr "VCU_BCM生命信号错误";
CM_ SG_ 1536 VCU_BCM_ChksumErr "VCU_BCM校验信号错误";
CM_ SG_ 1536 VCU_ICU_MissMsg "VCU_ICU通信丢失";
CM_ SG_ 1536 VCU_ICU_RollCntErr "VCU_ICU生命信号错误";
CM_ SG_ 1536 VCU_ICU_ChksumErr "VCU_ICU校验信号错误";
CM_ SG_ 1536 VCU_IVI_MissMsg "VCU_IVI通信丢失";
CM_ SG_ 1536 VCU_IVI_RollCntErr "VCU_IVI生命信号错误";
CM_ SG_ 1536 VCU_IVI_ChksumErr "VCU_IVI校验信号错误";
CM_ SG_ 1536 VCU_ECM_MissMsg "VCU_ECM通讯丢失";
CM_ SG_ 1536 VCU_ECM_ChksumErr "VCU_ECM校验信号错误";
CM_ SG_ 1536 VCU_ECM_RollCntErr "VCU_ECM生命信号错误";
CM_ SG_ 1536 VCU_GCU_MissMsg "VCU_GCU通讯丢失";
CM_ SG_ 1536 VCU_GCU_ChksumErr "VCU_GCU校验信号错误";
CM_ SG_ 1536 VCU_GCU_RollCntErr "VCU_GCU生命信号错误";
CM_ SG_ 1536 VCU_ACC_MissMsg "VCU_ACC通信丢失";
CM_ SG_ 1536 VCU_ACC_RollCntErr "VCU_ACC生命信号错误";
CM_ SG_ 1536 VCU_ACC_ChksumErr "VCU_ACC校验信号错误";
CM_ SG_ 1536 VCU_APS_MissMsg "VCU_APS通信丢失";
CM_ SG_ 1536 VCU_APS_RollCntErr "VCU_APS生命信号错误";
CM_ SG_ 1536 VCU_APS_ChksumErr "VCU_APS校验信号错误";
CM_ SG_ 1536 VCU_ParkingSignal_Fault "P档信号一致性校验故障";
CM_ SG_ 1536 VCU_FSC_Loss_Communication "VCU_FSC通讯丢失";
CM_ SG_ 1536 VCU_FSC_Counter_Error "VCU_FSC生命信号错误";
CM_ SG_ 1536 VCU_FSC_Checksum_Error "VCU_FSC校验信号错误对应报文";
CM_ SG_ 1536 VCU_LMC_MissMSg "VCU_LMC通讯丢失";
CM_ SG_ 1536 VCU_LMC_ChksumErr "VCU_LMC校验信号错误";
CM_ SG_ 1536 VCU_LMC_RollCntErr "VCU_LMC生命信号错误";
CM_ SG_ 1536 GW_TCM_MissMsg "GW_TCM通信丢失";
CM_ SG_ 1536 GW_TCM_RollCntErr "GW_TCM生命信号错误";
CM_ SG_ 1536 GW_TCM_ChksumErr "GW_TCM校验信号错误";
CM_ SG_ 1536 VCU_IBS_LossComm "IBS通信丢失";
CM_ SG_ 1536 VCU_IBS_CounterErr "IBS生命信号错误";
CM_ SG_ 1536 VCU_IBS_ChecksumErr "IBS校验信号错误";
CM_ SG_ 1536 Dtc_IBS_FAULTHigh "IBS严重故障";
CM_ SG_ 1536 VCU_CCM_LossComm "CCM通信丢失";
CM_ SG_ 1536 VCU_CCM_CounterErr "CCM生命信号错误";
CM_ SG_ 1536 VCU_CCM_ChecksumErr "CCM校验信号错误";
CM_ SG_ 1536 VCU_PTC_LossComm "PTC通信丢失";
CM_ SG_ 1536 VCU_PTC_CounterErr "PTC生命信号错误";
CM_ SG_ 1536 VCU_PTC_ChecksumErr "PTC校验信号错误";
CM_ SG_ 1536 VCU_TMS_LossComm "TMS通信丢失";
CM_ SG_ 1536 VCU_TMS_CounterErr "TMS生命信号错误";
CM_ SG_ 1536 VCU_TMS_ChecksumErr "TMS校验信号错误";
CM_ SG_ 1536 VCU_IMU_LossComm "IMU通讯丢失";
CM_ SG_ 1536 VCU_IMU_CounterErr "IMU生命信号错误";
CM_ SG_ 1536 VCU_IMU_ChecksumErr "IMU校验信号错误";
CM_ SG_ 1536 VCU_Prvt_CAN_BUS_OFF "私CANBussOff";
CM_ SG_ 1536 VCU_IMU_Cali_CounterErr "IMU标定修正报文生命信号故障";
CM_ SG_ 1536 VCU_ASR_Fault "VCU_ASR故障";
CM_ SG_ 1536 VCU_DTC_Fault "VCU_DTC故障";
CM_ SG_ 1536 VCU_VDC_Fault "VCU_VDC故障";
CM_ SG_ 1536 VCU_ACU_Trigger_Fault "ACU非起爆碰撞故障";
CM_ SG_ 1536 VCU_DMC_Front_Motor_Input_Signal "DMC 前电机输入信号无效";
CM_ SG_ 1536 VCU_DMC_Rear_Motor_Input_Signal_ "DMC 后电机输入信号无效";
BA_DEF_ SG_  "GenSigSendType" ENUM  "OnChangeWithRepetition","OnChange","OnWrite","Cycle";
BA_DEF_ SG_  "GenSigStartValue" INT 0 0;
BA_DEF_ BO_  "GenMsgCycleTime" INT 0 0;
BA_DEF_ BO_  "GenMsgCycleTimeFast" INT 0 0;
BA_DEF_ BO_  "GenMsgNrOfRepetition" INT 0 0;
BA_DEF_ BO_  "GenMsgSendType" ENUM  "Cycle","Event";
BA_DEF_ BO_  "NmBaseAddress" INT 0 2047;
BA_DEF_ BO_  "CANFD_BRS" ENUM  "0","1";
BA_DEF_ BO_  "VFrameFormat" ENUM  "StandardCAN","ExtendedCAN","reserved","reserved","reserved","reserved","reserved","reserved","reserved","reserved","reserved","reserved","reserved","reserved","StandardCAN_FD","ExtendedCAN_FD";
BA_DEF_ BU_  "NmNode" ENUM  "Not","Yes";
BA_DEF_  "BusType" STRING ;
BA_DEF_  "NmMessageCount" INT 0 255;
BA_DEF_  "Baudrate" INT 0 1000000;
BA_DEF_  "DBName" STRING ;
BA_DEF_ SG_  "SystemSignalLongSymbol" STRING ;
BA_DEF_DEF_  "GenSigSendType" "Cycle";
BA_DEF_DEF_  "GenSigStartValue" 0;
BA_DEF_DEF_  "GenMsgCycleTime" 0;
BA_DEF_DEF_  "GenMsgCycleTimeFast" 0;
BA_DEF_DEF_  "GenMsgNrOfRepetition" 0;
BA_DEF_DEF_  "GenMsgSendType" "Cycle";
BA_DEF_DEF_  "NmBaseAddress" 1024;
BA_DEF_DEF_  "CANFD_BRS" "1";
BA_DEF_DEF_  "VFrameFormat" "StandardCAN_FD";
BA_DEF_DEF_  "NmNode" "Not";
BA_DEF_DEF_  "BusType" "CAN FD";
BA_DEF_DEF_  "NmMessageCount" 128;
BA_DEF_DEF_  "Baudrate" 500000;
BA_DEF_DEF_  "DBName" "";
BA_DEF_DEF_  "SystemSignalLongSymbol" "";
BA_ "Baudrate" 2000000;
BA_ "DBName" "P_CANFD";
BA_ "GenMsgNrOfRepetition" BO_ 484 3;
BA_ "GenMsgCycleTimeFast" BO_ 484 30;
BA_ "GenMsgSendType" BO_ 484 1;
BA_ "GenMsgNrOfRepetition" BO_ 485 3;
BA_ "GenMsgCycleTimeFast" BO_ 485 30;
BA_ "GenMsgSendType" BO_ 485 1;
BA_ "GenMsgNrOfRepetition" BO_ 486 3;
BA_ "GenMsgCycleTimeFast" BO_ 486 30;
BA_ "GenMsgSendType" BO_ 486 1;
BA_ "GenMsgCycleTime" BO_ 223 10;
BA_ "GenMsgCycleTime" BO_ 315 10;
BA_ "GenMsgCycleTime" BO_ 188 10;
BA_ "GenMsgCycleTime" BO_ 856 100;
BA_ "GenMsgCycleTime" BO_ 1300 100;
BA_ "GenMsgCycleTime" BO_ 1301 200;
BA_ "GenMsgCycleTime" BO_ 588 100;
BA_ "GenMsgCycleTime" BO_ 585 100;
BA_ "GenMsgCycleTime" BO_ 657 20;
BA_ "GenMsgCycleTime" BO_ 658 20;
BA_ "GenMsgCycleTime" BO_ 945 100;
BA_ "GenMsgCycleTime" BO_ 779 20;
BA_ "GenMsgNrOfRepetition" BO_ 842 3;
BA_ "GenMsgCycleTimeFast" BO_ 842 30;
BA_ "GenMsgSendType" BO_ 842 1;
BA_ "GenMsgCycleTime" BO_ 1526 500;
BA_ "GenMsgCycleTime" BO_ 984 200;
BA_ "GenMsgCycleTime" BO_ 202 10;
BA_ "GenMsgCycleTime" BO_ 1489 50;
BA_ "GenMsgCycleTime" BO_ 219 10;
BA_ "GenMsgCycleTime" BO_ 417 10;
BA_ "GenMsgCycleTime" BO_ 784 200;
BA_ "GenMsgCycleTime" BO_ 1457 1000;
BA_ "GenMsgCycleTime" BO_ 1461 200;
BA_ "GenMsgCycleTime" BO_ 608 100;
BA_ "GenMsgCycleTime" BO_ 804 100;
BA_ "GenMsgCycleTime" BO_ 790 200;
BA_ "GenMsgCycleTime" BO_ 549 20;
BA_ "GenMsgCycleTime" BO_ 189 10;
BA_ "GenMsgCycleTime" BO_ 705 100;
BA_ "GenMsgCycleTime" BO_ 190 10;
BA_ "GenMsgCycleTime" BO_ 327 100;
BA_ "GenMsgCycleTime" BO_ 328 1000;
BA_ "GenMsgCycleTime" BO_ 1516 1000;
BA_ "GenMsgCycleTime" BO_ 187 10;
BA_ "GenMsgCycleTime" BO_ 222 10;
BA_ "GenMsgCycleTime" BO_ 857 200;
BA_ "GenMsgCycleTime" BO_ 867 100;
BA_ "GenMsgCycleTime" BO_ 1534 200;
BA_ "GenMsgCycleTime" BO_ 1535 200;
BA_ "GenMsgCycleTime" BO_ 866 1000;
BA_ "GenMsgCycleTime" BO_ 874 100;
BA_ "GenMsgCycleTime" BO_ 871 100;
BA_ "GenMsgCycleTime" BO_ 1536 200;
BA_ "GenSigSendType" SG_ 484 BCM_VCU_Authentication_Challenge 0;
BA_ "SystemSignalLongSymbol" SG_ 484 BCM_VCU_Authentication_Challenge "BCM_VCU_Authentication_Challenge_A0";
BA_ "GenSigSendType" SG_ 484 BCM_VCU_Authentication_Chal_0000 0;
BA_ "SystemSignalLongSymbol" SG_ 484 BCM_VCU_Authentication_Chal_0000 "BCM_VCU_Authentication_Challenge_A1";
BA_ "GenSigSendType" SG_ 484 BCM_VCU_Authentication_Chal_0001 0;
BA_ "SystemSignalLongSymbol" SG_ 484 BCM_VCU_Authentication_Chal_0001 "BCM_VCU_Authentication_Challenge_A2";
BA_ "GenSigSendType" SG_ 484 BCM_VCU_Authentication_Chal_0002 0;
BA_ "SystemSignalLongSymbol" SG_ 484 BCM_VCU_Authentication_Chal_0002 "BCM_VCU_Authentication_Challenge_A3";
BA_ "GenSigSendType" SG_ 485 VCU_BCM_Authentication_MAC_A0 0;
BA_ "GenSigSendType" SG_ 485 VCU_BCM_Authentication_MAC_A1 0;
BA_ "GenSigSendType" SG_ 485 VCU_BCM_Authentication_MAC_A2 0;
BA_ "GenSigSendType" SG_ 485 VCU_BCM_Authentication_MAC_A3 0;
BA_ "GenSigSendType" SG_ 485 VCU_BCM_Authentication_MAC_A4 0;
BA_ "GenSigSendType" SG_ 485 VCU_BCM_Authentication_MAC_A5 0;
BA_ "GenSigSendType" SG_ 485 VCU_BCM_Authentication_MAC_A6 0;
BA_ "GenSigSendType" SG_ 485 VCU_BCM_Authentication_MAC_A7 0;
BA_ "GenSigSendType" SG_ 485 VCU_BCM_Authentication_MAC_A8 0;
BA_ "GenSigSendType" SG_ 485 VCU_BCM_Authentication_MAC_A9 0;
BA_ "GenSigSendType" SG_ 485 VCU_BCM_Authentication_MAC_A10 0;
BA_ "GenSigSendType" SG_ 485 VCU_BCM_Authentication_MAC_A11 0;
BA_ "GenSigSendType" SG_ 485 VCU_BCM_Authentication_MAC_A12 0;
BA_ "GenSigSendType" SG_ 485 VCU_BCM_Authentication_MAC_A13 0;
BA_ "GenSigSendType" SG_ 485 VCU_BCM_Authentication_MAC_A14 0;
BA_ "GenSigSendType" SG_ 485 VCU_BCM_Authentication_MAC_A15 0;
BA_ "GenSigSendType" SG_ 485 VCU_BCM_Authentication_Challenge 0;
BA_ "SystemSignalLongSymbol" SG_ 485 VCU_BCM_Authentication_Challenge "VCU_BCM_Authentication_Challenge_B0";
BA_ "GenSigSendType" SG_ 485 VCU_BCM_Authentication_Chal_0000 0;
BA_ "SystemSignalLongSymbol" SG_ 485 VCU_BCM_Authentication_Chal_0000 "VCU_BCM_Authentication_Challenge_B1";
BA_ "GenSigSendType" SG_ 485 VCU_BCM_Authentication_Chal_0001 0;
BA_ "SystemSignalLongSymbol" SG_ 485 VCU_BCM_Authentication_Chal_0001 "VCU_BCM_Authentication_Challenge_B2";
BA_ "GenSigSendType" SG_ 485 VCU_BCM_Authentication_Chal_0002 0;
BA_ "SystemSignalLongSymbol" SG_ 485 VCU_BCM_Authentication_Chal_0002 "VCU_BCM_Authentication_Challenge_B3";
BA_ "GenSigSendType" SG_ 486 BCM_VCU_Authentication_MAC_B0 0;
BA_ "GenSigSendType" SG_ 486 BCM_VCU_Authentication_MAC_B1 0;
BA_ "GenSigSendType" SG_ 486 BCM_VCU_Authentication_MAC_B2 0;
BA_ "GenSigSendType" SG_ 486 BCM_VCU_Authentication_MAC_B3 0;
BA_ "GenSigSendType" SG_ 486 BCM_VCU_Authentication_MAC_B4 0;
BA_ "GenSigSendType" SG_ 486 BCM_VCU_Authentication_MAC_B5 0;
BA_ "GenSigSendType" SG_ 486 BCM_VCU_Authentication_MAC_B6 0;
BA_ "GenSigSendType" SG_ 486 BCM_VCU_Authentication_MAC_B7 0;
BA_ "GenSigSendType" SG_ 486 BCM_VCU_Authentication_MAC_B8 0;
BA_ "GenSigSendType" SG_ 486 BCM_VCU_Authentication_MAC_B9 0;
BA_ "GenSigSendType" SG_ 486 BCM_VCU_Authentication_MAC_B10 0;
BA_ "GenSigSendType" SG_ 486 BCM_VCU_Authentication_MAC_B11 0;
BA_ "GenSigSendType" SG_ 486 BCM_VCU_Authentication_MAC_B12 0;
BA_ "GenSigSendType" SG_ 486 BCM_VCU_Authentication_MAC_B13 0;
BA_ "GenSigSendType" SG_ 486 BCM_VCU_Authentication_MAC_B14 0;
BA_ "GenSigSendType" SG_ 486 BCM_VCU_Authentication_MAC_B15 0;
BA_ "GenSigStartValue" SG_ 223 ICU_IMU_ACC_Roll_Rate 32768;
BA_ "GenSigStartValue" SG_ 223 ICU_IMU_ACC_Pitch_Rate 32768;
BA_ "GenSigStartValue" SG_ 223 ICU_IMU_ACC_Yaw_Rate 32768;
BA_ "GenSigStartValue" SG_ 315 VCU_GearLevelPosSts 2;
BA_ "GenSigStartValue" SG_ 315 VCU_MDrvRequestTorque 5000;
BA_ "GenSigStartValue" SG_ 315 VCU_MDrvRequesSpeed 17000;
BA_ "GenSigStartValue" SG_ 315 VCU_SDrvRequestTorque 5000;
BA_ "GenSigStartValue" SG_ 315 VCU_SDrvRequesSpeed 17000;
BA_ "GenSigStartValue" SG_ 315 VCU_MCUMDampgLmtFactor 100;
BA_ "GenSigStartValue" SG_ 315 VCU_MCUSDampgLmtFactor 100;
BA_ "GenSigStartValue" SG_ 315 VCU_MCUSMaxPosDampgTrq 50;
BA_ "GenSigStartValue" SG_ 315 VCU_MCUMMaxPosDampgTrq 50;
BA_ "GenSigStartValue" SG_ 945 GW_ZCUB_DCChgExitTemp_Pos 65;
BA_ "GenSigStartValue" SG_ 945 GW_ZCUB_DCChgExitTemp_Neg 65;
BA_ "GenSigStartValue" SG_ 945 GW_ZCUB_ACChgExitTemp_Pos 65;
BA_ "GenSigStartValue" SG_ 945 GW_ZCUB_ACChgExitTemp_Neg 65;
BA_ "GenSigStartValue" SG_ 945 GW_TBOXSOC_Altitude 1000;
BA_ "GenSigStartValue" SG_ 779 GW_TCM_STATUS_Park 1;
BA_ "GenSigStartValue" SG_ 779 GW_TCM_STATUS_RND 1;
BA_ "GenSigSendType" SG_ 842 IVI_DeliveryModeReq 0;
BA_ "GenSigSendType" SG_ 842 IVI_ShowCarModeReq 0;
BA_ "GenSigStartValue" SG_ 202 MCUM_DrvMotorRPM 17000;
BA_ "GenSigStartValue" SG_ 202 MCUM_ActualTorqueFB 5000;
BA_ "GenSigStartValue" SG_ 202 MCUM_MaxTorqueAllow 5000;
BA_ "GenSigStartValue" SG_ 202 MCUM_MaxSpeedAllow 17000;
BA_ "GenSigStartValue" SG_ 202 MCUM_MinTorqueAllow 5000;
BA_ "GenSigStartValue" SG_ 202 MCUM_MainWireCurr 10000;
BA_ "GenSigStartValue" SG_ 202 MCUM_RDrvMotorRPM 17000;
BA_ "GenSigStartValue" SG_ 202 MCUM_RActualTorqueFB 5000;
BA_ "GenSigStartValue" SG_ 1489 MCUM_R_MaxTorqueAllow 5000;
BA_ "GenSigStartValue" SG_ 1489 MCUM_R_MaxSpeedAllow 17000;
BA_ "GenSigStartValue" SG_ 1489 MCUM_R_MinTorqueAllow 5000;
BA_ "GenSigStartValue" SG_ 219 MCUS_DrvMotorRPM 17000;
BA_ "GenSigStartValue" SG_ 219 MCUS_ActualTorqueFB 5000;
BA_ "GenSigStartValue" SG_ 219 MCUS_MaxTorqueAllow 5000;
BA_ "GenSigStartValue" SG_ 219 MCUS_MaxSpeedAllow 17000;
BA_ "GenSigStartValue" SG_ 219 MCUS_MinTorqueAllow 5000;
BA_ "GenSigStartValue" SG_ 219 MCUS_MainWireCurr 10000;
BA_ "GenSigStartValue" SG_ 790 OBC_DCCurr 1000;
BA_ "GenSigStartValue" SG_ 790 OBC_ACCurr 1000;
BA_ "GenSigStartValue" SG_ 189 GCU_MainWireCurr 10000;
BA_ "GenSigStartValue" SG_ 189 GCU_MoterTemp 40;
BA_ "GenSigStartValue" SG_ 189 GCU_Temp 40;
BA_ "GenSigStartValue" SG_ 189 GCU_EngineFuelInhibitReq 1;
BA_ "SystemSignalLongSymbol" SG_ 189 GCU_EngineCylinderDeactivationSt "GCU_EngineCylinderDeactivationStatus";
BA_ "GenSigStartValue" SG_ 190 ECM_EngineTorqueLoss 200;
BA_ "GenSigStartValue" SG_ 190 ECM_ActualEngineTorque 1000;
BA_ "GenSigStartValue" SG_ 190 ECM_EngineTorqueMax 1000;
BA_ "GenSigStartValue" SG_ 190 ECM_EngineTorqueMin 1000;
BA_ "GenSigStartValue" SG_ 190 ECM_EngineCoolantTemp 40;
BA_ "GenSigStartValue" SG_ 187 VCU_GCURequestTorque 2000;
BA_ "GenSigStartValue" SG_ 187 VCU_GCURequesSpeed 8000;
BA_ "GenSigStartValue" SG_ 187 VCU_STorqueReq 1000;
BA_ "GenSigStartValue" SG_ 187 VCU_FTorqueReq 1000;
BA_ "GenSigStartValue" SG_ 222 VCU_MRDrvRequestTorque 5000;
BA_ "GenSigStartValue" SG_ 222 VCU_MRDrvRequesSpeed 17000;
BA_ "GenSigStartValue" SG_ 222 VCU_MCUMRMaxPosDampgTrq 50;
BA_ "GenSigStartValue" SG_ 222 VCU_MCUMRDampgLmtFactor 100;
BA_ "GenSigStartValue" SG_ 867 TMS_OutsideTemp_Corrected 130;
BA_ "SystemSignalLongSymbol" SG_ 1536 VCU_MD_HV_Start_Failure_OtherFau "VCU_MD_HV_Start_Failure_OtherFault";
BA_ "SystemSignalLongSymbol" SG_ 1536 VCU_BCM_Authentication_Fail_or_T "VCU_BCM_Authentication_Fail_or_Timeout";
BA_ "SystemSignalLongSymbol" SG_ 1536 VCU_DMC_Front_Motor_Input_Signal "VCU_DMC_Front_Motor_Input_Signal_Invalid";
BA_ "SystemSignalLongSymbol" SG_ 1536 VCU_DMC_Rear_Motor_Input_Signal_ "VCU_DMC_Rear_Motor_Input_Signal_Invalid";
VAL_ 223 ICU_IMU_Calibrated 2 "No_calibrated" 1 "Calibrating" 0 "Calibrated" ;
VAL_ 223 ICU_IMU_Valid 1 "Valid" 0 "Invalid" ;
VAL_ 315 VCU_Vehicle_Warning 3 "Level-3_Error(High)" 2 "Level-2_Error" 1 "Level-1_Error(Low)" 0 "No_Error" ;
VAL_ 315 VCU_VehicleSts 1 "Ready" 0 "Not_Ready" ;
VAL_ 315 VCU_GearLevelPosSts 3 "D" 2 "N" 1 "R" 0 "P" ;
VAL_ 315 VCU_GearLeverValid 1 "Invalid" 0 "Valid" ;
VAL_ 315 VCU_AccPedalValid 1 "Invalid" 0 "Valid" ;
VAL_ 315 VCU_BMSMainRelayR_Cmd 1 "Work" 0 "Not_Work" ;
VAL_ 315 VCU_BMSMainRelayF_Cmd 1 "Work" 0 "Not_Work" ;
VAL_ 315 VCU_BMSEmergencyCmd 1 "Work" 0 "Not_Work" ;
VAL_ 315 VCU_MCUMActiveReleaseCmd 1 "Active" 0 "Not_Active" ;
VAL_ 315 VCU_MCUSActiveReleaseCmd 1 "Active" 0 "Not_Active" ;
VAL_ 315 VCU_AlwACChargeInventerSts 1 "Allowed" 0 "Not_Allowed" ;
VAL_ 315 VCU_AlwDCChargeSts 1 "Allowed" 0 "Not_Allowed" ;
VAL_ 315 VCU_ChargePauseReq 1 "Request" 0 "No_Request" ;
VAL_ 315 VCU_SuppressJitterMCUSRequest 1 "Request" 0 "No_Request" ;
VAL_ 315 VCU_DCDCEnableCmd 1 "Work" 0 "Not_Work" ;
VAL_ 315 VCU_ACOffReq 3 "AC/PTC_Driver_Power_Limit" 2 "AC/PTC_Driver_off" 1 "AC/PTC_Off" 0 "No_Request" ;
VAL_ 315 VCU_VehicleDirect 1 "Backward" 0 "Forward" ;
VAL_ 315 VCU_BrakeSysFault 1 "Fault" 0 "No_Fault" ;
VAL_ 315 VCU_SuppressJitterMCUMRequest 1 "Request" 0 "No_Request" ;
VAL_ 315 VCU_MDrvControlMode 1 "Speed" 0 "Torque" ;
VAL_ 315 VCU_SVehicleSts 1 "Ready" 0 "Not_Ready" ;
VAL_ 315 VCU_VehicleHighVoltModeF 4 "启动失败" 3 "启动完成" 2 "启动" 1 "自检" 0 "下电模式_" ;
VAL_ 315 VCU_SDrvControlMode 1 "Speed" 0 "Torque" ;
VAL_ 315 VCU_ON2BRelayReq 2 "Opened" 1 "Closed" 0 "NO_Control" ;
VAL_ 315 VCU_VehPreHVPwrOffCmd 1 "Request" 0 "No_request" ;
VAL_ 315 VCU_FuelTankLockReq 3 "Not_Available" 2 "Lock" 1 "Unlock" 0 "No_Control" ;
VAL_ 315 VCU_VehicleDirectS 1 "Backward" 0 "Forward" ;
VAL_ 315 VCU_VehicleDirectS_VD 1 "Invaild" 0 "Valid" ;
VAL_ 315 VCU_VehicleDirectVD 1 "Invalid" 0 "Valid" ;
VAL_ 315 VCU_MDrvControlModeVD 1 "Invalid" 0 "Valid" ;
VAL_ 315 VCU_MDrvRequestTorqueVD 1 "Invalid" 0 "Valid" ;
VAL_ 315 VCU_MDrvRequesSpeedVD 1 "Invalid" 0 "Valid" ;
VAL_ 315 VCU_SDrvRequestTorqueVD 1 "Invalid" 0 "Valid" ;
VAL_ 315 VCU_SDrvRequesSpeedVD 1 "Invalid" 0 "Valid" ;
VAL_ 315 VCU_SDrvControlModeVD 1 "Invalid" 0 "Valid" ;
VAL_ 315 VCU_VehicleHighVoltMode 4 "启动失败" 3 "启动完成" 2 "启动" 1 "自检" 0 "下电模式_" ;
VAL_ 315 VCU_PDUHVIL_Sts 1 "_Connected" 0 "_Not_Connected" ;
VAL_ 315 VCU_PDU220VRelay_Req 1 "Active" 0 "Not_Active" ;
VAL_ 315 VCU_Cab220VRelay_Req 1 "Active" 0 "Not_Active" ;
VAL_ 315 VCU_Cabin220VRelay_Req 1 "Active" 0 "Not_Active" ;
VAL_ 315 VCU_Alw_Cab220VInverter_Sts 1 "Allow" 0 "Not_Allow" ;
VAL_ 315 VCU_Alw_Cabin220VInverter_Sts 1 "Allow" 0 "Not_Allow" ;
VAL_ 315 VCU_BCM_Authentication_Sts 3 "认证超时" 2 "认证失败" 1 "认证成功" 0 "Normal" ;
VAL_ 315 VCU_AuthenticationKey_WSts 1 "已写入" 0 "未写入" ;
VAL_ 315 VCU_BrakePedalSts_P 1 "Pressed" 0 "Not_Pressed" ;
VAL_ 315 VCU_BrakePedalStsValid_P 1 "Invalid" 0 "Valid" ;
VAL_ 315 VCU_BoostMode_Fail 3 "_条件不满足，弹射模式无法激活" 2 "_请手动关闭ESC再试" 1 "_弹射模式超时，请重试" 0 "无故障" ;
VAL_ 315 VCU_BoostModeSts 2 "ON" 1 "standby" 0 "OFF" ;
VAL_ 188 VCU_DeliveryModeSts 1 "开启" 0 "关闭" ;
VAL_ 188 VCU_VehSpdLimtRemind 1 "提醒" 0 "无提醒" ;
VAL_ 188 VCU_SinglePedalSts 1 "功能故障" 0 "功能正常" ;
VAL_ 188 VCU_GearLvrChangeSts 6 "Reserved" 5 "驱动配置未写入" 4 "车速不满足" 3 "主缸压力不足" 2 "未踩刹车" 1 "档位不在线" 0 "无异常" ;
VAL_ 188 VCU_HighVoltSysSts 15 "主动放电失败" 14 "车速/转速不满足下电条件" 13 "高压回路未正常断开" 12 "高压回路异常断开" 11 "BMS上电超时或失败" 10 "CDU/PTC通讯丢失导致自检不通过" 9 "电机/电池自检不通过" 8 "其他整车严重故障" 7 "高压互锁故障" 6 "电源过压故障" 5 "碰撞" 4 "前电机通讯故障" 3 "BMS通讯故障" 2 "电机严重故障" 1 "电池严重故障" 0 "无异常" ;
VAL_ 188 VCU_ChrgDischrgFunSts 14 "放电预留里程不足" 13 "无逆变配置" 12 "严重故障(包括高压互锁)" 11 "中止次数过多(BMS请求次数过多或故障次数过多)" 10 "DCDC异常" 9 "维修模式" 8 "充电口过温" 7 "慢充锁未锁" 6 "高压异常" 5 "车速异常" 4 "无充电/逆变请求" 3 "无BMS/OBC充电连接信号" 2 "充电硬线信号电压异常" 1 "未检测到充电硬线信号" 0 "无异常" ;
VAL_ 188 VCU_VehicleNegTrqRspdSts 1 "无法响应" 0 "可以响应" ;
VAL_ 188 VCU_SlopeEst_Valid 1 "Invalid" 0 "Valid" ;
VAL_ 188 VCU_WheelTrqType 8 "Reserved" 7 "SPDLMT" 6 "HDC" 5 "HAC" 4 "APS" 3 "ACC" 2 "CCS" 1 "CREEP" 0 "PED" ;
VAL_ 188 VCU_DriverAssistProhibitSts 1 "disable" 0 "enable" ;
VAL_ 188 VCU_VacumRlySts 1 "Closed" 0 "Opened" ;
VAL_ 188 VCU_DriveSHVILSts 1 "Connected" 0 "Not_Connected" ;
VAL_ 188 VCU_DriveMHVILSts 1 "Connected" 0 "Not_Connected" ;
VAL_ 188 VCU_DCChgHVILSts 1 "Connected" 0 "Not_Connected" ;
VAL_ 188 VCU_ACChgHVILSts 1 "Connected" 0 "Not_Connected" ;
VAL_ 188 VCU_CCMHVILSts 1 "Connected" 0 "Not_Connected" ;
VAL_ 188 VCU_SystemError 1 "Error" 0 "No_Error" ;
VAL_ 188 VCU_AccPedalFaultLV 4 "油门传感器高路故障" 3 "油门传感器低路故障" 2 "油门同步度错误故障" 1 "油门传感器高低路同时故障" 0 "油门传感器无故障" ;
VAL_ 188 VCU_HVILSysSts 12 "GCU端互锁" 11 "前PTC端互锁" 10 "压缩机端互锁" 9 "多合一/CDU端慢充线缆互锁" 8 "多合一/CDU端压缩机互锁" 7 "电池端快充线缆互锁" 6 "电池端GCU互锁" 5 "电池端CDU互锁" 4 "电池端前PTC/WPTC互锁" 3 "电池端压缩机互锁" 2 "电池端辅电机互锁" 1 "电池端主电机互锁" 0 "无故障" ;
VAL_ 188 VCU_LPedalModeSts 3 "reserved" 2 "待激活" 1 "激活" 0 "未激活" ;
VAL_ 188 VCU_LVSystemError 1 "Error" 0 "No_Error" ;
VAL_ 188 VCU_HVSystemError 1 "Error" 0 "No_Error" ;
VAL_ 188 VCU_OpeartingMode 3 "升级模式" 2 "充电模式" 1 "行车模式" 0 "下电模式" ;
VAL_ 188 VCU_EnergyMode 4 "动力优先" 3 "极限纯电" 2 "油电混合" 1 "燃油优先" 0 "纯电优先" ;
VAL_ 188 VCU_GearLevelPosFault 1 "Fault" 0 "No_Fault" ;
VAL_ 188 VCU_BrakeSwitchSts 2 "Error" 1 "Pressed" 0 "Not_Pressed" ;
VAL_ 188 VCU_SpdLimModeSts 1 "限速模式激活成功" 0 "限速模式未激活" ;
VAL_ 188 VCU_TrqDstrbutnPrio 7 "Reserved" 6 "OnlyRearAxle" 5 "OnlyFrontAxle" 4 "UserDefine" 3 "InitDistribution" 2 "EfficiencyFirst" 1 "DynamicFirst" 0 "None" ;
VAL_ 188 VCU_TrqDstrbutnTransferSts 7 "Reserved" 6 "Reserved" 5 "Reserved" 4 "Reserved" 3 "LMCRequest" 2 "VCUSlipTrqTransfer" 1 "TrqTransferInhibt" 0 "NoneTransfer" ;
VAL_ 188 VCU_MCUMDiffProtectSts 1 "Active" 0 "Not_Active" ;
VAL_ 188 VCU_MCUSDiffProtectSts 1 "Active" 0 "Not_Active" ;
VAL_ 188 VCU_ADM_MainMode 3 "Reserve" 2 "Sport" 1 "Normal" 0 "Comfort" ;
VAL_ 188 VCU_ADM_ActualMode 3 "Reserve" 2 "Sport" 1 "Normal" 0 "Comfort" ;
VAL_ 856 VCU_MotSelfHeatAllwd 1 "Permission" 0 "Prohibit" ;
VAL_ 856 VCU_MMotSelfHeatEnReq 1 "Permission" 0 "Prohibit" ;
VAL_ 856 VCU_MMotSelfHeatLvlReq 7 "Reserved" 6 "Reserved" 5 "Level_5" 4 "Level_4" 3 "Level_3" 2 "Level_2" 1 "Level_1" 0 "No_Request" ;
VAL_ 856 VCU_SMotSelfHeatEnReq 1 "Permission" 0 "Prohibit" ;
VAL_ 856 VCU_SMotSelfHeatLvlReq 7 "Reserved" 6 "Reserved" 5 "Level_5" 4 "Level_4" 3 "Level_3" 2 "Level_2" 1 "Level_1" 0 "No_Request" ;
VAL_ 856 VCU_MotSelfHeatLvlFb 9 "Level_9" 8 "Level_8" 7 "Level_7" 6 "Level_6" 5 "Level_5" 4 "Level_4" 3 "Level_3" 2 "Level_2" 1 "Level_1" 0 "No_Request" ;
VAL_ 1300 VCU_SVSLamp 1 "Display" 0 "Not_Display" ;
VAL_ 1300 VCU_MilLamp 1 "Display" 0 "Not_Display" ;
VAL_ 1300 VCU_SinglePedalSts 1 "功能故障" 0 "功能正常" ;
VAL_ 1300 VCU_GearLevelPosFault 1 "功能故障" 0 "功能正常" ;
VAL_ 1300 VCU_EngineStartFailure 1 "Fault" 0 "No_Fault" ;
VAL_ 1300 VCU_ParkBeforeFuelup 1 "Display" 0 "Not_Display" ;
VAL_ 1300 VCU_REsystemFaultSts 1 "Fault" 0 "No_Fault" ;
VAL_ 1300 VCU_EngineRunAllowFlg 1 "Allow" 0 "Not_Allow" ;
VAL_ 1300 VCU_InverterTip 0 "Reserved" 3 "放电功能故障，放电停止" 2 "续驶里程低，放电停止" 1 "电池电量低，发动机启动" 0 "无提示" ;
VAL_ 1300 VCU_EMSRepairModeSts 2 "TRUE" 1 "FALSE" 0 "No_Active_" ;
VAL_ 1300 VCU_FuelTankFlapSts 1 "Open" 0 "Close" ;
VAL_ 1300 VCU_REsystemSts 1 "Ready" 0 "Not_Ready" ;
VAL_ 1300 VCU_PowerModeAllow 2 "Allow" 1 "Not_Allow" 0 "Invalid" ;
VAL_ 1300 VCU_PowerModeSwitchMsg 1 "Display" 0 "Not_Display" ;
VAL_ 1300 VCU_HighVoltFailed_M 1 "Display" 0 "Not_Display" ;
VAL_ 1300 VCU_HighVoltFailed_S 1 "Display" 0 "Not_Display" ;
VAL_ 1300 VCU_BrakeBeforeGear 1 "Display" 0 "Not_Display" ;
VAL_ 1300 VCU_ParkBeforeGear 1 "Display" 0 "Not_Display" ;
VAL_ 1300 VCU_GearBeforDriving 1 "Display" 0 "Not_Display" ;
VAL_ 1300 VCU_UnlockBeforeDriving 1 "Display" 0 "Not_Display" ;
VAL_ 1300 VCU_PreventSliding 1 "Display" 0 "Not_Display" ;
VAL_ 1300 VCU_MMErrorSts 1 "Fault" 0 "No_Fault" ;
VAL_ 1300 VCU_ShowCarModeSts 1 "展车模式" 0 "非展车模式" ;
VAL_ 1300 VCU_PGearFlashSts 1 "Active" 0 "No_active" ;
VAL_ 1300 VCU_ACConnectSts 1 "ON" 0 "OFF" ;
VAL_ 1300 VCU_DcChgPwrSts 1 "ON" 0 "OFF" ;
VAL_ 1300 VCU_DriverAssistProhibitSts 1 "disable" 0 "enable" ;
VAL_ 1300 VCU_MilLampRequest 1 "Request" 0 "No_Request" ;
VAL_ 1300 VCU_FuelDectionModeSts 2 "True" 1 "False" 0 "Not_Active" ;
VAL_ 1300 VCU_EnergyCtrlMode 1 "电量保持模式" 0 "电量消耗模式_" ;
VAL_ 1300 VCU_VehSpdLimtRemind 1 "提醒" 0 "无提醒" ;
VAL_ 1300 VCU_TurtleLamp 1 "Display" 0 "Not_Display" ;
VAL_ 1300 VCU_EngLongTimeStartReq 1 "Request" 0 "Not_Request" ;
VAL_ 588 ICU_AccelerationMode 7 "Reserved" 6 "Reserved" 5 "Reserved" 4 "Economici_Mode" 3 "Extreme+" 2 "Extreme" 1 "Sport_Mode" 0 "Comfort_Mode" ;
VAL_ 588 ICU_REMode 4 "动力优先" 3 "极限纯电" 2 "油电混合" 1 "燃油优先" 0 "纯电优先" ;
VAL_ 588 ICU_CreepMode 3 "Reserved" 2 "回收到0" 1 "开" 0 "关" ;
VAL_ 588 ICU_EnergyRecoveryMode 3 "Reserved" 2 "弱" 1 "中" 0 "强" ;
VAL_ 588 ICU_PHEVMode 1 "燃油优先" 0 "纯电优先" ;
VAL_ 585 ICU_Switch_CLTCOrWLTC 3 "增程WLTC" 2 "增程CLTC" 1 "纯电WLTC" 0 "纯电CLTC" ;
VAL_ 657 BCM_ShutdownMode 1 "激活" 0 "未激活" ;
VAL_ 657 BCM_KeyPosition_ON2A 1 "ON" 0 "Off" ;
VAL_ 657 BCM_CcmHvilSts 1 "Connected" 0 "Not_Connected" ;
VAL_ 657 BCM_ON2BRelaySts 1 "Closed" 0 "Opened" ;
VAL_ 657 BCM_ON2CRelaySts 1 "Closed" 0 "Opened" ;
VAL_ 657 BCM_ON2InitiativeSts 1 "ON" 0 "Off" ;
VAL_ 657 BCM_VehicleRepairMode 1 "Repairing_Mode" 0 "Normal_Mode" ;
VAL_ 657 BCM_VehlockCtrl 3 "unlock_driver_door（预留）" 2 "Lock" 1 "Unlock" 0 "No_Control" ;
VAL_ 657 BCM_VehLockSts 1 "Locked" 0 "Unlocked" ;
VAL_ 657 BCM_FuelTankLockReq 3 "Not_Available" 2 "Lock" 1 "Unlock" 0 "No_Control" ;
VAL_ 657 BCM_ACChgLockCtrl 3 "Not_Available" 2 "Lock" 1 "Unlock" 0 "No_Control" ;
VAL_ 657 BCM_ChargeLockCtrl 3 "Not_Available" 2 "Lock" 1 "Unlock" 0 "No_Control" ;
VAL_ 657 BCM_DCChrgPwr_Sts 1 "VALID" 0 "INVALID" ;
VAL_ 657 BCM_ACChrgPwr_Sts 1 "VALID" 0 "INVALID" ;
VAL_ 657 BCM_KeyPosition_ON2B 1 "ON" 0 "Off" ;
VAL_ 657 BCM_NM_PNC_ON_1ADr_Sts 1 "ON" 0 "Off" ;
VAL_ 657 BCM_NM_PNC_ON_3Ch_Sts 1 "ON" 0 "Off" ;
VAL_ 657 BCM_HighVoltageReq 3 "Reserved" 2 "On" 1 "Off" 0 "No_control" ;
VAL_ 658 BCM_VCU_Authentication_Sts 3 "认证超时" 2 "认证失败" 1 "认证成功" 0 "Normal" ;
VAL_ 658 BCM_PTCLossMissErr 1 "Fault" 0 "No_Fault" ;
VAL_ 658 BCM_PTCRollCntErr 1 "Fault" 0 "No_Fault" ;
VAL_ 658 BCM_PTCChksumErr 1 "Fault" 0 "No_Fault" ;
VAL_ 658 BCM_PDUHVIL_STs 1 "Connected" 0 "Not_Connected" ;
VAL_ 658 BCM_Cab220VHVIL_STs 1 "Connected" 0 "Not_Connected" ;
VAL_ 658 BCM_Cabin220VHVIL_STs 1 "Connected" 0 "Not_Connected" ;
VAL_ 945 GW_ZCUB_FuelTankSts 1 "Open" 0 "Close" ;
VAL_ 945 GW_ZCUB_FuelTankStsLockSts 3 "reserve" 2 "Fault" 1 "Locked" 0 "Unlocked" ;
VAL_ 945 GW_ZCUB_FuelTankLockCtrl 3 "Not_Available" 2 "Lock" 1 "Unlock" 0 "No_Control" ;
VAL_ 945 GW_ZCUB_ACChgLockSts 3 "reserve" 2 "Fault" 1 "Locked" 0 "Unlocked" ;
VAL_ 945 GW_RZCU_Cabin_220Vconnect_Sts 1 "Connect" 0 "No_Connect" ;
VAL_ 945 GW_ZCUB_Cab_220VRelay_CtrlSts 1 "Active" 0 "No_Active" ;
VAL_ 945 GW_ZCUB_Cab_PDU220VRelay_CtrlSts 1 "Active" 0 "No_Active" ;
VAL_ 945 GW_ZCUB_Cabin_220VRelay_CtrlSts 1 "Fault" 0 "No_Fault" ;
VAL_ 945 GW_ZCUB_Cab_220Vconnect_Sts 1 "Connect" 0 "No_Connect" ;
VAL_ 779 GW_TCM_ParkingSwSts 3 "Reserved" 2 "Reserved" 1 "Active" 0 "Not_Active" ;
VAL_ 779 GW_TCM_STATUS_Park 1 "NoFlt" 0 "Flault" ;
VAL_ 779 GW_TCM_GearLevelSwitchSts 5 "Reserved" 4 "下拨二档" 3 "下拨一档" 2 "上拨二档" 1 "上拨一档" 0 "原位" ;
VAL_ 779 GW_TCM_STATUS_RND 1 "NoFlt" 0 "Flault" ;
VAL_ 779 GW_TCM_SelfCheckSt 0 "自检未完成" ;
VAL_ 842 IVI_DeliveryModeReq 3 "reserved" 2 "开启" 1 "关闭" 0 "No_Control" ;
VAL_ 842 IVI_ShowCarModeReq 2 "ON" 1 "OFF" 0 "No_Control" ;
VAL_ 984 IVI_FuelDetMode 1 "_on" 0 "_off" ;
VAL_ 984 IVI_EngineIdlingMode 1 "_high" 0 "_low" ;
VAL_ 984 IVI_CarWashMode 1 "Active" 0 "No_Active" ;
VAL_ 984 IVI_CampingModeSW 1 "开" 0 "关" ;
VAL_ 984 IVI_SpeedLimitModeSW 1 "on" 0 "off" ;
VAL_ 984 IVI_FuelupReq 1 "Request" 0 "No_Request" ;
VAL_ 984 IVI_InventerLimitOdometerkmVD 1 "Invalid" 0 "Valid" ;
VAL_ 984 IVI_EMSRepairModeReq 1 "on" 0 "off" ;
VAL_ 984 IVI_ForceChgModeReq 1 "on" 0 "off" ;
VAL_ 984 IVI_ForceChgTargetSOCVD 1 "Valid" 0 "Invalid" ;
VAL_ 984 IVI_AWDModeSW 1 "四驱" 0 "两驱" ;
VAL_ 984 IVI_FuelChgMode 1 "on" 0 "off" ;
VAL_ 984 IVI_FuelChgLevel 2 "high" 1 "medium" 0 "low" ;
VAL_ 202 MCUM_WarningLevel 3 "Level-1_Error(continuous_running)" 2 "Level-2_Error(reduce_power)" 1 "Level-3_Error(stop)" 0 "Normal" ;
VAL_ 202 MCUM_SelfCheckSts 3 "Position_Learning" 2 "Failure" 1 "Finished" 0 "Not_Finished" ;
VAL_ 202 MCUM_DrvMotorWorkSts 3 "Ready" 2 "Not_Work" 1 "Electricity_Generation" 0 "Consumer_Power" ;
VAL_ 202 MCUM_PowerReduceSts 1 "PowerReduce" 0 "Normal" ;
VAL_ 202 MCUM_HWRdcFault 1 "Error" 0 "No_Error" ;
VAL_ 202 MCUM_HighVoltPowerOffReq 1 "Request" 0 "No_Request" ;
VAL_ 202 MCUM_HVILSts 1 "Connected" 0 "Not_Connected" ;
VAL_ 202 MCUM_DragSts 2 "故障不可拖转" 1 "故障但可拖转" 0 "可正常驱动" ;
VAL_ 202 MCUM_CtrlMode 1 "Speed" 0 "Torque" ;
VAL_ 202 MCUM_MILlampReq 1 "Request" 0 "No_Request" ;
VAL_ 202 MCUM_DrvMotorRPMVD 1 "Invalid" 0 "Valid" ;
VAL_ 202 MCUM_ActualTorqueFBVD 1 "Invalid" 0 "Valid" ;
VAL_ 202 MCUM_ActiveReleaseSts 3 "Fail" 2 "Finish" 1 "star" 0 "Normal" ;
VAL_ 202 MCUM_DCChargRelaySts 1 "Close" 0 "Open" ;
VAL_ 202 MCUM_TMS_MotSelfHeatEnSts 1 "Permission_Status" 0 "Prohibit_Status" ;
VAL_ 202 MCUM_TMS_MotSelfHeatLvlFb 7 "Reserved" 6 "Reserved" 5 "Level_5" 4 "Level_4" 3 "Level_3" 2 "Level_2" 1 "Level_1" 0 "No_Request" ;
VAL_ 202 MCUM_RPowerReduceSts 1 "PowerReduce" 0 "Normal" ;
VAL_ 202 MCUM_RCtrlMode 1 "Speed" 0 "Torque" ;
VAL_ 202 MCUM_RWarningLevel 3 "Level-1_Error(continuous_running)" 2 "Level-2_Error(reduce_power)" 1 "Level-3_Error(stop)" 0 "Normal" ;
VAL_ 202 MCUM_RSelfCheckSts 3 "Position_Learning" 2 "Failure" 1 "Finished" 0 "Not_Finished" ;
VAL_ 202 MCUM_RDrvMotorWorkSts 3 "Ready" 2 "Not_Work" 1 "Electricity_Generation" 0 "Consumer_Power" ;
VAL_ 202 MCUM_RCtrlModeVD 1 "Invalid" 0 "Valid" ;
VAL_ 202 MCUM_RHWRdcFault 1 "Error" 0 "No_Error" ;
VAL_ 202 MCUM_RDrvMotorRPMVD 1 "Invalid" 0 "Valid" ;
VAL_ 202 MCUM_RActualTorqueFBVD 1 "Invalid" 0 "Valid" ;
VAL_ 219 MCUS_WarningLevel 3 "Level-1_Error(continuous_running)" 2 "Level-2_Error(reduce_power)" 1 "Level-3_Error(stop)" 0 "Normal" ;
VAL_ 219 MCUS_SelfCheckSts 3 "Position_Learning" 2 "Failure" 1 "Finished" 0 "Not_Finished" ;
VAL_ 219 MCUS_DrvMotorWorkSts 3 "Ready" 2 "Not_Work" 1 "Electricity_Generation" 0 "Consumer_Power" ;
VAL_ 219 MCUS_PowerReduceSts 1 "PowerReduce" 0 "Normal" ;
VAL_ 219 MCUS_HWRdcFault 1 "Error" 0 "No_Error" ;
VAL_ 219 MCUS_HighVoltPowerOffReq 1 "Request" 0 "No_Request" ;
VAL_ 219 MCUS_HVILSts 1 "Connected" 0 "Not_Connected" ;
VAL_ 219 MCUS_DragSts 2 "故障不可拖转" 1 "故障但可拖转" 0 "可正常驱动" ;
VAL_ 219 MCUS_CtrlMode 1 "Speed" 0 "Torque" ;
VAL_ 219 MCUS_MILlampReq 1 "Request" 0 "No_Request" ;
VAL_ 219 MCUS_DrvMotorRPMVD 1 "Invalid" 0 "Valid" ;
VAL_ 219 MCUS_ActualTorqueFBVD 1 "Invalid" 0 "Valid" ;
VAL_ 219 MCUS_ActiveReleaseSts 3 "Fail" 2 "Finish" 1 "star" 0 "Normal" ;
VAL_ 219 MCUS_Clutch_Pos 7 "Invalid" 6 "Reserved" 5 "unknown" 4 "Wheel_closing" 3 "EMS_closing" 2 "Wheel_closed" 1 "EMS_closed" 0 "Stand_by" ;
VAL_ 219 MCUS_Clutch_Fault 7 "position_learning_fault" 6 "position_learning" 5 "Wheel_disconnecting_fault" 4 "EMS_disconnecting_fault" 3 "Dual_connecting_fault" 2 "EMS_connecting_fault" 1 "Wheel_connecting_fault" 0 "no_Fault" ;
VAL_ 219 MCUS_TMS_FrMotSelfHeatEnSts 1 "Permission_Status" 0 "Prohibit_Status" ;
VAL_ 219 MCUS_TMS_FrMotSelfHeatLvlFb 7 "Reserved" 6 "Reserved" 5 "Level_5" 4 "Level_4" 3 "Level_3" 2 "Level_2" 1 "Level_1" 0 "No_Request" ;
VAL_ 219 MCUS_Clutch_1_Pos 7 "Invalid" 6 "Reserved" 5 "unknown（未知未知状态）" 4 "disconnecting（脱开中）" 3 "close（结合）" 2 "closing（结合中）" 1 "SpdAdjust(调速同步及模式切换)" 0 "disconnected（脱开）" ;
VAL_ 219 MCUS_Clutch_2_Pos 7 "Invalid" 6 "Reserved" 5 "unknown（未知未知状态）" 4 "disconnecting（脱开中）" 3 "close（结合）" 2 "closing（结合中）" 1 "SpdAdjust(调速同步及模式切换)" 0 "disconnected（脱开）" ;
VAL_ 219 MCUS_Clutch_1_WarningLevel 3 "Level-3_high" 2 "Level-2_middle" 1 "Level-1_low" 0 "No_Error" ;
VAL_ 219 MCUS_Clutch_2_WarningLevel 3 "Level-3_high" 2 "Level-2_middle" 1 "Level-1_low" 0 "No_Error" ;
VAL_ 417 BMS_Warning_Level 3 "Level-1_Error(Low)" 2 "Level-2_Error" 1 "Level-3_Error(High)" 0 "No_Error" ;
VAL_ 417 BMS_SelfCheck 3 "Reserved" 2 "Failure" 1 "Finished" 0 "Not_Finished" ;
VAL_ 417 BMS_BattChargerSts 6 "Charge_Pause" 5 "Driving_Charging" 4 "Charge_Hold" 3 "Charge_Error" 2 "Charge_Finished" 1 "Praking_Charging" 0 "Not_Charge" ;
VAL_ 417 BMS_RHighVolSts 1 "Connected" 0 "Disconnected" ;
VAL_ 417 BMS_RPreChargeRelayFB 1 "Close" 0 "Open" ;
VAL_ 417 BMS_RPositiveRelayFB 1 "Close" 0 "Open" ;
VAL_ 417 BMS_RNegativeRelayFB 1 "Close" 0 "Open" ;
VAL_ 417 BMS_RPositiveRelay_F 1 "Error" 0 "No_Error" ;
VAL_ 417 BMS_RNegativeRelay_F 1 "Error" 0 "No_Error" ;
VAL_ 417 BMS_RPreChargeFinishSts 3 "Reserved" 2 "Failure" 1 "Not_Failure" 0 "Initialize" ;
VAL_ 417 BMS_MCUMHVILSts 1 "Connected" 0 "Not_Connected" ;
VAL_ 417 BMS_ACPTCHVILSts 1 "Connected" 0 "Not_Connected" ;
VAL_ 417 BMS_PTCHVILSts 1 "Connected" 0 "Not_Connected" ;
VAL_ 417 BMS_CCMHVILSts 1 "Connected" 0 "Not_Connected" ;
VAL_ 417 BMS_CDUHVILSts 1 "Connected" 0 "Not_Connected" ;
VAL_ 417 BMS_DCChgHVILSts 1 "Connected" 0 "Not_Connected" ;
VAL_ 417 BMS_MCUSHVILSts 1 "Connected" 0 "Not_Connected" ;
VAL_ 417 BMS_HVOffSts 1 "Request" 0 "No_request" ;
VAL_ 417 BMS_SeriousWarning_Level 3 "Level-3_high" 2 "Level-2_middle" 1 "Level-1_low" 0 "No_Error" ;
VAL_ 417 BMS_DCChgRelayCloseReq 1 "work" 0 "not_work" ;
VAL_ 417 BMS_DCChgRelayFB 1 "Close" 0 "Open" ;
VAL_ 417 BMS_ChgStopReason 63 "预留" 62 "预留" 61 "预留" 60 "边充电边加热继电器闭合条件不满足" 59 "快充继电器闭合条件不满足" 58 "快充其他故障原因" 57 "预留" 56 "预留" 55 "快充状态报文接收超时" 54 "快充输出准备就绪接收超时" 53 "快充输出准备报文接收超时" 52 "快充输出能力报文接收超时" 51 "快充辨识结果接收超时" 50 "快充辨识报文接收超时" 49 "快充桩发CEM异常" 48 "快充桩配置参数不匹配" 47 "预留" 46 "充电枪连接异常" 45 "正常结束中止时充电机无法停止" 44 "暂停总时长/次数超限" 43 "AC充电CP频率异常" 42 "AC充电CP占空比异常" 41 "AC等待超时" 40 "充电设备故障" 39 "阶段请求报文超时" 38 "阶段确认_FC/FDC_不符" 37 "鉴权失败" 36 "快充继电器粘连" 35 "功能协商失败" 34 "结束阶段超时" 33 "预充及能量传输阶段超时" 32 "输出回路检测阶段超时" 31 "预约设置协商时间超时（预留）" 30 "鉴权阶段超时" 29 "参数配置阶段超时" 28 "充电设备功率不足" 27 "功能协商阶段超时" 26 "快充插座过温故障" 25 "热管理加热速率异常" 24 "慢充CC半连接超时" 23 "预留" 22 "预留" 21 "充电VCU通讯离线" 20 "预留" 19 "传输层传输失败" 18 "预留" 17 "BMS内部故障等级高" 16 "充电中VCU不允许" 15 "充电中高压断开" 14 "预加热切换充电超时" 13 "暂停超时" 12 "充电OBC通讯离线" 11 "慢充插座过温故障" 10 "OBC输出异常" 9 "AC侧充电功率过低" 8 "快充电子锁状态异常" 7 "充电其他原因完成" 6 "检测点3_电压异常" 5 "充电桩正常完成" 4 "检测点2_电压异常" 3 "中控主动完成" 2 "总压满充截止" 1 "单体满充截止" 0 "默认" ;
VAL_ 417 BMS_GCUHVILSts 1 "Connected" 0 "Not_Connected" ;
VAL_ 417 BMS_MILlampReq 1 "Request" 0 "No_Request" ;
VAL_ 417 BMS_IsoRessistanceSts 1 "Abnormal" 0 "Normal" ;
VAL_ 417 BMS_Integrity_Check 1 "启动" 0 "未启动（default）" ;
VAL_ 417 BMS_Precharge_CoolingSts 1 "Cooling_Down" 0 "default" ;
VAL_ 784 BMS_OBCWorkModeCtrl 7 "reserved" 6 "Inverter__All" 5 "Inverter_Inside" 4 "inverter" 3 "constant_Power" 2 "constant_Voltage" 1 "constant_Current" 0 "closed_" ;
VAL_ 784 BMS_ChargerACInput 1 "Connected" 0 "Disconnected" ;
VAL_ 784 BMS_ChargerDCInput 1 "Connected" 0 "Disconnected" ;
VAL_ 784 BMS_ChargeRequest 1 "Request" 0 "Not__Request" ;
VAL_ 784 BMS_InverterRequest 1 "Request" 0 "Not__Request" ;
VAL_ 784 BMS_Req_Cab220VInverter_Sts 1 "Request" 0 "Not__Request" ;
VAL_ 784 BMS_Req_Cabin220VInverter_Sts 1 "Request" 0 "Not__Request" ;
VAL_ 784 BMS_ThermalManageRequest 6 "Reserved" 5 "Reserved" 4 "Heating_Request" 3 "Reserved" 2 "Reserved" 1 "Cooling_Request" 0 "No_Request" ;
VAL_ 784 BMS_PreHeatingState 3 "Reserved" 2 "Finished" 1 "Heating" 0 "waiting" ;
VAL_ 1457 BMS_MODE_t 0 "Reserved" 8 "BMS_MODE_POWER_OFF" 7 "BMS_MODE_SLEEP" 6 "BMS_MODE_AC_CHARGING" 5 "BMS_MODE_DC_CHARGING" 4 "BMS_MODE_DRIVING" 3 "BMS_MODE_STANDBY" 2 "BMS_MODE_FACTORY" 1 "BMS_MODE_PRESLEEP" 0 "BMS_MODE_INIT" ;
VAL_ 608 EVCC_DCAC_ChgMode 2 "交流充电模式" 1 "直流充电模式" 0 "禁止充电" ;
VAL_ 608 EVCC_CP_status 4 "C2（6V_PWM）" 3 "C1（6V_DC）" 2 "B2（9V_PWM）" 1 "B1（9V_DC）" 0 "A（未插枪）" ;
VAL_ 804 DCDC_WorkSts 3 "PreCharge" 2 "Failure" 1 "Work" 0 "Not_Work" ;
VAL_ 804 DCDC_Under_Output_Voltage 1 "Fault" 0 "No_Fault" ;
VAL_ 804 DCDC_Over_Output_Voltage 1 "Fault" 0 "No_Fault" ;
VAL_ 804 DCDC_Under_Input_Voltage 1 "Fault" 0 "No_Fault" ;
VAL_ 804 DCDC_Over_Input_Voltage 1 "Fault" 0 "No_Fault" ;
VAL_ 804 DCDC_Over_Input_Current 1 "Fault" 0 "No_Fault" ;
VAL_ 804 DCDC_Derating 1 "Derating" 0 "No_Derating" ;
VAL_ 804 DCDC_Hardware_Fault_Flag 1 "Fault" 0 "No_Fault" ;
VAL_ 804 CDU_ACChg_HIVSts 1 "connected" 0 "disconnected" ;
VAL_ 804 CDU_OBC_OverTemp 1 "Fault" 0 "No_Fault" ;
VAL_ 804 CDU_SelfCheckSt 1 "自检完成" 0 "自检未完成" ;
VAL_ 804 CDU_HV_HIVSts 1 "connected" 0 "disconnected" ;
VAL_ 790 OBC_WorkSts 7 "Inverter_All" 6 "Inverter_Inside" 5 "Failure" 4 "PreSleep" 3 "Inverter" 2 "Charging" 1 "Idle" 0 "SelfChecking" ;
VAL_ 790 OBC_StartSts 1 "Abnormal" 0 "Normal" ;
VAL_ 790 OBC_DCSts 1 "Abnormal" 0 "Normal" ;
VAL_ 790 OBC_ACChargeOutputSts 1 "Output" 0 "No_output" ;
VAL_ 790 OBC_HardwareSts 1 "Abnormal" 0 "Normal" ;
VAL_ 790 OBC_CCConnectSts 3 "parital_connect" 2 "inverter_connect" 1 "charger_connect" 0 "disconnect" ;
VAL_ 790 OBC_CPDutyCycleFault 1 "fault" 0 "no_fault" ;
VAL_ 790 OBC_ACPowerState 3 "三相交流电" 2 "缺相" 1 "单相交流电" 0 "无AC电" ;
VAL_ 549 IBS_Warning_Level 3 "Level-3Error(High)" 2 "Level-2Error" 1 "Level-1Error(Low)" 0 "No_Error" ;
VAL_ 189 GCU_SystemWarning 1 "Fault" 0 "No_Fault" ;
VAL_ 189 GCU_MILlampReq 1 "Request" 0 "No_Request" ;
VAL_ 189 GCU_SelfCheck 3 "Reserved" 2 "Failure" 1 "Finished" 0 "Not_Finished" ;
VAL_ 189 GCU_Warning_Level 3 "Level-1_Error(Low)" 2 "Level-2_Error" 1 "Level-3_Error(High)" 0 "No_Error" ;
VAL_ 189 GCU_HVILSts 1 "_connect" 0 "_Disconnect" ;
VAL_ 189 GCU__PowerReduceSts 1 "PowerReduce" 0 "Normal" ;
VAL_ 189 GCU_ActualMotorRPM_VD 1 "Valid" 0 "Invalid" ;
VAL_ 189 GCU_ActualMotorTorque_VD 1 "Valid" 0 "Invalid" ;
VAL_ 189 GCU_EngineFuelInhibitReq 1 "Fuel_inhibit" 0 "No_Request" ;
VAL_ 189 GCU_ActiveReleaseFB 3 "Fail" 2 "Finish" 1 "star" 0 "Normal" ;
VAL_ 189 GCU_HVOffReq 1 "Request" 0 "No_Request" ;
VAL_ 189 GCU_ControlMode 3 "standby(未开管，无输出)" 2 "Volt（预留）" 1 "Speed" 0 "Torque" ;
VAL_ 189 GCU_Operating_Mode 7 "PowerOff(下电)" 6 "AfterRun(运行后)" 5 "ShutDown(关闭)" 4 "Fault（故障状态）" 3 "Normal(正常运行，开管)" 2 "Standby(待机，未开管)" 1 "Init(初始化)" 0 "Default(默认值)" ;
VAL_ 189 GCU_EngineCylinderDeactivationSt 3 "Fail" 2 "In_Process" 1 "Success" 0 "Inactive" ;
VAL_ 190 ECM_EngineSts 7 "Power_Off_Delay" 6 "Stopped" 5 "Stopping" 4 "Stall" 3 "Running" 2 "Crank" 1 "Key_On" 0 "Power_Off" ;
VAL_ 190 ECM_FaultLevel 3 "Level-3" 2 "Level-2" 1 "Level-1" 0 "Normal" ;
VAL_ 190 ECM_ActualEngineTorqueValid 1 "Valid" 0 "Invalid" ;
VAL_ 190 ECM_EngineSpeedValid 1 "Valid" 0 "Invalid" ;
VAL_ 190 ECM_EngineStopAllow 1 "Stop_allowed" 0 "Stop_not_allowed" ;
VAL_ 190 ECM_EngineOilPressureLow 1 "True" 0 "False" ;
VAL_ 190 ECM_EngineFuleCutoffSts 1 "_Fule_cut_active" 0 "_Not_active" ;
VAL_ 190 ECM_EngineStartedCompleted 1 "True" 0 "False" ;
VAL_ 190 ECM_CatalystWarmUpSts 1 "Enable" 0 "Disable" ;
VAL_ 190 ECM_CatalystWarmUpReq 1 "Request" 0 "No_Request" ;
VAL_ 190 ECM_IdleActive 1 "Active" 0 "No_Active" ;
VAL_ 190 ECM_EngineStartReq 0 "Reserved" 3 "冷却液温度高请求发动机启动" 2 "机油温度高请求发动机启动" 1 "碳罐负荷高请求发动机启动" 0 "无请求" ;
VAL_ 190 ECM_GPFRegenlamp 3 "Critical_soot_level" 2 "Regeneration_active" 1 "Regeneration_request" 0 "OFF" ;
VAL_ 190 ECM_EngineCoolantTempValid 1 "Valid" 0 "Invalid" ;
VAL_ 190 ECM_FVVSts 2 "Fault" 1 "True" 0 "False" ;
VAL_ 190 ECM_learningReq 1 "Request" 0 "No_Request" ;
VAL_ 190 ECM_EngineIdleStateRequest 1 "Request" 0 "No_Request" ;
VAL_ 190 ECM_EngineDFCOConditionRequest 1 "Request" 0 "No_Request" ;
VAL_ 190 ECM_GPFRegenReq 1 "Request" 0 "No_Request" ;
VAL_ 190 ECM_SVSLampRequest 1 "Lamp_on_request" 0 "No_request" ;
VAL_ 190 ECM_TankPressureValid 1 "True" 0 "False" ;
VAL_ 190 ECM_MilLampRequest 2 "Lamp_Flash" 1 "Lamp_on_request" 0 "No_request" ;
VAL_ 190 ECM_ToothlearningSucValid 3 "Reserved" 2 "学习失败" 1 "学习成功" 0 "未学习" ;
VAL_ 190 ECM_FuelCloseLoopSts 1 "CloseLoop" 0 "OpenLoop" ;
VAL_ 190 ECM_FuelLevelSensorValid 1 "Valid" 0 "Invalid" ;
VAL_ 190 ECM_SelfCheckSt 0 "自检未完成" ;
VAL_ 190 ECM_PCVPipeDiagReq 1 "Request" 0 "No_Request" ;
VAL_ 190 ECM_ClearingSparkcarbonedRequest 2 "Clearing" 1 "Request_" 0 "No_Request" ;
VAL_ 187 VCU_PowerReducetSts 1 "PowerReduce" 0 "Normal" ;
VAL_ 187 VCU_GCUAassistFB 1 "_不允许" 0 "_允许" ;
VAL_ 187 VCU_GCUActiveReleaseCmd 1 "Active" 0 "Not_Active" ;
VAL_ 187 VCU_PowerOverSts 1 "Request" 0 "No_Request" ;
VAL_ 187 VCU_GCUControlMode 1 "Speed_control_mode" 0 "Torque_control_mode" ;
VAL_ 187 VCU_RoughRoadDetectionFlag 1 "Request" 0 "NotRequest" ;
VAL_ 187 VCU_EngineStartReq 1 "Engine_start_request" 0 "No_Request" ;
VAL_ 187 VCU_EngineFuelInhibitReq 1 "Fuel_inhibit" 0 "No_Request" ;
VAL_ 187 VCU_EngineOffRequest 1 "Stop_request" 0 "No_Request" ;
VAL_ 187 VCU_STorqueReqValid 1 "Valid" 0 "Invalid" ;
VAL_ 187 VCU_FTorqueSwFb 1 "Fast_Torque" 0 "No_Request" ;
VAL_ 187 VCU_FVVOpenReq 1 "True" 0 "False" ;
VAL_ 187 VCU_WarmUpCycleIndicator 1 "True" 0 "False" ;
VAL_ 187 VCU_EngineResetSts 1 "Request" 0 "No_Request" ;
VAL_ 187 VCU_EngineSts 9 "Reserved" 8 "WarmUpCycle" 7 "Power_Off_Delay" 6 "Stopped" 5 "Stopping" 4 "Engine_stop_request" 3 "RunCmpt" 2 "Running" 1 "Engine_start_request" 0 "Power_Off" ;
VAL_ 187 VCU_FTorqueReqValid 1 "Valid" 0 "Invalid" ;
VAL_ 187 VCU_EngineIdleReq 1 "True" 0 "False" ;
VAL_ 187 VCU_REsystemSts 1 "Ready" 0 "Not_Ready" ;
VAL_ 187 VCU_REsystemFaultSts 1 "Fault" 0 "No_Fault" ;
VAL_ 187 VCU_EngineRunAllowFlg 1 "Allow" 0 "Not_Allow" ;
VAL_ 187 VCU_EngineIdleSpeed 2 "High" 1 "Low" 0 "No_Request" ;
VAL_ 187 VCU_EngineFuleCutoffReq 1 "Fule_cut_off" 0 "No_Request" ;
VAL_ 187 VCU_MCUSClutchPosition 3 "reserved" 2 "发电机侧" 1 "发动机侧" 0 "中间位置" ;
VAL_ 187 VCU_MGCUWorkMode 3 "reserved" 2 "驱动状态" 1 "发电状态" 0 "默认状态" ;
VAL_ 187 VCU_Clutch1Position 1 "结合" 0 "脱开" ;
VAL_ 187 VCU_Clutch2Position 1 "结合" 0 "脱开" ;
VAL_ 187 VCU_EVSingleAllow_PHEV 1 "Allow" 0 "NotAllow" ;
VAL_ 187 VCU_EVDualAllow_PHEV 1 "Allow" 0 "NotAllow" ;
VAL_ 187 VCU_REAllow_PHEV 1 "Allow" 0 "NotAllow" ;
VAL_ 187 VCU_HEVAllow_PHEV 1 "Allow" 0 "NotAllow" ;
VAL_ 187 VCU_WorkMode_PHEV 4 "Stand_by" 3 "HEV" 2 "RE" 1 "EV_Dualmotor" 0 "EV_Singlemotor" ;
VAL_ 187 VCU_WorkModeReq_PHEV 3 "HEVReq" 2 "REReq" 1 "EV_DualReq" 0 "EV_SingleReq" ;
VAL_ 187 VCU_Clutch_1_RequesSpeedValid 1 "Valid" 0 "Invalid" ;
VAL_ 187 VCU_Clutch_2_RequesSpeedValid 1 "Valid" 0 "Invalid" ;
VAL_ 187 VCU_FuelChgModeSts 2 "True" 1 "False" 0 "Not_Active" ;
VAL_ 187 VCU_FuelChgModeMsg 3 "功能不支持开启" 2 "请挂P档" 1 "电量过高，_无法开启" 0 "无提示" ;
VAL_ 187 VCU_EngPreStartFlg 1 "激活" 0 "未激活" ;
VAL_ 222 VCU_BrkPedOpen 1 "VALID" 0 "INVALID" ;
VAL_ 222 VCU_BrkPedClose 1 "VALID" 0 "INVALID" ;
VAL_ 222 VCU_ColumnShiftP 1 "VALID" 0 "INVALID" ;
VAL_ 222 VCU_VehiCrashSts 1 "碰撞" 0 "未碰撞" ;
VAL_ 222 VCU_SleepSatisfiedSts 1 "不允许" 0 "允许" ;
VAL_ 222 VCU_VehiHvCmd 1 "ON" 0 "OFF" ;
VAL_ 222 VCU_GearQuitAps 1 "Request" 0 "No_Request" ;
VAL_ 222 VCU_REOverChgPwrFlag 1 "激活" 0 "未激活" ;
VAL_ 222 VCU_HvOffSts 9 "HV_OFF_DONE" 8 "HV_OFF_DISCHG_ACTIVE" 7 "HV_OFF_DISCHG_CHK" 6 "HV_OFF_RELAY_OPEN" 5 "HV_OFF_RELAY_OPEN_CHK" 4 "HV_OFF_LOAD_OFF" 3 "HV_ON_FAILURE" 2 "HV_ON_DONE" 1 "HV_ON_START" 0 "HV_ON_CHK" ;
VAL_ 222 VCU_ElecPwrBalanceReq 1 "激活" 0 "未激活" ;
VAL_ 222 VCU_CDU_RecvTr 1 "已接收" 0 "未接收" ;
VAL_ 222 VCU_BMS_RecvTr 1 "已接收" 0 "未接收" ;
VAL_ 222 VCU_IVI_RecvTr 1 "已接收" 0 "未接收" ;
VAL_ 222 VCU_GCU_RecvTr 1 "已接收" 0 "未接收" ;
VAL_ 222 VCU_TCM_RecvTr 1 "已接收" 0 "未接收" ;
VAL_ 222 VCU_PTC_RecvTr 1 "已接收" 0 "未接收" ;
VAL_ 222 VCU_LossFctorFlgFL 1 "激活" 0 "未激活" ;
VAL_ 222 VCU_HighPerforDisable 1 "请求" 0 "不请求" ;
VAL_ 222 VCU_LossFctorFlgFR 1 "激活" 0 "未激活" ;
VAL_ 222 VCU_LossFctorFlgRL 1 "激活" 0 "未激活" ;
VAL_ 222 VCU_LossFctorFlgRR 1 "激活" 0 "未激活" ;
VAL_ 222 VCU_WheelPwrOvrLimitflgRE 1 "激活" 0 "未激活" ;
VAL_ 222 VCU_HighPerforSwtFlg 1 "满足" 0 "不满足" ;
VAL_ 222 VCU_MDrvFilterTrqRange 7 "POWER_POS" 6 "ZEROCROSS_POS_OUT" 5 "ZEROCROSS_POS_IN" 4 "BRAKING_POS" 3 "POWER_NEG" 2 "ZEROCROSS_NEG_OUT" 1 "ZEROCROSS_NEG_IN" 0 "BRAKING_NEG" ;
VAL_ 222 VCU_MRDrvControlMode 1 "Speed" 0 "Torque" ;
VAL_ 222 VCU_MRDrvControlModeVD 1 "Invalid" 0 "Valid" ;
VAL_ 222 VCU_VehicleDirectMR 1 "Backward" 0 "Forward" ;
VAL_ 222 VCU_VehicleDirectMRVD 1 "Invalid" 0 "Valid" ;
VAL_ 222 VCU_MRDrvRequestTorqueVD 1 "Invalid" 0 "Valid" ;
VAL_ 222 VCU_MRDrvRequesSpeedVD 1 "Invalid" 0 "Valid" ;
VAL_ 222 VCU_SuppressJitterMCUMRRequest 1 "Request" 0 "No_Request" ;
VAL_ 857 VCU_EolCfg_ESC 1 "ESC" 0 "ABS" ;
VAL_ 857 VCU_EolCfg_EPB 1 "有" 0 "无" ;
VAL_ 857 VCU_EolCfg_AEB 1 "有" 0 "无" ;
VAL_ 857 VCU_EolCfg_InverterFunc 1 "有" 0 "无" ;
VAL_ 857 VCU_EolCfg_APS 1 "有" 0 "无" ;
VAL_ 857 VCU_EolCfg_VehiModels 1 "D21" 0 "D13" ;
VAL_ 857 VCU_EolCfg_Curise 3 "保留" 2 "自适应巡航" 1 "定速巡航" 0 "无" ;
VAL_ 857 VCU_REStartReq 1 "请求" 0 "无请求" ;
VAL_ 857 VCU_REStopReq 1 "请求" 0 "无请求" ;
VAL_ 857 VCU_EolCfg_VehiType 1 "增程" 0 "纯电" ;
VAL_ 857 VCU_EolCfg_MotDrvStructure 3 "保留" 2 "四驱" 1 "两驱" 0 "未配置" ;
VAL_ 857 VCU_WLTCModeFlag 1 "不满足" 0 "满足" ;
VAL_ 857 VCU_EolCfg_RudderDir 1 "右舵" 0 "左舵" ;
VAL_ 857 VCU_EolCfg_DCChgRelayPos 1 "快充继电器位置在主电驱" 0 "快充继电器位置在电池" ;
VAL_ 857 VCU_EolCfg_FPTCIL 1 "检测" 0 "不检测" ;
VAL_ 857 VCU_PWakeupSt 1 "已接收" 0 "未接收" ;
VAL_ 857 VCU_SpdLimitReason 6 "SOC" 5 "DeliveryMode" 4 "PwrReduceReq" 3 "MCUMaxRpm" 2 "Gear" 1 "IVI" 0 "NoLimit" ;
VAL_ 857 BSW_VertifySts 3 "校验超时" 2 "校验失败" 1 "校验成功" 0 "未校验" ;
VAL_ 857 VCU_AbResetlnitFinish 1 "Finished" 0 "NotFinished" ;
VAL_ 857 VCU_AbResetFlag 1 "True" 0 "False" ;
VAL_ 857 VCU_AbStartupFlag 1 "True" 0 "False" ;
VAL_ 857 VCU_InterAllowEngStart 1 "允许" 0 "不允许" ;
VAL_ 857 VCU_EngineOff_Flag 1 "请求" 0 "无请求" ;
VAL_ 857 VCU_EngineStopAllow 1 "允许" 0 "不允许" ;
VAL_ 857 VCU_EmergencyStopReq 1 "请求" 0 "无请求" ;
VAL_ 857 VCU_EngineAllowStop 1 "允许" 0 "不允许" ;
VAL_ 857 VCU_ShowCarModeNvmResult 1 "Read_Fail" 0 "Read_Succeed_/_Pending" ;
VAL_ 857 VCU_DeliveryModeNvmData 1 "Read_Fail" 0 "Read_Succeed_/_Pending" ;
VAL_ 857 VCU_AccPedFaultLvNvmResult 1 "Read_Fail" 0 "Read_Succeed_/_Pending" ;
VAL_ 857 VCU_VehicleConfigNvmResult 1 "Read_Fail" 0 "Read_Succeed_/_Pending" ;
VAL_ 857 VCU_EngRunTimeNvmResult 1 "Read_Fail" 0 "Read_Succeed_/_Pending" ;
VAL_ 867 TMS_AC_Command 1 "On" 0 "Off" ;
VAL_ 867 TMS_PTCHeatingReq 1 "On" 0 "Off" ;
VAL_ 867 TMS_OutsideTempVD 1 "Valid" 0 "InValid" ;
VAL_ 1534 TMS_MilLampReq 3 "Reserved" 2 "Reserved" 1 "Lamp_On_Request" 0 "No_Request" ;
VAL_ 1535 TMS_VCU_MotSelfHeatEnReq 1 "Permission" 0 "Prohibit" ;
VAL_ 1535 TMS_VCU_MotSelfHeatLvlReq 9 "Level_9" 8 "Level_8" 7 "Level_7" 6 "Level_6" 5 "Level_5" 4 "Level_4" 3 "Level_3" 2 "Level_2" 1 "Level_1" 0 "No_Request" ;
VAL_ 866 TMS_RAPTC_ModOprtgStsFrt 3 "reserved" 2 "reserved" 1 "on" 0 "off" ;
VAL_ 866 TMS_RAPTC_ModOpEnblCmd 1 "Heater_Operation_Enable" 0 "Heater_Operation_Disable" ;
VAL_ 874 CCM_BaseState 7 "DiagCali" 6 "Reserved" 5 "Error" 4 "PowerUp" 3 "Reserved" 2 "Enable" 1 "Reserved" 0 "Ready" ;
VAL_ 874 CCM_APTC_BscSts 1 "ON" 0 "OFF" ;
VAL_ 871 PTC_BscSts 1 "ON" 0 "OFF" ;
VAL_ 871 PTC_Fault 1 "Fault" 0 "No_Fault" ;
VAL_ 871 PTC_HV_interlock_faultSt 1 "Fault" 0 "No_Fault" ;
VAL_ 1536 VCU_McuPwr12V_OV 1 "Fault" 0 "No_Fault" ;
VAL_ 1536 VCU_McuPwr12V_UV 1 "Fault" 0 "No_Fault" ;
VAL_ 1536 VCU_DcChgPwr_OV 1 "Fault" 0 "No_Fault" ;
VAL_ 1536 VCU_DcChgPwr_UV 1 "Fault" 0 "No_Fault" ;
VAL_ 1536 VCU_AcChgPwr_OV 1 "Fault" 0 "No_Fault" ;
VAL_ 1536 VCU_AcChgPwr_UV 1 "Fault" 0 "No_Fault" ;
VAL_ 1536 VCU_DCDC_FAULT 1 "Fault" 0 "No_Fault" ;
VAL_ 1536 VCU_BrakeSigFault 1 "Fault" 0 "No_Fault" ;
VAL_ 1536 VCU_AccPedHPwr_UV 1 "Fault" 0 "No_Fault" ;
VAL_ 1536 VCU_AccPedHPwr_OV 1 "Fault" 0 "No_Fault" ;
VAL_ 1536 VCU_AccPedLPwr_UV 1 "Fault" 0 "No_Fault" ;
VAL_ 1536 VCU_AccPedLPwr_OV 1 "Fault" 0 "No_Fault" ;
VAL_ 1536 VCU_AccPedHSig_STB 1 "Fault" 0 "No_Fault" ;
VAL_ 1536 VCU_AccPedHSig_OV 1 "Fault" 0 "No_Fault" ;
VAL_ 1536 VCU_AccPedHSig_UV 1 "Fault" 0 "No_Fault" ;
VAL_ 1536 VCU_AccPedHSig_STGorCO 1 "Fault" 0 "No_Fault" ;
VAL_ 1536 VCU_AccPedLSig_STB 1 "Fault" 0 "No_Fault" ;
VAL_ 1536 VCU_AccPedLSig_OV 1 "Fault" 0 "No_Fault" ;
VAL_ 1536 VCU_AccPedLSig_UV 1 "Fault" 0 "No_Fault" ;
VAL_ 1536 VCU_AccPedLSig_STGorCO 1 "Fault" 0 "No_Fault" ;
VAL_ 1536 VCU_AccPedSigSyncFault 1 "Fault" 0 "No_Fault" ;
VAL_ 1536 VCU_CcmOutHvil_STBorCO 1 "Fault" 0 "No_Fault" ;
VAL_ 1536 VCU_CcmOutHvil_STG 1 "Fault" 0 "No_Fault" ;
VAL_ 1536 VCU_CcmOutHvil_SigInvalid 1 "Fault" 0 "No_Fault" ;
VAL_ 1536 VCU_HVIL_FAULT 1 "Fault" 0 "No_Fault" ;
VAL_ 1536 VCU_ACHVIL_FAULT 1 "Fault" 0 "No_Fault" ;
VAL_ 1536 VCU_DCHVIL_FAULT 1 "Fault" 0 "No_Fault" ;
VAL_ 1536 VCU_HVIL_STS_ALARM 1 "Fault" 0 "No_Fault" ;
VAL_ 1536 VCU_MD_HV_Start_Failure_HVIL 1 "Fault" 0 "No_Fault" ;
VAL_ 1536 VCU_MD_HV_Start_Failure_MCUFault 1 "Fault" 0 "No_Fault" ;
VAL_ 1536 VCU_MD_HV_Start_Failure_BMSFault 1 "Fault" 0 "No_Fault" ;
VAL_ 1536 VCU_MD_HV_Start_Failure_OtherFau 1 "Fault" 0 "No_Fault" ;
VAL_ 1536 VCU_DcChagerTempP_OT 1 "Fault" 0 "No_Fault" ;
VAL_ 1536 VCU_DcChagerTempN_OT 1 "Fault" 0 "No_Fault" ;
VAL_ 1536 VCU_AcChagerTempP_OT 1 "Fault" 0 "No_Fault" ;
VAL_ 1536 VCU_EngineStartFailure 1 "Fault" 0 "No_Fault" ;
VAL_ 1536 VCU_EnergyRecoveryProhibit 1 "Fault" 0 "No_Fault" ;
VAL_ 1536 VIU_GW_MissMsg 1 "Fault" 0 "No_Fault" ;
VAL_ 1536 VIU_GW_RollCntErr 1 "Fault" 0 "No_Fault" ;
VAL_ 1536 VIU_GW_ChksumErr 1 "Fault" 0 "No_Fault" ;
VAL_ 1536 VCU_AcChagerTempN_OT 1 "Fault" 0 "No_Fault" ;
VAL_ 1536 VCU_MCUM_SissMsgHigh 1 "Fault" 0 "No_Fault" ;
VAL_ 1536 VCU_AuthenticationKey_Not_Write 1 "Fault" 0 "No_Fault" ;
VAL_ 1536 VCU_BCM_Authentication_Fail_or_T 1 "Fault" 0 "No_Fault" ;
VAL_ 1536 VCU_BrakeSysFault 1 "Fault" 0 "No_Fault" ;
VAL_ 1536 VCU_PGearLeverFault 1 "Fault" 0 "No_Fault" ;
VAL_ 1536 VCU_PGearLeverCounterError 1 "Fault" 0 "No_Fault" ;
VAL_ 1536 VCU_PGearLeverChecksumError 1 "Fault" 0 "No_Fault" ;
VAL_ 1536 VCU_GearChangeLeverFault 1 "Fault" 0 "No_Fault" ;
VAL_ 1536 VCU_GearChangeLeverError 1 "Fault" 0 "No_Fault" ;
VAL_ 1536 VCU_GearChangeLeverChecksumError 1 "Fault" 0 "No_Fault" ;
VAL_ 1536 VCU_CalibrationDataCrc_ERR 1 "Fault" 0 "No_Fault" ;
VAL_ 1536 VCU_CalibrationAppCrc_ERR 1 "Fault" 0 "No_Fault" ;
VAL_ 1536 VCU_CalibrationRead_ERR 1 "Fault" 0 "No_Fault" ;
VAL_ 1536 VCU_MCUM_MissMsgHigh 1 "Fault" 0 "No_Fault" ;
VAL_ 1536 VCU_CalibrationVerifyErr 1 "Fault" 0 "No_Fault" ;
VAL_ 1536 VCU_McuSeriousFaultyFor4WD 1 "Fault" 0 "No_Fault" ;
VAL_ 1536 VCU_McuFaultyFor4WDType1 1 "Fault" 0 "No_Fault" ;
VAL_ 1536 VCU_McuFaultyFor4WDType2 1 "Fault" 0 "No_Fault" ;
VAL_ 1536 VCU_CrashFaulty 1 "Fault" 0 "No_Fault" ;
VAL_ 1536 VCU_MCUS_PrivateCANMissMsg 1 "Fault" 0 "No_Fault" ;
VAL_ 1536 VCU_MCUS_PrivateCANRollCntErr 1 "Fault" 0 "No_Fault" ;
VAL_ 1536 VCU_MCUS_PrivateCANChksumErr 1 "Fault" 0 "No_Fault" ;
VAL_ 1536 VCU_DCDC12VLowFault 1 "Fault" 0 "No_Fault" ;
VAL_ 1536 VCU_ECMRequestMIL 1 "Fault" 0 "No_Fault" ;
VAL_ 1536 VCU_GCURequestMIL 1 "Fault" 0 "No_Fault" ;
VAL_ 1536 VCU_MCURequestMIL 1 "Fault" 0 "No_Fault" ;
VAL_ 1536 VCU_BMSRequestMIL 1 "Fault" 0 "No_Fault" ;
VAL_ 1536 VCU_IBCRequestMIL 1 "Fault" 0 "No_Fault" ;
VAL_ 1536 VCU_TMSRequestMIL 1 "Fault" 0 "No_Fault" ;
VAL_ 1536 VCU_VCURequestMIL 1 "Fault" 0 "No_Fault" ;
VAL_ 1536 VCU_CCANFD_Busoff 1 "Fault" 0 "No_Fault" ;
VAL_ 1536 VCU_PCANFD_Busoff 1 "Fault" 0 "No_Fault" ;
VAL_ 1536 VCU_MCUS_MissMsg 1 "Fault" 0 "No_Fault" ;
VAL_ 1536 VCU_MCUS_RollCntErr 1 "Fault" 0 "No_Fault" ;
VAL_ 1536 VCU_MCUS_ChksumErr 1 "Fault" 0 "No_Fault" ;
VAL_ 1536 VCU_MCUM_MissMsg 1 "Fault" 0 "No_Fault" ;
VAL_ 1536 VCU_MCUM_RollCntErr 1 "Fault" 0 "No_Fault" ;
VAL_ 1536 VCU_MCUM_ChksumErr 1 "Fault" 0 "No_Fault" ;
VAL_ 1536 VCU_BMS_MissMsg 1 "Fault" 0 "No_Fault" ;
VAL_ 1536 VCU_BMS_RollCntErr 1 "Fault" 0 "No_Fault" ;
VAL_ 1536 VCU_BMS_ChksumErr 1 "Fault" 0 "No_Fault" ;
VAL_ 1536 VCU_DCDC_MissMsg 1 "Fault" 0 "No_Fault" ;
VAL_ 1536 VCU_DCDC_RollCntErr 1 "Fault" 0 "No_Fault" ;
VAL_ 1536 VCU_DCDC_ChksumErr 1 "Fault" 0 "No_Fault" ;
VAL_ 1536 VCU_OBC_MissMsg 1 "Fault" 0 "No_Fault" ;
VAL_ 1536 VCU_OBC_RollCntErr 1 "Fault" 0 "No_Fault" ;
VAL_ 1536 VCU_OBC_ChksumErr 1 "Fault" 0 "No_Fault" ;
VAL_ 1536 VCU_ACU_MissMsg 1 "Fault" 0 "No_Fault" ;
VAL_ 1536 VCU_ACU_RollCntErr 1 "Fault" 0 "No_Fault" ;
VAL_ 1536 VCU_ACU_ChksumErr 1 "Fault" 0 "No_Fault" ;
VAL_ 1536 VCU_IBC_MissMsg 1 "Fault" 0 "No_Fault" ;
VAL_ 1536 VCU_IBC_RollCntErr 1 "Fault" 0 "No_Fault" ;
VAL_ 1536 VCU_IBC_ChksumErr 1 "Fault" 0 "No_Fault" ;
VAL_ 1536 VCU_EPS_MissMsg 1 "Fault" 0 "No_Fault" ;
VAL_ 1536 VCU_EPS_RollCntErr 1 "Fault" 0 "No_Fault" ;
VAL_ 1536 VCU_EPS_ChksumErr 1 "Fault" 0 "No_Fault" ;
VAL_ 1536 VCU_BCM_MissMsg 1 "Fault" 0 "No_Fault" ;
VAL_ 1536 VCU_BCM_RollCntErr 1 "Fault" 0 "No_Fault" ;
VAL_ 1536 VCU_BCM_ChksumErr 1 "Fault" 0 "No_Fault" ;
VAL_ 1536 VCU_ICU_MissMsg 1 "Fault" 0 "No_Fault" ;
VAL_ 1536 VCU_ICU_RollCntErr 1 "Fault" 0 "No_Fault" ;
VAL_ 1536 VCU_ICU_ChksumErr 1 "Fault" 0 "No_Fault" ;
VAL_ 1536 VCU_IVI_MissMsg 1 "Fault" 0 "No_Fault" ;
VAL_ 1536 VCU_IVI_RollCntErr 1 "Fault" 0 "No_Fault" ;
VAL_ 1536 VCU_IVI_ChksumErr 1 "Fault" 0 "No_Fault" ;
VAL_ 1536 VCU_ECM_MissMsg 1 "Fault" 0 "No_Fault" ;
VAL_ 1536 VCU_ECM_ChksumErr 1 "Fault" 0 "No_Fault" ;
VAL_ 1536 VCU_ECM_RollCntErr 1 "Fault" 0 "No_Fault" ;
VAL_ 1536 VCU_GCU_MissMsg 1 "Fault" 0 "No_Fault" ;
VAL_ 1536 VCU_GCU_ChksumErr 1 "Fault" 0 "No_Fault" ;
VAL_ 1536 VCU_GCU_RollCntErr 1 "Fault" 0 "No_Fault" ;
VAL_ 1536 VCU_ACC_MissMsg 1 "Fault" 0 "No_Fault" ;
VAL_ 1536 VCU_ACC_RollCntErr 1 "Fault" 0 "No_Fault" ;
VAL_ 1536 VCU_ACC_ChksumErr 1 "Fault" 0 "No_Fault" ;
VAL_ 1536 VCU_APS_MissMsg 1 "Fault" 0 "No_Fault" ;
VAL_ 1536 VCU_APS_RollCntErr 1 "Fault" 0 "No_Fault" ;
VAL_ 1536 VCU_APS_ChksumErr 1 "Fault" 0 "No_Fault" ;
VAL_ 1536 VCU_ParkingSignal_Fault 1 "Fault" 0 "No_Fault" ;
VAL_ 1536 VCU_FSC_Loss_Communication 1 "Fault" 0 "No_Fault" ;
VAL_ 1536 VCU_FSC_Counter_Error 1 "Fault" 0 "No_Fault" ;
VAL_ 1536 VCU_FSC_Checksum_Error 1 "Fault" 0 "No_Fault" ;
VAL_ 1536 VCU_LMC_MissMSg 1 "Fault" 0 "No_Fault" ;
VAL_ 1536 VCU_LMC_ChksumErr 1 "Fault" 0 "No_Fault" ;
VAL_ 1536 VCU_LMC_RollCntErr 1 "Fault" 0 "No_Fault" ;
VAL_ 1536 GW_TCM_MissMsg 1 "Fault" 0 "No_Fault" ;
VAL_ 1536 GW_TCM_RollCntErr 1 "Fault" 0 "No_Fault" ;
VAL_ 1536 GW_TCM_ChksumErr 1 "Fault" 0 "No_Fault" ;
VAL_ 1536 VCU_IBS_LossComm 1 "Fault" 0 "No_Fault" ;
VAL_ 1536 VCU_IBS_CounterErr 1 "Fault" 0 "No_Fault" ;
VAL_ 1536 VCU_IBS_ChecksumErr 1 "Fault" 0 "No_Fault" ;
VAL_ 1536 Dtc_IBS_FAULTHigh 1 "Fault" 0 "No_Fault" ;
VAL_ 1536 VCU_CCM_LossComm 1 "Fault" 0 "No_Fault" ;
VAL_ 1536 VCU_CCM_CounterErr 1 "Fault" 0 "No_Fault" ;
VAL_ 1536 VCU_CCM_ChecksumErr 1 "Fault" 0 "No_Fault" ;
VAL_ 1536 VCU_PTC_LossComm 1 "Fault" 0 "No_Fault" ;
VAL_ 1536 VCU_PTC_CounterErr 1 "Fault" 0 "No_Fault" ;
VAL_ 1536 VCU_PTC_ChecksumErr 1 "Fault" 0 "No_Fault" ;
VAL_ 1536 VCU_TMS_LossComm 1 "Fault" 0 "No_Fault" ;
VAL_ 1536 VCU_TMS_CounterErr 1 "Fault" 0 "No_Fault" ;
VAL_ 1536 VCU_TMS_ChecksumErr 1 "Fault" 0 "No_Fault" ;
VAL_ 1536 VCU_IMU_LossComm 1 "Fault" 0 "No_Fault" ;
VAL_ 1536 VCU_IMU_CounterErr 1 "Fault" 0 "No_Fault" ;
VAL_ 1536 VCU_IMU_ChecksumErr 1 "Fault" 0 "No_Fault" ;
VAL_ 1536 VCU_Prvt_CAN_BUS_OFF 1 "Fault" 0 "No_Fault" ;
VAL_ 1536 VCU_IMU_Cali_CounterErr 1 "Fault" 0 "No_Fault" ;
VAL_ 1536 VCU_ASR_Fault 1 "Fault" 0 "No_Fault" ;
VAL_ 1536 VCU_DTC_Fault 1 "Fault" 0 "No_Fault" ;
VAL_ 1536 VCU_VDC_Fault 1 "Fault" 0 "No_Fault" ;
VAL_ 1536 VCU_ACU_Trigger_Fault 1 "Fault" 0 "No_Fault" ;
VAL_ 1536 VCU_DMC_Front_Motor_Input_Signal 1 "Fault" 0 "No_Fault" ;
VAL_ 1536 VCU_DMC_Rear_Motor_Input_Signal_ 1 "Fault" 0 "No_Fault" ;
